VERSION ""

NS_ :

BS_:

BU_: MCTM_LS TIM_LS EOCM2cp_K2_LS EOCM2cp_K1_LS ADIMa_LS BCM_LS SAM_SR_LS SAM_SL_LS SAM_PR_LS SAM_PL_LS CGM3a_LS Dummy_LS VICM_LS ECC_LS PEPS_LS AOS_LS SDM_PR_LS AOS2_LS DLM_LS SCCM_2_LS SCCM_1_LS UPA_LS ADIMb_LS
VAL_TABLE_ vt_BooleanValues 1 "true" 0 "false" ;
VAL_TABLE_ PwrDrClsReq 1 "No Action" 0 "Power Door Close Active" ;
VAL_TABLE_ PwrDrClsEn 1 "Enable Power Door Close" 0 "No Action" ;
VAL_TABLE_ ADAllWndwMotReq 2 "Down" 1 "Up" 0 "No Action" ;
VAL_TABLE_ VehHlthMngrSt 6 "Normal Operation" 5 "Degraded Mode 5" 4 "Degraded Mode 4" 3 "Degraded Mode 3" 2 "Degraded Mode 2" 1 "Degraded Mode 1" 0 "Initialization" ;
VAL_TABLE_ AutoVehMd 5 "Failed" 4 "Autonomous Unsupervised" 3 "Supervisor Override" 2 "Autonomous Supervised" 1 "Manual" 0 "Unknown" ;
VAL_TABLE_ AutoDrvHrnReq 3 "Continuous On" 2 "Multiple" 1 "Single" 0 "Off" 4 "Vehicle Locator" ;
VAL_TABLE_ HtdStWhlCmd 3 "High" 2 "Medium" 1 "Low" 0 "Off" ;
VAL_TABLE_ HtdStWhlCtrlSrc 1 "Remote Switch Control" 0 "Local Switch Control" ;
VAL_TABLE_ HtdStWhlInd 3 "High" 2 "Medium" 1 "Low" 0 "Off" ;
VAL_TABLE_ LnMrkngIndRgt 3 "Unused and Reserved 1" 2 "Green Indicator" 1 "White Indicator" 0 "Indicator Off" ;
VAL_TABLE_ LnMrkngIndLft 3 "Unused and Reserved 1" 2 "Green Indicator" 1 "White Indicator" 0 "Indicator Off" ;
VAL_TABLE_ LnKepAsstStIndRgt 7 "Unused and Reserved 2" 6 "Unused and Reserved 1" 5 "Yellow Indicator" 4 "Red Indicator" 3 "Blue Indicator" 2 "Green Indicator" 1 "White Indicator" 0 "Indicator Off" ;
VAL_TABLE_ LnKepAsstStIndLft 7 "Unused and Reserved 2" 6 "Unused and Reserved 1" 5 "Yellow Indicator" 4 "Red Indicator" 3 "Blue Indicator" 2 "Green Indicator" 1 "White Indicator" 0 "Indicator Off" ;
VAL_TABLE_ LnKpngAstRecfblIndRq 7 "Unused and Reserved 2" 6 "Unused and Reserved 1" 5 "Yellow Solid Indicator" 4 "Yellow Flashing Indicator" 3 "Blue Solid Indicator" 2 "Green Solid Indicator" 1 "White Solid Indicator" 0 "Indicator Off" ;
VAL_TABLE_ SmrtHgBmAstCstSetReq 7 "Unused and Reserved 5" 6 "Unused and Reserved 4" 5 "Unused and Reserved 3" 4 "Unused and Reserved 2" 3 "Unused and Reserved 1" 2 "Adaptive High Beam" 1 "Auto High Beam" 0 "No Action" ;
VAL_TABLE_ SmrtHgBmAstCstCurrSetVal 7 "Unused and Reserved 5" 6 "Unused and Reserved 4" 5 "Unused and Reserved 3" 4 "Unused and Reserved 2" 3 "Unused and Reserved 1" 2 "Adaptive High Beam" 1 "Auto High Beam" 0 "No Action" ;
VAL_TABLE_ ADLR_LkUlk 2 "Unlock" 1 "Lock" 0 "No Action" ;
VAL_TABLE_ CSRCR1_Cmnd 1 "Revoke Certificate" 0 "No Action" 7 "Unused and Resrved 5" 6 "Unused and Resrved 4" 5 "Unused and Resrved 3" 4 "Unused and Resrved 2" 3 "Unused and Resrved 1" 2 "Revoke All Certificate" ;
VAL_TABLE_ CrShrngRvkCertfctRsp 4 "No CertIDs Stored" 3 "CertID Not Matched" 2 "Revoke Certificate Successful" 1 "Write Failure" 0 "No Action" ;
VAL_TABLE_ CrShrngConnStat 3 "Terminate Connection" 2 "Ignore Connection" 1 "Valid Connection" 0 "No Action" ;
VAL_TABLE_ CSZS_FrntCmptZnMbDevStat 1 "One Or More Mobile Devices Prsnt" 0 "No Mobile Device Present" ;
VAL_TABLE_ CSZS_RrCmptZnMbDevStat 1 "One Or More Mobile Devices Prsnt" 0 "No Mobile Device Present" ;
VAL_TABLE_ CSZS_FrntExtrZnMbDevStat 1 "One Or More Mobile Devices Prsnt" 0 "No Mobile Device Present" ;
VAL_TABLE_ CSZS_RrExtrZnMbDevStat 1 "One Or More Mobile Devices Prsnt" 0 "No Mobile Device Present" ;
VAL_TABLE_ CSZS_WlcmZnMbDevStat 1 "One Or More Mobile Devices Prsnt" 0 "No Mobile Device Present" ;
VAL_TABLE_ CSZS_IntrZnMbDevStat 3 "Three Mobile Devices Present" 2 "Two Mobile Devices Present" 1 "One Mobile Device Present" 0 "No Mobile Device Present" ;
VAL_TABLE_ CSZS_PassEntyZnMbDevStat 1 "One Or More Mobile Devices Prsnt" 0 "No Mobile Device Present" ;
VAL_TABLE_ CSZS_DrEntyZnMbDevStat 1 "One Or More Mobile Devices Prsnt" 0 "No Mobile Device Present" ;
VAL_TABLE_ RrStRmndrCstSetReq 2 "On" 1 "Off" 0 "No Action" ;
VAL_TABLE_ RrStRmndrCstCurrSetVal 2 "On" 1 "Off" 0 "No Action" ;
VAL_TABLE_ SmPhRmFunCstStReq 7 "Unused and Reserved 5" 6 "Unused and Reserved 4" 5 "Unused and Reserved 3" 4 "Unused and Reserved 2" 3 "Unused and Reserved 1" 2 "On" 1 "Off" 0 "No Action" ;
VAL_TABLE_ SmPhRmFunCstCurStVal 7 "Unused and Reserved 5" 6 "Unused and Reserved 4" 5 "Unused and Reserved 3" 4 "Unused and Reserved 2" 3 "Unused and Reserved 1" 2 "On" 1 "Off" 0 "No Action" ;
VAL_TABLE_ PrtyChrgRqRmt1 2 "Active" 1 "Inactive" 0 "No Action" ;
VAL_TABLE_ HVChgSyChgLvPfStRmt1 4 "Reduced Current Level 3" 3 "Reduced Current Level 2" 2 "Reduced Current Level 1" 1 "No Reduction" 0 "No Action" ;
VAL_TABLE_ HVBTBDCSRR1_DChSnSRq 3 "Yearly" 2 "Winter" 1 "Summer" 0 "No Action" ;
VAL_TABLE_ HVBTBDCSRR1_DChSlSRq 8 "Unused and Reserved 4" 7 "Departure Time 2 Invalid" 6 "Unused and Reserved 3" 5 "Departure Time 2" 4 "Unused and Reserved 2" 3 "Departure Time 1 Invalid" 2 "Unused and Reserved 1" 1 "Departure Time 1" 0 "No Action" ;
VAL_TABLE_ HVBTBDCSRR1_DChDStRq 6 "Friday" 5 "Thursday" 4 "Wednsday" 3 "Tuesday" 2 "Monday" 1 "Sunday" 0 "No Action" 10 "Sat and Sun Same" 9 "Mon To Fri Same" 8 "All Days Same" 7 "Saturday" ;
VAL_TABLE_ HVBatTmBsChgMdRqRmt1 3 "Rate Based Charge" 2 "Delayed Charge" 1 "Charge Now" 0 "No Action" ;
VAL_TABLE_ LnCntrSpchPrmtReq 3 "Unused and Reserved" 2 "Take Vehicle Control" 1 "Take Steering" 0 "No Prompt" ;
VAL_TABLE_ LnCntrEsclnStat 3 "System Faulted" 2 "Limit Condition" 1 "Driver Not Looking to Roadway" 0 "None" ;
VAL_TABLE_ HLOCCstSetReq 3 "On Open Only" 2 "On" 1 "Off" 0 "No Action" ;
VAL_TABLE_ HTRCsStReq 4 "On Away" 3 "On Home" 2 "On" 1 "Off" 0 "No Action" ;
VAL_TABLE_ HTRCsCrStVal 4 "On Away" 3 "On Home" 2 "On" 1 "Off" 0 "No Action" ;
VAL_TABLE_ EngyUsgScrnMeasUtStat 15 "Unused and Reserved 9" 14 "Unused and Reserved 8" 13 "Unused and Reserved 7" 12 "Unused and Reserved 6" 11 "Unused and Reserved 5" 10 "Unused and Reserved 4" 9 "Unused and Reserved 3" 8 "Unused and Reserved 2" 7 "Unused and Reserved 1" 6 "km/L e Combined" 5 "km/L" 4 "L/100km e Combined" 3 "L/100km" 2 "MPGe Combined" 1 "MPG" 0 "No Action" ;
VAL_TABLE_ OBHVBCCompTmDispFrmt 2 "Display Remaining Minutes To Complete" 1 "Display Completion Time" 0 "No Action" ;
VAL_TABLE_ PTExPartFltManRegStat 7 "Reserved 3" 6 "Reserved 2" 5 "Reserved 1" 4 "Complete" 3 "In Progress" 2 "Not Allowed" 1 "Allowed" 0 "Cleaning Not Required" ;
VAL_TABLE_ InfotnmntSysSt 31 " Unused and Reserved 15" 30 " Unused and Reserved 14" 29 " Unused and Reserved 13" 28 " Unused and Reserved 12" 27 " Unused and Reserved 11" 26 " Unused and Reserved 10" 25 " Unused and Reserved 9" 24 " Unused and Reserved 8" 23 " Unused and Reserved 7" 22 " Unused and Reserved 6" 21 " Unused and Reserved 5" 20 " Unused and Reserved 4" 19 " Unused and Reserved 3" 18 " Unused and Reserved 2" 17 " Unused and Reserved 1" 16 " Remote Reflash Programming" 15 " No VIN" 14 " No Calibration" 13 " Theftlocked" 12 " Valet Mode" 11 " Local Eject" 10 " Local Valet" 9 " Local Phone" 8 " Local Infotainment" 7 " Accessory" 6 " Propulsion" 5 " Run" 4 " Start" 3 " HMI Inactive" 2 " HMI Init" 1 " Animation Init" 0 " Sleep" ;
VAL_TABLE_ LnchCtrlWhlSlpReq 31 "Unused and Reserved 10" 30 "Unused and Reserved 9" 29 "Unused and Reserved 8" 28 "Unused and Reserved 7" 27 "Unused and Reserved 6" 26 "Unused and Reserved 5" 25 "Unused and Reserved 4" 24 "Unused and Reserved 3" 23 "Unused and Reserved 2" 22 "Unused and Reserved 1" 21 "Fifteen Percent" 20 "Fourteen And A Half Percent" 19 "Fourteen Percent" 18 "Thirteen And A Half Percent" 17 "Thirteen Percent" 16 "Twelve And A Half Percent" 15 "Twelve Percent" 14 "Eleven And a Half Percent" 13 "Eleven Percent" 12 "Ten And A Half Percent" 11 "Ten Percent" 10 "Nine And A Half Percent" 9 "Nine Percent" 8 "Eight And A Half Percent" 7 "Eight Percent" 6 "Seven And A Half Percent" 5 "Seven Percent" 4 "Six And A Half Percent" 3 "Six Percent" 2 "Five And A Half Percent" 1 "Five Percent" 0 "No Action" ;
VAL_TABLE_ LnchCtrlMdReq 3 "Burn Out" 2 "Custom" 1 "Automatic" 0 "No Action" ;
VAL_TABLE_ LnchCtrlEngRPMReq 24 "3100" 23 "3000" 22 "2900" 21 "2800" 20 "2700" 19 "2600" 18 "2500" 17 "2400" 16 "2300" 15 "2200" 14 "2100" 13 "2000" 12 "1900" 11 "1800" 10 "1700" 9 "1600" 8 "1500" 7 "1400" 6 "1300" 5 "1200" 4 "1100" 3 "1000" 2 "900" 1 "800" 0 "No Action" 63 "Unused and Reserved 30" 62 "Unused and Reserved 29" 61 "Unused and Reserved 28" 60 "Unused and Reserved 27" 59 "Unused and Reserved 26" 58 "Unused and Reserved 25" 57 "Unused and Reserved 24" 56 "Unused and Reserved 23" 55 "Unused and Reserved 22" 54 "Unused and Reserved 21" 53 "Unused and Reserved 20" 52 "Unused and Reserved 19" 51 "Unused and Reserved 18" 50 "Unused and Reserved 17" 49 "Unused and Reserved 16" 48 "Unused and Reserved 15" 47 "Unused and Reserved 14" 46 "Unused and Reserved 13" 45 "Unused and Reserved 12" 44 "Unused and Reserved 11" 43 "Unused and Reserved 10" 42 "Unused and Reserved 9" 41 "Unused and Reserved 8" 40 "Unused and Reserved 7" 39 "Unused and Reserved 6" 38 "Unused and Reserved 5" 37 "Unused and Reserved 4" 36 "Unused and Reserved 3" 35 "Unused and Reserved 2" 34 "Unused and Reserved 1" 33 "4000" 32 "3900" 31 "3800" 30 "3700" 29 "3600" 28 "3500" 27 "3400" 26 "3300" 25 "3200" ;
VAL_TABLE_ ECHGCD_XAxTkMrkInterv 7 "100" 6 "80" 5 "50" 4 "20" 3 "10" 2 "5" 1 "1" 0 "0.5" ;
VAL_TABLE_ ECHGCD_MeasUt 15 "Unused and Reserved 7" 14 "Unused and Reserved 6" 13 "Unused and Reserved 5" 12 "Unused and Reserved 4" 11 "Unused and Reserved 3" 10 "Unused and Reserved 2" 9 "Unused and  Reserved 1" 8 "km per L e Combined" 7 "L per 100km e Combined" 6 "MPGe Combined" 5 "L per 100km" 4 "mi per gal" 3 "km per L" 2 "kWh per 100km" 1 "mi per kWh" 0 "km per kWh" ;
VAL_TABLE_ TrfRdsdInfCsStReq 7 "Reserved5" 6 "Reserved4" 5 "Reserved3" 4 "Reserved2" 3 "Reserved1" 2 "On" 1 "Off" 0 "No Action" ;
VAL_TABLE_ CntdVehBrAltCsStReq 7 "Reserved5" 6 "Reserved4" 5 "Reserved3" 4 "Reserved2" 3 "Reserved1" 2 "On" 1 "Off" 0 "No Action" ;
VAL_TABLE_ IntrStopAlrtCsSetReq 7 "Reserved4" 6 "Reserved3" 5 "Reserved2" 4 "Reserved1" 3 "Alert and Brake" 2 "Alert " 1 "Off" 0 "No Action" ;
VAL_TABLE_ LCWrnIndReq 11 "Take Steering" 10 "Due to Weather" 9 "Can not See Eyes" 8 "Canceled Take Steering" 7 "Adaptive Cruise Disengaging" 6 "Vehicles Too Close" 5 "Excessive Speed" 4 "Construction" 3 "Freeway Ends" 2 "Tight Curve" 1 "Can not See Lanes" 0 "No Indication" 14 "Lane Following Locked Out" 13 "Service Driver Assist System" 12 "Take Vehicle Control" ;
VAL_TABLE_ LCConvMsgIndreq 31 "Reserved" 30 "Reserved" 29 "Reserved" 28 "Reserved" 27 "Reserved" 26 "Reserved" 25 "Reserved" 24 "Reserved" 23 "Reserved" 22 "Reserved" 21 "Reserved" 20 "Reserved" 19 "Show Fuel Range" 18 "Show Fuel Level" 17 "Take Time to Look at Road" 16 "Road Detour Detected" 15 "Lane Ending Ahead" 14 "Exit Only Lane Ahead" 13 "Road Exit Detected Ahead" 12 "Major Road Interchange Ahead" 11 "Slow Moving Traffic in Right Lane" 10 "Slow Moving Traffic Ahead" 9 "Slow Moving Traffic in Left Lane" 8 "Merging Vehicle" 7 "Heavy Traffic" 6 "Right Blind Spot Occupied" 5 "Left Blind Spot Occupied" 4 "Tailgater Detected" 3 "Being Passed on Right" 2 "Being Passed on Left" 1 "Behind Slow Vehicle" 0 "No Indication" ;
VAL_TABLE_ LCCIndReq 7 "Reserved" 6 "Reserved" 5 "Reserved" 4 "Red Indicator" 3 "Blue Indicator" 2 "Green Indicator" 1 "White Indicator" 0 "Indicator Off" ;
VAL_TABLE_ DgtlMapPsgRstrctn 7 "Unknown Condition" 6 "Conditional When Snow" 5 "Conditional When Wet" 4 "Condtnl Tractors Allowed  Overtake" 3 "Condtnl Passenger Car With Trailer" 2 "LED Signs" 1 "General No Overtake" 0 "No Passing Restrictions" ;
VAL_TABLE_ DgtlMapCndlSpdLmtTyp 5 "Condtnl Speed Limit Only By Rain" 4 "Condtnl Speed Limit By Time Of Day" 3 "Conditional Speed Limit Only By Day" 2 "Condtnl Speed Limit Only By Night" 1 "Conditional Speed Limit Only By Fog" 0 "Condtnl Speed Limit Lane Dependent" 7 "Unknown Conditional Speed Limit" 6 "Condtnl Speed Limit Only By Snow" ;
VAL_TABLE_ DgtlMapCndlSpdLmt 31 "Not Available" 30 "Unlimited" 29 "160 kmh_mph" 28 "150 kmh_mph" 27 "140 kmh_mph" 26 "130 kmh_mph" 25 "120 kmh_mph" 24 "115 kmh_mph" 23 "110 kmh_mph" 22 "105 kmh_mph" 21 "100 kmh_mph" 20 "95 kmh_mph" 19 "90 kmh_mph" 18 "85 kmh_mph" 17 "80 kmh_mph" 16 "75 kmh_mph" 15 "70 kmh_mph" 14 "65 kmh_mph" 13 "60 kmh_mph" 12 "55 kmh_mph" 11 "50 kmh_mph" 10 "45 kmh_mph" 9 "40 kmh_mph" 8 "35 kmh_mph" 7 "30 kmh_mph" 6 "25 kmh_mph" 5 "20 kmh_mph" 4 "15 kmh_mph" 3 "10 kmh_mph" 2 "7 kmh_mph" 1 "Less Than Or Equal To 5 km/h [mph]" 0 "Unknown" ;
VAL_TABLE_ HVChrgInhbRsn 3 "See Charging Station" 2 "Charge Cord Lock Not Engaged" 1 "Charge Cord Not Fully Inserted" 0 "No Action" ;
VAL_TABLE_ EASSI_StrtTyp 7 "Type G" 6 "Type F" 5 "Type E" 4 "Type D" 3 "Type C" 2 "Type B" 1 "Type A" 0 "No Start" ;
VAL_TABLE_ EASSI_StrtStpSt 3 "Engine Stopping" 2 "Engine Starting" 1 "Engine Running" 0 "Engine Off" ;
VAL_TABLE_ ICSTS_TchPrxmty 2 "Touch" 1 "Near" 0 "Far" ;
VAL_TABLE_ FrPedDetCsStReq 3 "Alert and Brake" 2 "Alert" 1 "Off" 0 "No Action" ;
VAL_TABLE_ FrPedDetCsCrStVal 3 "Alert and Brake" 2 "Alert" 1 "Off" 0 "No Action" ;
VAL_TABLE_ LBCVLS_VehGPSLct 4 "Vehicle Within Stored GPS Region 4" 3 "Vehicle Within Stored GPS Region 3" 2 "Vehicle Within Stored GPS Region 2" 1 "Vehicle Within Stored GPS Region 1" 0 "Vehicle Not Within Stored GPS Region" ;
VAL_TABLE_ LBCPosMdfcReq 4 "Store Position 4" 3 "Store Position 3" 2 "Store Position 2" 1 "Store Position 1" 0 "No Action" ;
VAL_TABLE_ LBCPSS_PosUpdtStat 2 "Position Modification Failed " 1 "Position  Updated  " 0 "No Action" ;
VAL_TABLE_ LBCPSS_PosUpdtLct 4 "Position 4" 3 "Position 3" 2 "Position 2" 1 "Position 1" 0 "No Action" ;
VAL_TABLE_ LBCCsStReq 2 "On" 1 "Off" 0 "No Action" ;
VAL_TABLE_ LBCCsCrStVal 2 "On" 1 "Off" 0 "No Action" ;
VAL_TABLE_ LBCCDRR_PosNumbr 4 "Position Number 4 " 3 "Position Number 3" 2 "Position Number 2" 1 "Position Number 1" 0 "No Action" ;
VAL_TABLE_ LBCCDRR_PosNum 4 "Position Number 4" 3 "Position Number 3" 2 "Position Number 2" 1 "Position Number 1" 0 "No Action" ;
VAL_TABLE_ LBCCDRR_ClrStrdPosResp 2 "Clear Position Performed" 1 "Clear Position Request Acknowledged" 0 "No Action" ;
VAL_TABLE_ LBCCDRR_ClrStrdPosReq 2 "Confirmation to Clear Position" 1 "Request to Clear Position" 0 "No Action" ;
VAL_TABLE_ ElecShfRngDisp 15 "Unused and Reserved 3" 14 "Unused and Reserved 2" 13 "Unused and Reserved 1" 12 "Park Requested And Denied" 11 "Drive Requested And In Progress" 10 "Neutral Requested And In Progress" 9 "Reverse Requested And In Progress" 8 "Park Requested And In Progress" 7 "Reserved" 6 "Manual Nominal" 5 "Low Nominal" 4 "Drive Nominal" 3 "Neutral Nominal" 2 "Reverse Nominal" 1 "Park Nominal" 0 "No Display " ;
VAL_TABLE_ RrPedDetCstStReq 7 "Reserved3" 6 "Reserved2" 5 "Reserved1" 4 "Alert and Brake" 3 "Alert" 2 "On" 1 "Off" 0 "No Action" ;
VAL_TABLE_ NVSysStat 7 "Needs Headlights" 6 "Temporarily Unavailable" 5 "Not Dark" 4 "Needs Service" 3 "Active" 2 "Inactive" 1 "Initializing" 0 "Unknown" ;
VAL_TABLE_ IntDimSeldClrTypStVal 31 "Color Type 30" 30 "Color Type 29" 29 "Color Type 28" 28 "Color Type 27" 27 "Color Type 26" 26 "Color Type 25" 25 "Color Type 24" 24 "Color Type 23" 23 "Color Type 22" 22 "Color Type 21" 21 "Color Type 20" 20 "Color Type 19" 19 "Color Type 18" 18 "Color Type 17" 17 "Color Type 16" 16 "Color Type 15" 15 "Color Type 14" 14 "Color Type 13" 13 "Color Type 12" 12 "Color Type 11" 11 "Color Type 10" 10 "Color Type 9" 9 "Color Type 8" 8 "Color Type 7" 7 "Color Type 6" 6 "Color Type 5" 5 "Color Type 4" 4 "Color Type 3" 3 "Color Type 2" 2 "Color Type 1" 1 "Off" 0 "No Action" ;
VAL_TABLE_ IntDimSeldClrTypStReq 19 "Color Type 18" 31 "Color Type 30" 30 "Color Type 29" 29 "Color Type 28" 28 "Color Type 27" 27 "Color Type 26" 26 "Color Type 25" 25 "Color Type 24" 24 "Color Type 23" 23 "Color Type 22" 22 "Color Type 21" 21 "Color Type 20" 20 "Color Type 19" 18 "Color Type 17" 17 "Color Type 16" 16 "Color Type 15" 15 "Color Type 14" 14 "Color Type 13" 13 "Color Type 12" 12 "Color Type 11" 11 "Color Type 10" 10 "Color Type 9" 9 "Color Type 8" 8 "Color Type 7" 7 "Color Type 6" 6 "Color Type 5" 5 "Color Type 4" 4 "Color Type 3" 3 "Color Type 2" 2 "Color Type 1" 1 "Off" 0 "No Action" ;
VAL_TABLE_ IntDimSeldAnmTypStVal 15 "Animation Type 14" 14 "Animation Type 13" 13 "Animation Type 12" 12 "Animation Type 11" 11 "Animation Type 10" 10 "Animation Type 9" 9 "Animation Type 8" 8 "Animation Type 7" 7 "Animation Type 6" 6 "Animation Type 5" 5 "Animation Type 4" 4 "Animation Type 3" 3 "Animation Type 2" 2 "Animation Type 1" 1 "Off" 0 "No Action" ;
VAL_TABLE_ IntDimSeldAnmTypStReq 15 "Animation Type 14" 14 "Animation Type 13" 13 "Animation Type 12" 12 "Animation Type 11" 11 "Animation Type 10" 10 "Animation Type 9" 9 "Animation Type 8" 8 "Animation Type 7" 7 "Animation Type 6" 6 "Animation Type 5" 5 "Animation Type 4" 4 "Animation Type 3" 3 "Animation Type 2" 2 "Animation Type 1" 1 "Off" 0 "No Action" ;
VAL_TABLE_ APAIconDispRq 7 "Unused & Reserved" 6 "Unused & Reserved" 5 "Unused & Reserved" 4 "Complete" 3 "Stop" 2 "Reverse" 1 "Forward" 0 "No Icon" ;
VAL_TABLE_ RtBsChrgCmplnTmPrfRsp 2 "Latest Possible" 1 "Earliest Possible" 0 "No Action" ;
VAL_TABLE_ RtBsChrgCmplnTmPrfReq 2 "Latest Possible" 1 "Earliest Possible" 0 "No Action" ;
VAL_TABLE_ ILSSCommErr 1 "Comm Error Detected" 0 "No Comm Error" ;
VAL_TABLE_ ExtHlStrAssCsStRq 2 "Standard Hold" 1 "Extended Hold" 0 "No Action" ;
VAL_TABLE_ RtLnDepWrnSt 3 "Service Alignment" 2 "Right Lane Alert" 1 "Right Lane Ready to Assist" 0 "Right Lane Not Ready to Assist" ;
VAL_TABLE_ LftLnDepWrnSt 3 "Service Alignment" 2 "Left Lane Alert" 1 "Left Lane Ready to Assist" 0 "Left Lane Not Ready to Assist" ;
VAL_TABLE_ PedWrnIndReq 3 "Reserved " 2 "Pedestrian alert" 1 "Pedestrian detected" 0 "None" ;
VAL_TABLE_ SpdLmtrSttngTypAct 3 "Reserved" 2 "Auto" 1 "Manual" 0 "Off" ;
VAL_TABLE_ SetSpdLmtRchd 3 "Reserved" 2 "Low limit reached" 1 "High limit reached" 0 "No limit reached" ;
VAL_TABLE_ ClmtCtrlHtrEngRunRq 1 "Engine Run Requested" 0 "No Action" ;
VAL_TABLE_ DrvSelMd8Stat 1 "Active" 0 "Inactive" ;
VAL_TABLE_ DrvSelMd7Stat 1 "Active" 0 "Inactive" ;
VAL_TABLE_ DrvSelMd6Stat 1 "Active" 0 "Inactive" ;
VAL_TABLE_ DrvSelMd5Stat 1 "Active" 0 "Inactive" ;
VAL_TABLE_ DrvSelMd4Stat 1 "Active" 0 "Inactive" ;
VAL_TABLE_ DrvSelMd3Stat 1 "Active" 0 "Inactive" ;
VAL_TABLE_ DrvSelMd2Stat 1 "Active" 0 "Inactive" ;
VAL_TABLE_ MntnceMdDsplyRq 15 "Unused and Reserved" 14 "Continue FM" 13 "Force FM" 12 "FM 1 Day Warning" 11 "FM 2 Day Warning" 10 "FM 3 Day Warning" 9 "FM 4 Day Warning" 8 "FM 5 Day Warning" 7 "Continue EM" 6 "Force EM" 5 "EM 1 Day Warning" 4 "EM 2 Day Warning" 3 "EM 3 Day Warning" 2 "EM 4 Day Warning" 1 "EM 5 Day Warning" 0 "No Request" ;
VAL_TABLE_ AuxClntHtrVlvStat 7 "Unused and Reserved 2" 6 "De-Aeration Routine Active" 5 "Diagnostic Override" 4 "Re-Calibration" 3 "Fault Active" 2 "Engine Link" 1 "Transition" 0 "Engine Bypass" ;
VAL_TABLE_ DrvSelMd1Stat 1 "Active" 0 "Inactive" ;
VAL_TABLE_ HybChrgMdStat 3 "Unused and reserved 2" 2 "Unused and reserved 1" 1 "Charge Sustaining" 0 "Charge Depleting" ;
VAL_TABLE_ HybMdDisp 15 "Engine Charging Battery While Idle" 14 "Engine Charging Battery Moving" 13 "Engine Power Load Sharing" 12 "Battery Power Load Sharing" 11 "Undetermined" 10 "Charging With Engine On" 9 "Charging With Engine Off" 8 "Hybrid Power 4WD" 7 "Hybrid Power 2WD" 6 "Engine Power 4WD" 5 "Engine Power 2WD" 4 "Battery Power 4WD" 3 "Battery Power 2WD" 2 "Auto Stop" 1 "Engine Idle" 0 "Default / Accessory" ;
VAL_TABLE_ PMVSS_Trans 7 "Visualization Type 7" 6 "Visualization Type 6" 5 "Visualization Type 5" 4 "Visualization Type 4" 3 "Visualization Type 3" 2 "Visualization Type 2" 1 "Visualization Type 1" 0 "No Action" ;
VAL_TABLE_ PMVSS_Susp 7 "Visualization Type 7" 6 "Visualization Type 6" 5 "Visualization Type 5" 4 "Visualization Type 4" 3 "Visualization Type 3" 2 "Visualization Type 2" 1 "Visualization Type 1" 0 "No Action" ;
VAL_TABLE_ PMVSS_Strng 7 "Visualization Type 7" 6 "Visualization Type 6" 5 "Visualization Type 5" 4 "Visualization Type 4" 3 "Visualization Type 3" 2 "Visualization Type 2" 1 "Visualization Type 1" 0 "No Action" ;
VAL_TABLE_ PMVSS_Snd 7 "Visualization Type 7" 6 "Visualization Type 6" 5 "Visualization Type 5" 4 "Visualization Type 4" 3 "Visualization Type 3" 2 "Visualization Type 2" 1 "Visualization Type 1" 0 "No Action" ;
VAL_TABLE_ PMVSS_PsngrSeat 7 "Visualization Type 7" 6 "Visualization Type 6" 5 "Visualization Type 5" 4 "Visualization Type 4" 3 "Visualization Type 3" 2 "Visualization Type 2" 1 "Visualization Type 1" 0 "No Action" ;
VAL_TABLE_ PMVSS_Exhst 7 "Visualization Type 7" 6 "Visualization Type 6" 5 "Visualization Type 5" 4 "Visualization Type 4" 3 "Visualization Type 3" 2 "Visualization Type 2" 1 "Visualization Type 1" 0 "No Action" ;
VAL_TABLE_ PMVSS_Eng 7 "Visualization Type 7" 6 "Visualization Type 6" 5 "Visualization Type 5" 4 "Visualization Type 4" 3 "Visualization Type 3" 2 "Visualization Type 2" 1 "Visualization Type 1" 0 "No Action" ;
VAL_TABLE_ PMVSS_DrvrSeat 7 "Visualization Type 7" 6 "Visualization Type 6" 5 "Visualization Type 5" 4 "Visualization Type 4" 3 "Visualization Type 3" 2 "Visualization Type 2" 1 "Visualization Type 1" 0 "No Action" ;
VAL_TABLE_ PMVSS_Drvln 7 "Visualization Type 7" 6 "Visualization Type 6" 5 "Visualization Type 5" 4 "Visualization Type 4" 3 "Visualization Type 3" 2 "Visualization Type 2" 1 "Visualization Type 1" 0 "No Action" ;
VAL_TABLE_ PMVSS_Disps 7 "Visualization Type 7" 6 "Visualization Type 6" 5 "Visualization Type 5" 4 "Visualization Type 4" 3 "Visualization Type 3" 2 "Visualization Type 2" 1 "Visualization Type 1" 0 "No Action" ;
VAL_TABLE_ PMVSS_AdptCrsCnt 7 "Visualization Type 7" 6 "Visualization Type 6" 5 "Visualization Type 5" 4 "Visualization Type 4" 3 "Visualization Type 3" 2 "Visualization Type 2" 1 "Visualization Type 1" 0 "No Action" ;
VAL_TABLE_ PsngStPerfMdCsStReq 7 "Auto" 6 "Performance Mode 6" 5 "Performance Mode 5" 4 "Performance Mode 4" 3 "Performance Mode 3" 2 "Performance Mode 2" 1 "Performance Mode 1" 0 "No Action" ;
VAL_TABLE_ DrvrStPerfMdCsStReq 7 "Auto" 6 "Performance Mode 6" 5 "Performance Mode 5" 4 "Performance Mode 4" 3 "Performance Mode 3" 2 "Performance Mode 2" 1 "Performance Mode 1" 0 "No Action" ;
VAL_TABLE_ DrvStyPerfMdCsStReq 7 "Performance Mode 7" 6 "Performance Mode 6" 5 "Performance Mode 5" 4 "Performance Mode 4" 3 "Performance Mode 3" 2 "Performance Mode 2" 1 "Performance Mode 1" 0 "No Action" ;
VAL_TABLE_ ACCPerfMdCsStReq 7 "Auto" 6 "Performance Mode 6" 5 "Performance Mode 5" 4 "Performance Mode 4" 3 "Performance Mode 3" 2 "Performance Mode 2" 1 "Performance Mode 1" 0 "No Action" ;
VAL_TABLE_ ACCGrnMdStat 0 "Not Active" 1 "Ready to Assist" 2 "(Curve / Urban / Slope) Active" 3 "Temporarily not Available" ;
VAL_TABLE_ TCTPIR_DrvNotfn 15 "Indication 15" 14 "Indication 14" 13 "Indication 13" 12 "Indication 12" 11 "Indication 11" 10 "Indication 10" 9 "Indication 9" 8 "Indication 8" 7 "Indication 7" 6 "Indication 6" 5 "Indication 5" 4 "Indication 4" 3 "Indication 3" 2 "Indication 2" 1 "Indication 1" 0 "No Indication" ;
VAL_TABLE_ CrsSpdLmtrSwStat 9 "Between Ranges" 8 "Short to Power" 7 "Open/Short to Ground" 6 "Cancel" 5 "Cruise On/Off" 4 "SL/SW On/Off/GAP" 3 "Set" 2 "Resume" 1 "No Activation" 0 "Indeterminate" ;
VAL_TABLE_ VehRefuelSt 7 "Unused and Reserved 4" 6 "Unused and Reserved 3" 5 "Unused and Reserved 2" 4 "Unused and Reserved 1" 3 "Close Fuel Door" 2 "Ready To Refuel" 1 "Wait To Refuel" 0 "Inactive" ;
VAL_TABLE_ SpdLmtUnits 1 "km/h" 0 "mph" ;
VAL_TABLE_ CurvAdvInd 3 "Winding Road" 2 "Right Turn" 1 "Left Turn" 0 "No Advisory" ;
VAL_TABLE_ ACCmEngRunReq 1 "Engine Run Requested" 0 "No Action" ;
VAL_TABLE_ PsvEntCmftWndRq 3 "Reserved" 2 "Comfort Open" 1 "Comfort Close" 0 "No Action" ;
VAL_TABLE_ RRWndPosSt 6 "Fully Opened" 5 "Open More Than C" 4 "Position C" 3 "Posistion B" 2 "Posistion A" 1 "Open Less Than A" 0 "Fully Closed" ;
VAL_TABLE_ PsWndPosSt 6 "Fully Opened" 5 "Open More Than C" 4 "Position C" 3 "Posistion B" 2 "Posistion A" 1 "Open Less Than A" 0 "Fully Closed" ;
VAL_TABLE_ LRWndPosSt 6 "Fully Opened" 5 "Open More Than C" 4 "Position C" 3 "Posistion B" 2 "Posistion A" 1 "Open Less Than A" 0 "Fully Closed" ;
VAL_TABLE_ DrvWndPosSt 6 "Fully Opened" 5 "Open More Than C" 4 "Position C" 3 "Posistion B" 2 "Posistion A" 1 "Open Less Than A" 0 "Fully Closed" ;
VAL_TABLE_ ASS2AudSrcType 28 "Phone" 24 "Sat. Digital Audio Receiver System" 20 "Digital Audio Broadcast" 16 "Remote CD Changer" 12 "Remote Digital Video Disk" 8 "Auxiliary Device" 1 "Television Tuner" ;
VAL_TABLE_ FrntPassClass 7 "Large Adult" 6 "Small Adult" 5 "Large Child" 4 "Small Child" 3 "Child Seat Unknown" 2 "Child Seat Forward" 1 "Child Seat Rearward" 0 "Classification Not Applicable" ;
VAL_TABLE_ EPBSysWrnIndReq 3 "Flash Rate #2 Indication" 2 "Flash Rate #1 Indication" 1 "Continuous Indication" 0 "No Indication" ;
VAL_TABLE_ KSARUID7 0 "Not Present" 1 "Present" ;
VAL_TABLE_ KSARUID5 1 "Present" 0 "Not Present" ;
VAL_TABLE_ KSARUID6 1 "Present" 0 "Not Present" ;
VAL_TABLE_ KSARUID8 1 "Present" 0 "Not Present" ;
VAL_TABLE_ KSARUID3 1 "Present" 0 "Not Present" ;
VAL_TABLE_ KSARUID4 1 "Present" 0 "Not Present" ;
VAL_TABLE_ KSARUID2 1 "Present" 0 "Not Present" ;
VAL_TABLE_ KSARUID1 1 "Present" 0 "Not Present" ;
VAL_TABLE_ ClmnLckTT 2 "Flashing Indication" 1 "Continuous Indication" 0 "No Indication" ;
VAL_TABLE_ SecAxlOpeMod 3 "Active All Wheel Drive (High)" 2 "4 Wheel Drive Low Locked" 1 "4 Wheel Drive High Locked" 0 "2 Wheel Drive High" 15 "Neutral" 14 "Unknown" 7 "2 Wheel Drive Low" 6 "Active All Wheel Drive (Low)" 5 "4 Wheel Drive Low Open" 4 "4 Wheel Drive High Open" ;
VAL_TABLE_ EPBSta 2 "Fault" 1 "Applied" 0 "Released" ;
VAL_TABLE_ TransTUDMdStat 2 "Electronic Range Select Active" 1 "Driver Shift Control Active" 0 "No Activation" ;
VAL_TABLE_ TrnShftPtrnActStat 6 "PT Protection Pattern Active" 5 "PT Non-Protection Pattern Active" 4 "Shift Pattern 4 Active" 3 "Shift Pattern 3 Active" 2 "Shift Pattern 2 Active" 1 "Shift Pattern 1 Active" 0 "Default Shift Pattern Active" ;
VAL_TABLE_ EPBSysAudWarnReq 2 "Warning #2" 1 "Warning #1" 0 "Off" ;
VAL_TABLE_ NotSecRowRtSeaOccStat 2 "Occupied" 1 "Empty" 0 "Unknown" ;
VAL_TABLE_ NotSecRowLeSeaOccStat 2 "Occupied" 1 "Empty" 0 "Unknown" ;
VAL_TABLE_ NotSecRowCtSeaOccStat 2 "Occupied" 1 "Empty" 0 "Unknown" ;
VAL_TABLE_ NotiFrntPasSeatOccSta 5 "OccupiedLarge" 4 "OccupiedSmall" 3 "OccupiedChildseat" 2 "OccupiedUnknown" 1 "Empty" 0 "Unknown" ;
VAL_TABLE_ NotEventSta 2 "Pretensioner Deployment Event" 1 "Near Deployment Event" 0 "No Event" 3 "Airbag Deployment Event" ;
VAL_TABLE_ VehMovSta 4 "Invalid" 3 "Reverse" 2 "Forward" 1 "Neutral" 0 "Parked" ;
VAL_TABLE_ SeReOcSt 1 "Occupied" 0 "Empty" ;
VAL_TABLE_ SeReCoOcSt 2 "Occupied" 1 "Empty" 0 "Unknown" ;
VAL_TABLE_ DispMeasSysExt 2 "Imperial" 1 "US" 0 "Metric" ;
VAL_TABLE_ RRHCSMIndReq 3 "Flash Rate #2 Indication" 2 "Flash Rate #1 Indication" 1 "Continuous Indication" 0 "Off" ;
VAL_TABLE_ RRHCSLIndReq 3 "Flash Rate #2 Indication" 2 "Flash Rate #1 Indication" 1 "Continuous Indication" 0 "Off" ;
VAL_TABLE_ RLHCSMIndReq 3 "Flash Rate #2 Indication" 2 "Flash Rate #1 Indication" 1 "Continuous Indication" 0 "Off" ;
VAL_TABLE_ RLHCSLIndReq 3 "Flash Rate #2 Indication" 2 "Flash Rate #1 Indication" 1 "Continuous Indication" 0 "Off" ;
VAL_TABLE_ PrkAstRrSysStat 3 "Failed" 2 "Inhibited" 1 "Enabled" 0 "Disabled" ;
VAL_TABLE_ PrkAstFrSysStat 3 "Failed" 2 "Inhibited" 1 "Enabled" 0 "Disabled" ;
VAL_TABLE_ PARgnObjStat 15 "Zone 15" 14 "Zone 14" 13 "Zone 13" 12 "Zone 12" 11 "Zone 11" 10 "Zone 10" 9 "Zone 9" 8 "Zone 8" 7 "Zone 7" 6 "Zone 6" 5 "Zone 5" 4 "Zone 4" 3 "Zone 3" 2 "Zone 2" 1 "Zone 1" 0 "No Object" ;
VAL_TABLE_ LDWIC_LnDepWAWLn 2 "Right Front Speaker" 1 "Left Front Speaker" 0 "Off" ;
VAL_TABLE_ LDWIC_IndReq 2 "Flash Rate #1 Indication" 1 "Continuous Indication" 0 "Off" ;
VAL_TABLE_ PassHCSMIndReq 3 "Flash Rate #2 Indication" 2 "Flash Rate #1 Indication" 1 "Continuous Indication" 0 "Off" ;
VAL_TABLE_ PassHCSLIndReq 3 "Flash Rate #2 Indication" 2 "Flash Rate #1 Indication" 1 "Continuous Indication" 0 "Off" ;
VAL_TABLE_ DrvHCSMIndReq 3 "Flash Rate #2 Indication" 2 "Flash Rate #1 Indication" 1 "Continuous Indication" 0 "Off" ;
VAL_TABLE_ DrvHCSLIndReq 3 "Flash Rate #2 Indication" 2 "Flash Rate #1 Indication" 1 "Continuous Indication" 0 "Off" ;
VAL_TABLE_ MmryRclImpctDisRq 0 "Enable Recall" 1 "Disable Recall" ;
VAL_TABLE_ HdSt 2 "Open" 1 "Ajar" 0 "Closed" ;
VAL_TABLE_ CmpsOctHdingDataSrc 1 "Calculated Value" 0 "Stored Value" ;
VAL_TABLE_ CmpsOctHding 7 "NW (North West)" 6 "W (West)" 5 "SW (South West)" 4 "S (South)" 3 "SE (South East)" 2 "E (East)" 1 "NE (North East)" 0 "N (North)" ;
VAL_TABLE_ CmpsDecZone 15 "Zone 15" 14 "Zone 14" 13 "Zone 13" 12 "Zone 12" 11 "Zone 11" 10 "Zone 10" 9 "Zone 9" 8 "Zone 8" 7 "Zone 7" 6 "Zone 6" 5 "Zone 5" 4 "Zone 4" 3 "Zone 3" 2 "Zone 2" 1 "Zone 1" 0 "Unknown" ;
VAL_TABLE_ EnvIdRspSt1 3 "Environment_id_request" 2 "Incorrect_immo_id" 1 "Info_valid" 0 "No_info" ;
VAL_TABLE_ FrPsSeatOccFltSt 2 "Fault Present - Vehicle Mismatch" 1 "Fault Present" 0 "No Faults Present" ;
VAL_TABLE_ FrPsSeatOccSnsOpMd 3 "SystemInitMod" 2 "BarrierMod" 1 "ZeroSetCheckMod" 0 "FieldMod" ;
VAL_TABLE_ PhnSpRcgnApSt 3 "Unused" 2 "Audio Prompt Active" 1 "Speech Rec Active" 0 "Inactive" ;
VAL_TABLE_ CmpsModSlfTstReq 1 "Initiate Self Test" 0 "No Action" ;
VAL_TABLE_ CmpsModManCalReq 1 "Calibrate Sensor" 0 "No Action" ;
VAL_TABLE_ CmpsDecZonSetReq 1 "Set New Zone" 0 "No Request" ;
VAL_TABLE_ CmpsDecZonCmndVal 15 "Zone 15" 14 "Zone 14" 13 "Zone 13" 12 "Zone 12" 11 "Zone 11" 10 "Zone 10" 9 "Zone 9" 8 "Zone 8" 7 "Zone 7" 6 "Zone 6" 5 "Zone 5" 4 "Zone 4" 3 "Zone 3" 2 "Zone 2" 1 "Zone 1" 0 "Unknown" ;
VAL_TABLE_ AuxHtrRq 1 "On" 0 "Off" ;
VAL_TABLE_ TrnsEngdState 3 "Operating State Not Reached" 2 "Transmission Engaged in Reverse" 1 "Transmission Engaged in Forward" 0 "Transmission Not Engaged" ;
VAL_TABLE_ EnhSrvVisAlRq 3 "Repeated Flash" 2 "Single Flash" 1 "Off" 0 "No Action" ;
VAL_TABLE_ EnhSrvRmStrtRq 2 "Engine Requested On" 1 "Engine Requested Off" 0 "No Activation" ;
VAL_TABLE_ EnhSrvRClsRlsRq 1 "Release" 0 "No Action" ;
VAL_TABLE_ EnhSrvLckRq 5 "Undeadbolt All" 4 "Deadbolt All" 3 "Unlock All" 2 "Unlock Driver Door" 1 "Lock All" 0 "No Action" ;
VAL_TABLE_ EnhSrvAudAlRq 3 "Alarm" 2 "Chirp" 1 "Off" 0 "No Action" ;
VAL_TABLE_ EPBSysDspMsgReq 7 "Message #7" 6 "Message #6" 5 "Message #5" 4 "Message #4" 3 "Message #3" 2 "Message #2" 1 "Message #1" 0 "Off" ;
VAL_TABLE_ VhSecNImmoIndRq 2 "Flashing Indication" 1 "Continuous Indication" 0 "No Indication" ;
VAL_TABLE_ FPSIC_IndPer 15 "8.0 s" 14 "7.0 s" 13 "6.0 s" 12 "5.0 s" 11 "4.0 s" 10 "3.5 s" 9 "3.0 s" 8 "2.5 s" 7 "2.0 s" 6 "1.75 s" 5 "1.50 s" 4 "1.25 s" 3 "1.0 s" 2 "0.75 s" 1 "0.5 s" 0 "0.25 s" ;
VAL_TABLE_ FDSIC_IndPer 15 "8.0 s" 14 "7.0 s" 13 "6.0 s" 12 "5.0 s" 11 "4.0 s" 10 "3.5 s" 9 "3.0 s" 8 "2.5 s" 7 "2.0 s" 6 "1.75 s" 5 "1.50 s" 4 "1.25 s" 3 "1.0 s" 2 "0.75 s" 1 "0.5 s" 0 "0.25 s" ;
VAL_TABLE_ FsnPsStbAuxIR 4 "Child Warning Level 2" 3 "Child Warning Level 1" 2 "Adult Warning Level 2" 1 "Adult Warning Level 1" 0 "No Indication" ;
VAL_TABLE_ FstnSndRwRtPsStbtInR 3 "Unbuckled information indication" 2 "Buckled Indication" 1 "Unbuckled Indication" 0 "No Indication" ;
VAL_TABLE_ FstnSndRwLtPsStbtInR 3 "Unbuckled information indication" 2 "Buckled Indication" 1 "Unbuckled Indication" 0 "No Indication" ;
VAL_TABLE_ FstnSndRwCtPsStbtInR 3 "Unbuckled information indication" 2 "Buckled Indication" 1 "Unbuckled Indication" 0 "No Indication" ;
VAL_TABLE_ FsnDrStbAuxIR 2 "Warning Level 2" 1 "Warning Level 1" 0 "No Indication" ;
VAL_TABLE_ BackgroundFlag 1 "Background response" 0 "Immediate response required" ;
VAL_TABLE_ TrRrAxlPresStat 2 "Tire Pressure Imbalance Warning" 1 "Tire Pressure Balanced" 0 "Unknown" ;
VAL_TABLE_ TrFrntAxlPresStat 2 "Tire Pressure Imbalance Warning" 1 "Tire Pressure Balanced" 0 "Unknown" ;
VAL_TABLE_ DisplayMaskId 128 "Reserved" 64 "Reserved" 32 "OTIM" 16 "RearDisplayTwo" 8 "RearDisplayOne" 4 "AuxIP" 2 "CenterStack" 1 "IPC" ;
VAL_TABLE_ ODIReqType 0 "Subscribe: FU sends DynData back and then on change) " 1 "Unsubscribe: cancel previous Subscribe" ;
VAL_TABLE_ OtsdAmbtLtLvlStat 2 "Day" 1 "Night" 0 "Unknown" ;
VAL_TABLE_ ASS2AudSrcStatCode 5 "Producing Audio" 4 "Producing Silence" 3 "Reserved" 2 "Audio Not Available" 1 "Audio Available" 0 "Device Present" ;
VAL_TABLE_ ASS2AudSrcChType 4 "Mono Emergency" 3 "Mixed" 2 "Stereo" 1 "Mono" 0 "No Action" ;
VAL_TABLE_ RdSpdCatType 3 "all speed categories 0 - 50 km/h" 2 "all speed categories 51-80 km/h" 1 "all speed categories 81-130 km/h" 0 "all speed categories > 130 km/h" ;
VAL_TABLE_ LnCat 3 "Four Or More Lanes" 2 "Two Or Three Lanes" 1 "One lane" 0 "no info available" ;
VAL_TABLE_ FncRdClass 7 "COLLECTOR" 6 "ALLEY" 5 "ARTERIAL" 4 "HIGHWAY" 3 "PED-MALL" 2 "FREEWAY" 1 "SFREEWAY" 0 "LOCAL (Residential Road)" ;
VAL_TABLE_ CustomizationSettingRequest 4 "Performance Mode 4" 3 "Performance Mode 3" 2 "Performance Mode 2" 1 "Performance Mode 1" 0 "No Action" 7 "Auto" 6 "Performance Mode 6" 5 "Performance Mode 5" ;
VAL_TABLE_ RstrCustFctrDef 1 "Restore Defaults" 0 "No Action" ;
VAL_TABLE_ PsvStrtStrngClmnLckTT 2 "Flashing Indication" 1 "Continous Indication" 0 "No indication" ;
VAL_TABLE_ ODIDataType 21 "Bitmap" 20 "DecimalShort" 19 "HoursOfDay" 18 "Character" 17 "Fuel Consumption Inverted" 16 "Fuel Consumption" 15 "Pressure" 14 "Temperature" 13 "Volume" 12 "DistanceShort" 11 "DistanceLong" 10 "BitmapId" 9 "TextId" 8 "Pictogram" 7 "List " 6 "Date" 5 "Time " 4 "Decimal" 3 "EnumerationValue" 2 "Integer" 1 "String" 0 "Speed" ;
VAL_TABLE_ TimeDispFormat 1 "24 hour mode" 0 "12 hour mode" ;
VAL_TABLE_ EPBSysStatIndReq 3 "Flash Rate 2 Indication" 2 "Flash Rate 1 Indication" 1 "Continuous Indication" 0 "No Indication" ;
VAL_TABLE_ ClntCircPmpRq 1 "On" 0 "Off" ;
VAL_TABLE_ ImoIdSt 1 "Info valid" 0 "No info" ;
VAL_TABLE_ A2ERRAlrmReq 2 "Cancel Alarm" 1 "Set Alarm" 0 "No Action" ;
VAL_TABLE_ LrnEnvIdSt 1 "Info_valid" 0 "No_info" ;
VAL_TABLE_ EnvIdRspSt3 3 "Environment_id_request" 2 "Incorrect_immo_id" 1 "Info_valid" 0 "No_info" ;
VAL_TABLE_ EnvIdRspSt2 3 "Environment_id_request" 2 "Incorrect_immo_id" 1 "Info_valid" 0 "No_info" ;
VAL_TABLE_ VDAvailability 1 "VirtualDeviceAvailable" 0 "VirtualDeviceUnavailable" ;
VAL_TABLE_ MaskStates 1 "Use Data" 0 "Don't Use Data" ;
VAL_TABLE_ RemStrtSt 1 "Active" 0 "Inactive" ;
VAL_TABLE_ EhnSrvEngImmStat 1 "Immobilized" 0 "Not Immobilized" ;
VAL_TABLE_ AlrmStat 4 "Arming Delay" 3 "Alarm Active" 2 "Disarmed" 1 "Armed" 0 "Off" ;
VAL_TABLE_ DrIdDevLrnd 1 "Learned" 0 "Not Learned" ;
VAL_TABLE_ StrgWhlUnit1SwStat 15 "Function #F" 14 "Function #E" 13 "Function #D" 12 "Function #C" 11 "Function #B" 10 "Function #A" 9 "Function #9" 8 "Function #8" 7 "Function #7" 6 "Function #6" 5 "Function #5" 4 "Function #4" 3 "Function #3" 2 "Function #2" 1 "Function #1" 0 "No Activation" ;
VAL_TABLE_ AirbgICIndPer 15 "8.0 s" 14 "7.0 s" 13 "6.0 s" 12 "5.0 s" 11 "4.0 s" 10 "3.5 s" 9 "3.0 s" 8 "2.5 s" 7 "2.0 s" 6 "1.75" 5 "1.5 s" 4 "1.25 s" 3 "1.0 s" 2 ".75 s" 1 ".5 s" 0 "0.25 s" ;
VAL_TABLE_ StrgWhlUnit2SwStat 15 "Function #F" 14 "Function #E" 13 "Function #D" 12 "Function #C" 11 "Function #B" 10 "Function #A" 9 "Function #9" 8 "Function #8" 7 "Function #7" 6 "Function #6" 5 "Function #5" 4 "Function #4" 3 "Function #3" 2 "Function #2" 1 "Function #1" 0 "No Activation" ;
VAL_TABLE_ RstVTDTmprDtctd 1 "Reset" 0 "No Action" ;
VAL_TABLE_ RstIllDrIdDevDtctd 1 "Reset" 0 "No Action" ;
VAL_TABLE_ RstDrIdDevLrnd 1 "Reset" 0 "No Action" ;
VAL_TABLE_ ESEIC_EngImmbRq 1 "Immobilize" 0 "Do Not Immobilize" ;
VAL_TABLE_ CldrMth 12 "December" 11 "November" 10 "October" 9 "September" 8 "August" 7 "July" 6 "June" 5 "May" 4 "April" 3 "March" 2 "February" 1 "January" 0 "Unknown" ;
VAL_TABLE_ FobProgMdStat 2 "Complete" 1 "Active" 0 "Inactive" ;
VAL_TABLE_ RmtCntFobNm 5 "Remote Control Fob #5" 4 "Remote Control Fob #4" 3 "Remote Control Fob #3" 2 "Remote Control Fob #2" 1 "Remote Control Fob #1" 0 "No Fob" ;
VAL_TABLE_ ACHtIdleBstLevReq 3 "Boost Level 3" 2 "Boost Level 2" 1 "Boost Level 1" 0 "No Boost Requested" ;
VAL_TABLE_ BattVltIRq 3 "Battery Voltage Very Low" 2 "Battery Voltage High" 1 "Battery Voltage Low" 0 "Battery Voltage OK" ;
VAL_TABLE_ TrnSwAct 2 "Right" 1 "Left" 0 "No Activation" ;
VAL_TABLE_ RtTrnLmpAtv 2 "On with telltale" 1 "On without telltale" 0 "Off" ;
VAL_TABLE_ LftTrnLmpAtv 2 "On with telltale" 1 "On without telltale" 0 "Off" ;
VAL_TABLE_ RmtCntrlFobFnc 31 "Charge Termination" 30 "Pwr Top Control Start Motion Contrl" 29 "Pwr Top Control Stop Motion Control" 28 "Comfort Close 2" 27 "Comfort Open 2" 26 "Connectivity Request" 25 "Comfort Close" 24 "Comfort Open" 23 "Right Sliding Dr Stop Motion Contrl" 22 "Left Sliding Dr Stop Motion Control" 21 "Pwr Rr Closure Start Motion Control" 20 "Pwr Rr Closure Stop Motion Control" 19 "All Door Double Lock" 18 "Pwr Rr Closure Stop While Opening" 17 "Pwr Rr Closure Stop While Closing" 16 "Power Rear Closure Open Control" 15 "Power Rear Closure Close Control" 14 "Locator Alarm Control" 13 "Fob Programmed" 12 "Engine Stop" 11 "Engine Run" 10 "Power Top Control" 9 "Power Window Control" 8 "Fuel Door Control" 7 "Panic Alarm Control" 6 "Right Sliding Door Control" 5 "Left Sliding Door Control" 4 "Rear Closure Control" 3 "All Door Unlock" 2 "Driver Door Unlock" 1 "Lock" 0 "No Activation" ;
VAL_TABLE_ AutoBmSlctStat 1 "Low  Beam" 0 "Disabled" 2 "High Beam" ;
VAL_TABLE_ StrgColLckCmd 3 "Failure Code Retrieval Required" 2 "Lock" 1 "Unlock" 0 "No Command" ;
VAL_TABLE_ HdlmpBmSelectStat 2 "High Beams" 1 "Low Beams" 0 "Unknown" ;
VAL_TABLE_ ACSAlarm9 2 "Expired" 1 "Active" 0 "Inactive" ;
VAL_TABLE_ ACSAlarm8 2 "Expired" 1 "Active" 0 "Inactive" ;
VAL_TABLE_ ACSAlarm7 2 "Expired" 1 "Active" 0 "Inactive" ;
VAL_TABLE_ ACSAlarm6 2 "Expired" 1 "Active" 0 "Inactive" ;
VAL_TABLE_ ACSAlarm5 2 "Expired" 1 "Active" 0 "Inactive" ;
VAL_TABLE_ ACSAlarm4 2 "Expired" 1 "Active" 0 "Inactive" ;
VAL_TABLE_ ACSAlarm3 2 "Expired" 1 "Active" 0 "Inactive" ;
VAL_TABLE_ ACSAlarm2 2 "Expired" 1 "Active" 0 "Inactive" ;
VAL_TABLE_ ACSAlarm15 2 "Expired" 1 "Active" 0 "Inactive" ;
VAL_TABLE_ ACSAlarm14 2 "Expired" 1 "Active" 0 "Inactive" ;
VAL_TABLE_ ACSAlarm13 2 "Expired" 1 "Active" 0 "Inactive" ;
VAL_TABLE_ ACSAlarm12 2 "Expired" 1 "Active" 0 "Inactive" ;
VAL_TABLE_ ACSAlarm11 2 "Expired" 1 "Active" 0 "Inactive" ;
VAL_TABLE_ ACSAlarm10 2 "Expired" 1 "Active" 0 "Inactive" ;
VAL_TABLE_ ACSAlarm1 2 "Expired" 1 "Active" 0 "Inactive" ;
VAL_TABLE_ ACSAlarm0 2 "Expired" 1 "Active" 0 "Inactive" ;
VAL_TABLE_ VehStabEnhmntMd 2 "Competitive" 1 "Normal" 0 "Off" ;
VAL_TABLE_ VehStabEnhmntStat 4 "Not Ready" 3 "Warming Up" 2 "Fault" 1 "Active" 0 "Inactive" ;
VAL_TABLE_ TCSysOpMd 2 "Off Road" 1 "Normal" 0 "Off" ;
VAL_TABLE_ TCSysOpStat 2 "Fault" 1 "Active" 0 "Inactive" ;
VAL_TABLE_ CrShrngFbsEnblReq 7 "Unused and Resrved 5" 6 "Unused and Resrved 4" 5 "Unused and Resrved 3" 4 "Unused and Resrved 2" 3 "Return State" 2 "Unused and Resrved 1" 1 "Disable Fobs" 0 "No Action" ;
VAL_TABLE_ EnrgMgtLdShdRq 4 "Load Shed Level 4" 3 "Load Shed Level 3" 2 "Load Shed Level 2" 1 "Load Shed Level 1" 0 "No Load Shedding" ;
VAL_TABLE_ DrId 7 "Unknown" 6 "Driver #7" 5 "Driver #6" 4 "Driver #5" 3 "Driver #4" 2 "Driver #3" 1 "Driver #2" 0 "Driver #1" ;
VAL_TABLE_ TireRRPrsStat 5 "High" 4 "Low - Extended Mobility" 3 "Low" 2 "Low - Service Now" 1 "Nominal" 0 "Unknown" ;
VAL_TABLE_ TireRFPrsStat 5 "High" 4 "Low - Extended Mobility" 3 "Low" 2 "Low - Service Now" 1 "Nominal" 0 "Unknown" ;
VAL_TABLE_ TireLRPrsStat 5 "High" 4 "Low - Extended Mobility" 3 "Low" 2 "Low - Service Now" 1 "Nominal" 0 "Unknown" ;
VAL_TABLE_ TireLFPrsStat 5 "High" 4 "Low - Extended Mobility" 3 "Low" 2 "Low - Service Now" 1 "Nominal" 0 "Unknown" ;
VAL_TABLE_ SC_SndTne 10 "Beep (750 Hz) Radio Source Muted" 9 "High Frequency Broadband" 8 "Harp" 7 "Gong (2000 Hz)" 6 "Gong (750 Hz)" 5 "Beep (2000 Hz)" 4 "Beep (750 Hz)" 3 "Click-Clack" 2 "Click" 1 "Clack" 0 "Clock" 14 "No Chime with Radio Source Muted" 13 "Gong (2000 Hz) Radio Source Muted" 12 "Gong (750 Hz) Radio Source Muted" 11 "Beep (2000 Hz) Radio Source Muted" ;
VAL_TABLE_ DTCI_DTCFaultType 3 "Type C" 2 "Type B" 1 "Type A" 0 "Not Supported" ;
VAL_TABLE_ DistRollCntAvgDrvnSrc 1 "Wheel Speed" 0 "Transmission Output Speed" ;
VAL_TABLE_ VehSpdAvgDrvnSrc 1 "Wheel Speed" 0 "Transmission Output Speed" ;
VAL_TABLE_ TrnsThrmlMngmntStat 2 "Driver Intervention Requested" 1 "Countermeasures Active" 0 "Normal" ;
VAL_TABLE_ TrnsSftMdStat 3 "Automatic Grade Braking Mode" 2 "Lift-Foot Cornering Mode" 1 "Performance Mode" 0 "No Override Mode" ;
VAL_TABLE_ TrnsRngInhbtStat 4 "Diagnostic Inhibit Active" 3 "Driveline Not Engaged" 2 "Transmission Range Re-Selection Req" 1 "Transmission Inhibit Active" 0 "No Range Inhibit Active" ;
VAL_TABLE_ DrvtShftCntrlTrgtGear 10 "Tenth Gear" 9 "Ninth Gear" 8 "Eighth Gear" 7 "Seventh Gear" 6 "Sixth Gear" 5 "Fifth Gear" 4 "Fourth Gear" 3 "Third Gear" 2 "Second Gear" 1 "First Gear" 0 "Not Supported" ;
VAL_TABLE_ StrWhlAngSenCalStat 2 "Calibrated" 1 "Estimated" 0 "Unknown" ;
VAL_TABLE_ ACCompCmnd 1 "On" 0 "Off" ;
VAL_TABLE_ EngEmsRelMalfIndReq 4 "Flashing 0.5 Hertz Indication" 3 "Flashing 2 Hertz Indication" 2 "Flashing 1 Hertz Indication" 1 "No Indication" 0 "Continuous Indication" ;
VAL_TABLE_ EngCylDeactMd 3 "Reactivation In Progress" 2 "Half of Total Cylinders Active" 1 "Deactivation In Progress" 0 "All Cylinders Active" ;
VAL_TABLE_ EngSpdStat 3 "Invalid" 1 "Degraded Operation" 0 "Normal Operation" ;
VAL_TABLE_ DispMeasSys 1 "English" 0 "Metric" ;
VAL_TABLE_ ACCompModReq 3 "No Action" 2 "Engage" 1 "Disengage" 0 "Disengage Immediately" ;
VAL_TABLE_ TrnsShftLvrPos 13 "Forward Range J" 12 "Froward Range I" 15 "Lever Position Unknown" 11 "Forward Range H" 10 "Forward Range G" 9 "Forward Range F" 8 "Forward Range E" 7 "Forward Range D" 6 "Forward Range C" 5 "Forward Range B" 4 "Forward Range A" 3 "Neutral Range" 2 "Reverse Range" 1 "Park Range" 0 "Between Ranges" ;
VAL_TABLE_ CrShrngVehChlngReq 1 "Request New Challenge" 0 "No Action" ;
VAL_TABLE_ HLOCCstCurrSetVal 3 "On Open Only" 2 "On" 1 "Off" 0 "No Action" ;
VAL_TABLE_ CSPS_RspVerf 4 "Command Response Verification Not Successful" 3 "Command Response Verification Successful" 2 "Zone Response Verification Not Successful" 1 "Zone Response Verification Successful" 0 "No Action" ;
VAL_TABLE_ CSPS_ConnStat 15 "Reject All Certificates" 14 "Incorrect Fleet ID" 13 "Send Intermediate Certificate" 12 "Send User Certificate" 11 "Send all Authentication Data" 10 "Invalid VIN" 9 "Intermediate Certificate Expired" 8 "Invalid Intermediate Certificate" 7 "Resrvation End Time Exceeded " 6 "Resrvtion Start Tim Not Achieved" 5 "Cert Revoked Via Mobile Device" 4 "Cert Revoked Via Telematics" 3 "Certificate Expired" 2 "Invalid Certificate" 1 "Valid Certificate" 0 "No Action" ;
VAL_TABLE_ CrShrngFbsEnblStat 3 "Fail" 2 "Enabled" 1 "Disabled" 0 "No Action" ;
VAL_TABLE_ StTODChrgTmpOvrdRmt1 0 "No Action" 1 "Inactive" 2 "Active" ;
VAL_TABLE_ AutoTransComndGear 9 "Ninth Gear" 15 "Park Gear" 14 "Reverse Gear" 13 "Neutral Gear" 12 "CVT Forward Gear" 11 "Unused and Reserved" 10 "Tenth Gear" 8 "Eighth Gear" 7 "Seventh Gear" 6 "Sixth Gear" 5 "Fifth Gear" 4 "Fourth Gear" 3 "Third Gear" 2 "Second Gear" 1 "First Gear" 0 "Not Supported" ;
VAL_TABLE_ TransEstGear 9 "Ninth Gear" 15 "Park Gear" 14 "Reverse Gear" 13 "Neutral Gear" 12 "CVT Forward Gear" 11 "Unused and Reserved" 10 "Tenth Gear" 8 "Eighth Gear" 7 "Seventh Gear" 6 "Sixth Gear" 5 "Fifth Gear" 4 "Fourth Gear" 3 "Third Gear" 2 "Second Gear" 1 "First Gear" 0 "Not Supported" ;
VAL_TABLE_ RmVehStrRq 1 "Remote Start Requested" 0 "Remote Start Not Requested" ;
VAL_TABLE_ VehSpdCntlSystmType 2 "Adaptive Cruise Control" 1 "Conventional Cruise Control" 0 "No Vehicle Speed Control" ;
VAL_TABLE_ SysBkUpPwrMd 3 "Crank Request" 2 "Run" 1 "Accessory" 0 "Off" ;
VAL_TABLE_ SysPwrMd 3 "Crank Request" 2 "Run" 1 "Accessory" 0 "Off" ;
VAL_TABLE_ CrsCntrlSwStSwDataIntgty 3 "Illegal Range" 2 "Failure Detected" 1 "Data Invalid" 0 "Data Valid" ;
VAL_TABLE_ SprTireSt 2 "Spare Detected" 1 "No Spare Detected" 0 "Undetermined" ;
VAL_TABLE_ ValidityStates 1 "Invalid" 0 "Valid" ;
VAL_TABLE_ MainLghtSw 3 "HEADLAMP" 2 "PARKLAMP" 1 "OFF" 0 "AUTO" ;
VAL_TABLE_ AudMstrSrcTyp 28 "Phone" 24 "Sat. Digital Audio Receiver System" 20 "Digital Audio Broadcast" 16 "Remote CD Changer" 12 "Remote Digital Video Disk" 8 "Auxiliary Device" 1 "Television Tuner" 0 "Audio Supervisor" ;
VAL_TABLE_ AudMstrChnnlTyp 3 "Mixed" 2 "Stereo" 1 "Mono" 0 "No Channel" ;
VAL_TABLE_ AudMstrArbCom 4 "Connection Complete" 3 "Disconnect" 2 "Connect" 1 "Do Not Connect" 0 "No Action" ;
VAL_TABLE_ RrWndDfgInhRq 1 "Inhibit rear window defog" 0 "Allow rear window defog" ;

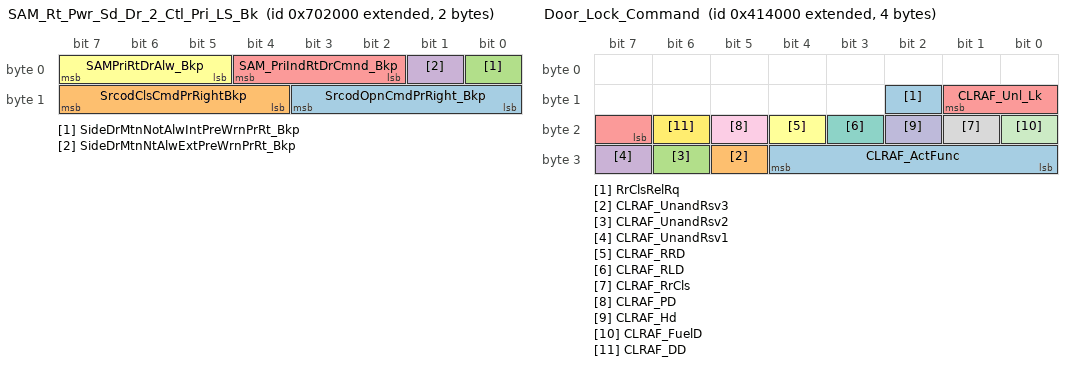
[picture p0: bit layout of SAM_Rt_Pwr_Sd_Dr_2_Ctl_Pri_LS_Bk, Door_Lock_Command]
BO_ 2154831872 SAM_Rt_Pwr_Sd_Dr_2_Ctl_Pri_LS_Bk: 2 ADIMb_LS
 SG_ SrcodOpnCmdPrRight_Bkp : 11|4@0+ (1,0) [0|15] ""  SAM_PR_LS,CGM3a_LS,BCM_LS
 SG_ SrcodClsCmdPrRightBkp : 15|4@0+ (1,0) [0|15] ""  SAM_PR_LS,CGM3a_LS,BCM_LS
 SG_ SideDrMtnNotAlwIntPreWrnPrRt_Bkp : 0|1@0+ (1,0) [0|1] ""  SAM_PR_LS,CGM3a_LS,BCM_LS
 SG_ SideDrMtnNtAlwExtPreWrnPrRt_Bkp : 1|1@0+ (1,0) [0|1] ""  SAM_PR_LS,CGM3a_LS,BCM_LS
 SG_ SAM_PriIndRtDrCmnd_Bkp : 4|3@0+ (1,0) [0|0] ""  SAM_PR_LS,CGM3a_LS,BCM_LS
 SG_ SAMPriRtDrAlw_Bkp : 7|3@0+ (1,0) [0|7] ""  SAM_PR_LS,CGM3a_LS,BCM_LS

BO_ 2151759872 Door_Lock_Command: 4 BCM_LS
 SG_ RrClsRelRq : 10|1@0+ (1,0) [0|1] ""  SAM_SR_LS,SAM_SL_LS,SAM_PR_LS,SAM_PL_LS
 SG_ CLRAF_UnandRsv3 : 29|1@0+ (1,0) [0|1] ""  SAM_SR_LS,SAM_SL_LS,SAM_PR_LS,SAM_PL_LS
 SG_ CLRAF_UnandRsv2 : 30|1@0+ (1,0) [0|1] ""  SAM_SR_LS,SAM_SL_LS,SAM_PR_LS,SAM_PL_LS
 SG_ CLRAF_UnandRsv1 : 31|1@0+ (1,0) [0|1] ""  SAM_SR_LS,SAM_SL_LS,SAM_PR_LS,SAM_PL_LS
 SG_ CLRAF_Unl_Lk : 9|3@0+ (1,0) [0|7] ""  SAM_SR_LS,SAM_SL_LS,SAM_PR_LS,SAM_PL_LS
 SG_ CLRAF_RRD : 20|1@0+ (1,0) [0|1] ""  SAM_SR_LS,SAM_SL_LS,SAM_PR_LS,SAM_PL_LS
 SG_ CLRAF_RLD : 19|1@0+ (1,0) [0|1] ""  SAM_SR_LS,SAM_SL_LS,SAM_PR_LS,SAM_PL_LS
 SG_ CLRAF_RrCls : 17|1@0+ (1,0) [0|1] ""  SAM_SR_LS,SAM_SL_LS,SAM_PR_LS,SAM_PL_LS
 SG_ CLRAF_PD : 21|1@0+ (1,0) [0|1] ""  SAM_SR_LS,SAM_SL_LS,SAM_PR_LS,SAM_PL_LS
 SG_ CLRAF_Hd : 18|1@0+ (1,0) [0|1] ""  SAM_SR_LS,SAM_SL_LS,SAM_PR_LS,SAM_PL_LS
 SG_ CLRAF_FuelD : 16|1@0+ (1,0) [0|1] ""  SAM_SR_LS,SAM_SL_LS,SAM_PR_LS,SAM_PL_LS
 SG_ CLRAF_DD : 22|1@0+ (1,0) [0|1] ""  SAM_SR_LS,SAM_SL_LS,SAM_PR_LS,SAM_PL_LS
 SG_ CLRAF_ActFunc : 28|5@0+ (1,0) [0|31] ""  SAM_SR_LS,SAM_SL_LS,SAM_PR_LS,SAM_PL_LS

BO_ 1373 UUDT_Resp_From_SAM_PR_LS: 8 SAM_PR_LS
 SG_ DgnInf_LS55D : 7|64@0+ (1,0) [0|1.84467440737096E+019] ""  CGM3a_LS

BO_ 1365 UUDT_Resp_From_SAM_PL_LS: 8 SAM_PL_LS
 SG_ DgnInf_LS555 : 7|64@0+ (1,0) [0|1.84467440737096E+019] ""  CGM3a_LS

BO_ 1364 UUDT_Resp_From_SAM_SR_LS: 8 SAM_SR_LS
 SG_ DgnInf_LS554 : 7|64@0+ (1,0) [0|1.84467440737096E+019] ""  CGM3a_LS

BO_ 1360 UUDT_Resp_From_SAM_SL_LS: 8 SAM_SL_LS
 SG_ DgnInf_LS550 : 7|64@0+ (1,0) [0|1.84467440737096E+019] ""  CGM3a_LS

BO_ 1616 USDT_Resp_From_SAM_SL_LS: 8 SAM_SL_LS
 SG_ DgnInf : 7|64@0+ (1,0) [0|1.84467440737096E+019] ""  CGM3a_LS

BO_ 1620 USDT_Resp_From_SAM_SR_LS: 8 SAM_SR_LS
 SG_ DgnInf : 7|64@0+ (1,0) [0|1.84467440737096E+019] ""  CGM3a_LS

BO_ 1629 USDT_Resp_From_SAM_PR_LS: 8 SAM_PR_LS
 SG_ DgnInf : 7|64@0+ (1,0) [0|1.84467440737096E+019] ""  CGM3a_LS

BO_ 1621 USDT_Resp_From_SAM_PL_LS: 8 SAM_PL_LS
 SG_ DgnInf : 7|64@0+ (1,0) [0|1.84467440737096E+019] ""  CGM3a_LS

BO_ 596 USDT_Req_to_SAM_SR_LS: 8 CGM3a_LS
 SG_ DgnInf : 7|64@0+ (1,0) [0|1.84467440737096E+019] ""  CGM3a_LS,SAM_SR_LS

BO_ 592 USDT_Req_to_SAM_SL_LS: 8 CGM3a_LS
 SG_ DgnInf : 7|64@0+ (1,0) [0|1.84467440737096E+019] ""  CGM3a_LS,SAM_SL_LS

BO_ 605 USDT_Req_to_SAM_PR_LS: 8 CGM3a_LS
 SG_ DgnInf : 7|64@0+ (1,0) [0|1.84467440737096E+019] ""  CGM3a_LS,SAM_PR_LS

BO_ 597 USDT_Req_to_SAM_PL_LS: 8 CGM3a_LS
 SG_ DgnInf : 7|64@0+ (1,0) [0|1.84467440737096E+019] ""  CGM3a_LS,SAM_PL_LS

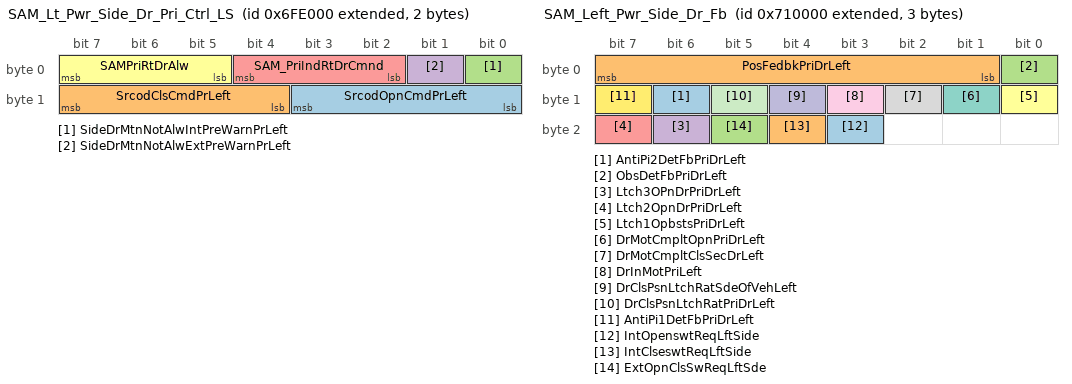
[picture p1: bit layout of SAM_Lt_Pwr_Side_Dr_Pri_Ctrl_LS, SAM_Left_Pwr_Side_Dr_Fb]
BO_ 2154815488 SAM_Lt_Pwr_Side_Dr_Pri_Ctrl_LS: 2 ADIMa_LS
 SG_ SrcodOpnCmdPrLeft : 11|4@0+ (1,0) [0|15] ""  BCM_LS,SAM_PL_LS,CGM3a_LS
 SG_ SrcodClsCmdPrLeft : 15|4@0+ (1,0) [0|15] ""  BCM_LS,SAM_PL_LS,CGM3a_LS
 SG_ SideDrMtnNotAlwIntPreWarnPrLeft : 0|1@0+ (1,0) [0|1] ""  BCM_LS,SAM_PL_LS,CGM3a_LS
 SG_ SideDrMtnNotAlwExtPreWarnPrLeft : 1|1@0+ (1,0) [0|1] ""  BCM_LS,SAM_PL_LS,CGM3a_LS
 SG_ SAM_PriIndRtDrCmnd : 4|3@0+ (1,0) [0|0] ""  BCM_LS,SAM_PL_LS,CGM3a_LS
 SG_ SAMPriRtDrAlw : 7|3@0+ (1,0) [0|7] ""  BCM_LS,CGM3a_LS,SAM_PL_LS

BO_ 2154889216 SAM_Left_Pwr_Side_Dr_Fb: 3 SAM_PL_LS
 SG_ AntiPi2DetFbPriDrLeft : 14|1@0+ (1,0) [0|1] ""  CGM3a_LS,ADIMa_LS,ADIMb_LS,BCM_LS
 SG_ PosFedbkPriDrLeft : 7|7@0+ (0.78741,0) [0|100.00107] ""  CGM3a_LS,ADIMa_LS,ADIMb_LS,BCM_LS
 SG_ ObsDetFbPriDrLeft : 0|1@0+ (1,0) [0|1] ""  CGM3a_LS,ADIMa_LS,ADIMb_LS,BCM_LS
 SG_ Ltch3OPnDrPriDrLeft : 22|1@0+ (1,0) [0|1] ""  CGM3a_LS,ADIMa_LS,ADIMb_LS,BCM_LS
 SG_ Ltch2OpnDrPriDrLeft : 23|1@0+ (1,0) [0|1] ""  CGM3a_LS,ADIMa_LS,ADIMb_LS,BCM_LS
 SG_ Ltch1OpbstsPriDrLeft : 8|1@0+ (1,0) [0|1] ""  CGM3a_LS,ADIMa_LS,ADIMb_LS,BCM_LS
 SG_ DrMotCmpltOpnPriDrLeft : 9|1@0+ (1,0) [0|1] ""  CGM3a_LS,ADIMa_LS,ADIMb_LS,BCM_LS
 SG_ DrMotCmpltClsSecDrLeft : 10|1@0+ (1,0) [0|1] ""  CGM3a_LS,ADIMa_LS,ADIMb_LS,BCM_LS
 SG_ DrInMotPriLeft : 11|1@0+ (1,0) [0|1] ""  CGM3a_LS,ADIMa_LS,ADIMb_LS,BCM_LS
 SG_ DrClsPsnLtchRatSdeOfVehLeft : 12|1@0+ (1,0) [0|1] ""  CGM3a_LS,ADIMa_LS,ADIMb_LS,BCM_LS
 SG_ DrClsPsnLtchRatPriDrLeft : 13|1@0+ (1,0) [0|1] ""  CGM3a_LS,ADIMa_LS,ADIMb_LS,BCM_LS
 SG_ AntiPi1DetFbPriDrLeft : 15|1@0+ (1,0) [0|1] ""  CGM3a_LS,ADIMa_LS,ADIMb_LS,BCM_LS
 SG_ IntOpenswtReqLftSide : 19|1@0+ (1,0) [0|1] ""  ADIMa_LS,ADIMb_LS,CGM3a_LS,BCM_LS
 SG_ IntClseswtReqLftSide : 20|1@0+ (1,0) [0|1] ""  ADIMa_LS,ADIMb_LS,CGM3a_LS,BCM_LS
 SG_ ExtOpnClsSwReqLftSde : 21|1@0+ (1,0) [0|1] ""  ADIMa_LS,ADIMb_LS,CGM3a_LS,BCM_LS

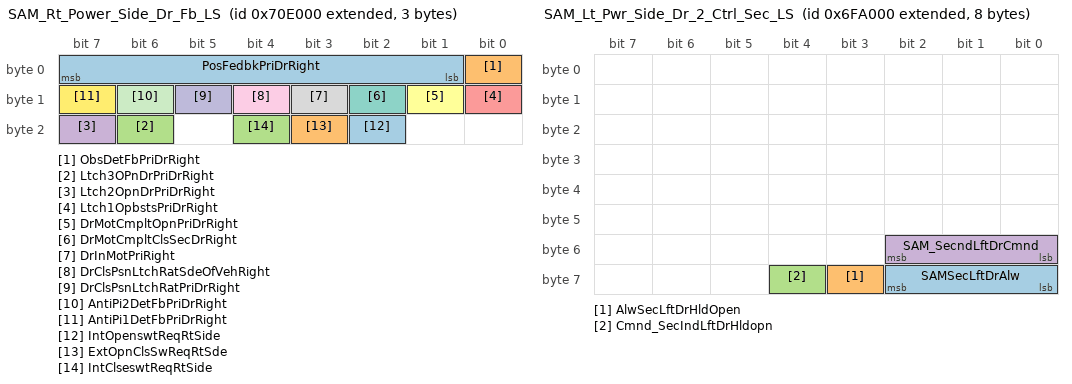
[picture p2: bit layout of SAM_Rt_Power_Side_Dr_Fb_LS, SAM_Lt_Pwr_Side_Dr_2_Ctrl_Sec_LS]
BO_ 2154881024 SAM_Rt_Power_Side_Dr_Fb_LS: 3 SAM_PR_LS
 SG_ PosFedbkPriDrRight : 7|7@0+ (0.78741,0) [0|100.00107] ""  CGM3a_LS,ADIMa_LS,ADIMb_LS,BCM_LS
 SG_ ObsDetFbPriDrRight : 0|1@0+ (1,0) [0|1] ""  CGM3a_LS,ADIMa_LS,ADIMb_LS,BCM_LS
 SG_ Ltch3OPnDrPriDrRight : 22|1@0+ (1,0) [0|1] ""  CGM3a_LS,ADIMa_LS,ADIMb_LS,BCM_LS
 SG_ Ltch2OpnDrPriDrRight : 23|1@0+ (1,0) [0|1] ""  CGM3a_LS,ADIMa_LS,ADIMb_LS,BCM_LS
 SG_ Ltch1OpbstsPriDrRight : 8|1@0+ (1,0) [0|1] ""  CGM3a_LS,ADIMa_LS,ADIMb_LS,BCM_LS
 SG_ DrMotCmpltOpnPriDrRight : 9|1@0+ (1,0) [0|1] ""  CGM3a_LS,ADIMa_LS,ADIMb_LS,BCM_LS
 SG_ DrMotCmpltClsSecDrRight : 10|1@0+ (1,0) [0|1] ""  CGM3a_LS,ADIMa_LS,ADIMb_LS,BCM_LS
 SG_ DrInMotPriRight : 11|1@0+ (1,0) [0|1] ""  CGM3a_LS,ADIMa_LS,ADIMb_LS,BCM_LS
 SG_ DrClsPsnLtchRatSdeOfVehRight : 12|1@0+ (1,0) [0|1] ""  CGM3a_LS,ADIMa_LS,ADIMb_LS,BCM_LS
 SG_ DrClsPsnLtchRatPriDrRight : 13|1@0+ (1,0) [0|1] ""  CGM3a_LS,ADIMa_LS,ADIMb_LS,BCM_LS
 SG_ AntiPi2DetFbPriDrRight : 14|1@0+ (1,0) [0|1] ""  CGM3a_LS,ADIMa_LS,ADIMb_LS,BCM_LS
 SG_ AntiPi1DetFbPriDrRight : 15|1@0+ (1,0) [0|1] ""  CGM3a_LS,ADIMa_LS,ADIMb_LS,BCM_LS
 SG_ IntOpenswtReqRtSide : 18|1@0+ (1,0) [0|1] ""  ADIMa_LS,ADIMb_LS,CGM3a_LS,BCM_LS
 SG_ ExtOpnClsSwReqRtSde : 19|1@0+ (1,0) [0|1] ""  ADIMa_LS,ADIMb_LS,CGM3a_LS,BCM_LS
 SG_ IntClseswtReqRtSide : 20|1@0+ (1,0) [0|1] ""  ADIMa_LS,ADIMb_LS,CGM3a_LS,BCM_LS

BO_ 2154799104 SAM_Lt_Pwr_Side_Dr_2_Ctrl_Sec_LS: 8 SAM_PL_LS
 SG_ SAMSecLftDrAlw : 58|3@0+ (1,0) [0|7] ""  SAM_SL_LS,CGM3a_LS
 SG_ AlwSecLftDrHldOpen : 59|1@0+ (1,0) [0|1] ""  CGM3a_LS,SAM_SL_LS
 SG_ Cmnd_SecIndLftDrHldopn : 60|1@0+ (1,0) [0|1] ""  SAM_SL_LS,CGM3a_LS
 SG_ SAM_SecndLftDrCmnd : 50|3@0+ (1,0) [0|0] ""  SAM_SL_LS,CGM3a_LS

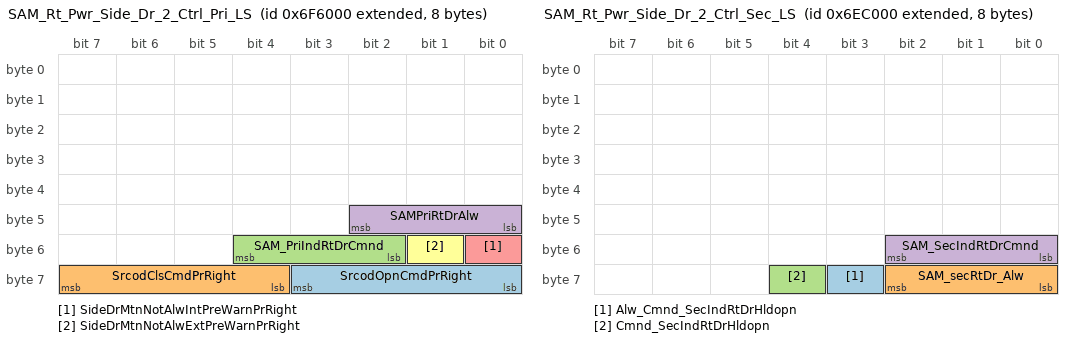
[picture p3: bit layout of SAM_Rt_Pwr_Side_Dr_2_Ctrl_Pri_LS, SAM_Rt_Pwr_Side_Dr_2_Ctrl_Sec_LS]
BO_ 2154782720 SAM_Rt_Pwr_Side_Dr_2_Ctrl_Pri_LS: 8 ADIMa_LS
 SG_ SrcodOpnCmdPrRight : 59|4@0+ (1,0) [0|15] ""  BCM_LS,CGM3a_LS,SAM_PR_LS
 SG_ SrcodClsCmdPrRight : 63|4@0+ (1,0) [0|15] ""  BCM_LS,CGM3a_LS,SAM_PR_LS
 SG_ SAM_PriIndRtDrCmnd : 52|3@0+ (1,0) [0|0] ""  BCM_LS,CGM3a_LS,SAM_PR_LS
 SG_ SAMPriRtDrAlw : 42|3@0+ (1,0) [0|7] ""  BCM_LS,CGM3a_LS,SAM_PR_LS
 SG_ SideDrMtnNotAlwIntPreWarnPrRight : 48|1@0+ (1,0) [0|1] ""  BCM_LS,CGM3a_LS,SAM_PR_LS
 SG_ SideDrMtnNotAlwExtPreWarnPrRight : 49|1@0+ (1,0) [0|1] ""  BCM_LS,CGM3a_LS,SAM_PR_LS

BO_ 2154774528 SAM_Left_Power_Side_Dr_2_Fb_LS: 4 SAM_SL_LS
 SG_ AntiPn2FltdetLft : 19|1@0+ (1,0) [0|1] ""  CGM3a_LS,BCM_LS,ADIMa_LS,ADIMb_LS
 SG_ PosSenFltLft : 27|1@0+ (1,0) [0|1] ""  CGM3a_LS,BCM_LS,ADIMa_LS,ADIMb_LS,SAM_PL_LS
 SG_ ActMtrFltDetLft : 28|1@0+ (1,0) [0|1] ""  CGM3a_LS,BCM_LS,ADIMa_LS,ADIMb_LS,SAM_PL_LS
 SG_ LtchMtr3FltdetLft : 29|1@0+ (1,0) [0|1] ""  CGM3a_LS,BCM_LS,ADIMa_LS,ADIMb_LS,SAM_PL_LS
 SG_ LtchMtr2FltdetLft : 30|1@0+ (1,0) [0|1] ""  CGM3a_LS,BCM_LS,ADIMa_LS,ADIMb_LS,SAM_PL_LS
 SG_ LtchMtr1FltdetLft : 31|1@0+ (1,0) [0|1] ""  BCM_LS,CGM3a_LS,SAM_PL_LS
 SG_ AntiPn1FltDetLft : 20|1@0+ (1,0) [0|1] ""  CGM3a_LS,BCM_LS,ADIMa_LS,ADIMb_LS,SAM_PL_LS
 SG_ ContrlUnavbLft : 26|1@0+ (1,0) [0|1] ""  CGM3a_LS,BCM_LS,ADIMa_LS,ADIMb_LS,SAM_PL_LS
 SG_ IntclseswtchactLft : 18|1@0+ (1,0) [0|1] ""  CGM3a_LS,BCM_LS,ADIMa_LS,ADIMb_LS,SAM_PL_LS
 SG_ IntopenswtchactLft : 17|1@0+ (1,0) [0|1] ""  ADIMa_LS,ADIMb_LS,BCM_LS,CGM3a_LS,SAM_PL_LS
 SG_ ExtswtchactLft : 16|1@0+ (1,0) [0|1] ""  CGM3a_LS,BCM_LS,ADIMa_LS,ADIMb_LS,SAM_PL_LS
 SG_ DrMotCmpltOpnSecDrLft : 12|1@0+ (1,0) [0|1] ""  CGM3a_LS,BCM_LS,ADIMa_LS,ADIMb_LS,SAM_PL_LS
 SG_ DrMotCmpltClsSecDrLft : 11|1@0+ (1,0) [0|1] ""  CGM3a_LS,BCM_LS,ADIMa_LS,ADIMb_LS,SAM_PL_LS
 SG_ DrInMotSecLft : 8|1@0+ (1,0) [0|1] ""  CGM3a_LS,BCM_LS,ADIMa_LS,ADIMb_LS,SAM_PL_LS
 SG_ Ltch2OpnDrSecDrLft : 22|1@0+ (1,0) [0|1] ""  CGM3a_LS,BCM_LS,ADIMa_LS,ADIMb_LS,SAM_PL_LS
 SG_ PosFedbkSecDrLft : 7|7@0+ (0.78741,0) [0|100.00107] ""  CGM3a_LS,BCM_LS,ADIMa_LS,ADIMb_LS,SAM_PL_LS
 SG_ AntiPi2DetFbSecDrLft : 14|1@0+ (1,0) [0|1] ""  CGM3a_LS,BCM_LS,ADIMa_LS,ADIMb_LS,SAM_PL_LS
 SG_ ObsDetFbSecDrLft : 0|1@0+ (1,0) [0|1] ""  CGM3a_LS,BCM_LS,ADIMa_LS,ADIMb_LS,SAM_PL_LS
 SG_ Ltch3OpnDrSecDrLft : 21|1@0+ (1,0) [0|1] ""  CGM3a_LS,BCM_LS,ADIMa_LS,ADIMb_LS,SAM_PL_LS
 SG_ Ltch1OpbstsSecDrLft : 23|1@0+ (1,0) [0|1] ""  CGM3a_LS,BCM_LS,ADIMa_LS,ADIMb_LS,SAM_PL_LS
 SG_ HldOpnRlsActFbSecDrLft : 9|1@0+ (1,0) [0|1] ""  CGM3a_LS,BCM_LS,ADIMa_LS,ADIMb_LS,SAM_PL_LS
 SG_ DrClsPsnLtchRatSecDrLft : 13|1@0+ (1,0) [0|1] ""  CGM3a_LS,BCM_LS,ADIMa_LS,ADIMb_LS,SAM_PL_LS
 SG_ CinActFbSecDrLft : 10|1@0+ (1,0) [0|1] ""  CGM3a_LS,BCM_LS,ADIMa_LS,ADIMb_LS,SAM_PL_LS
 SG_ AntiPi1DetFbSecDrLft : 15|1@0+ (1,0) [0|1] ""  CGM3a_LS,BCM_LS,ADIMa_LS,ADIMb_LS,SAM_PL_LS

BO_ 2154749952 SAM_Rt_Power_Side_Dr_2_Fb_LS: 4 SAM_SR_LS
 SG_ PosSenFltRt : 27|1@0+ (1,0) [0|1] ""  CGM3a_LS,SAM_PR_LS,BCM_LS,ADIMa_LS,ADIMb_LS
 SG_ LtchMtr3FltdetRt : 29|1@0+ (1,0) [0|1] ""  CGM3a_LS,SAM_PR_LS,BCM_LS,ADIMa_LS,ADIMb_LS
 SG_ LtchMtr2FltdetRt : 30|1@0+ (1,0) [0|1] ""  CGM3a_LS,SAM_PR_LS,BCM_LS,ADIMa_LS,ADIMb_LS
 SG_ LtchMtr1FltdetRt : 31|1@0+ (1,0) [0|1] ""  CGM3a_LS,SAM_PR_LS,BCM_LS,ADIMa_LS,ADIMb_LS
 SG_ IntopenswtchactRt : 17|1@0+ (1,0) [0|1] ""  CGM3a_LS,SAM_PR_LS,BCM_LS,ADIMa_LS,ADIMb_LS
 SG_ ExtswtchactRt : 16|1@0+ (1,0) [0|1] ""  CGM3a_LS,SAM_PR_LS,BCM_LS,ADIMa_LS,ADIMb_LS
 SG_ ContrlUnavbLft_Rt : 26|1@0+ (1,0) [0|1] ""  CGM3a_LS,SAM_PR_LS,BCM_LS,ADIMa_LS,ADIMb_LS
 SG_ AntiPn1FltDetRt : 20|1@0+ (1,0) [0|1] ""  CGM3a_LS,SAM_PR_LS,BCM_LS,ADIMa_LS,ADIMb_LS
 SG_ ActMtrFltDetRt : 28|1@0+ (1,0) [0|1] ""  CGM3a_LS,SAM_PR_LS,BCM_LS,ADIMa_LS,ADIMb_LS
 SG_ PosFedbkSecDrRT : 7|7@0+ (0.78741,0) [0|100.00107] ""  CGM3a_LS,SAM_PR_LS,BCM_LS,ADIMa_LS,ADIMb_LS
 SG_ ObsDetFbSecDrRt : 0|1@0+ (1,0) [0|1] ""  CGM3a_LS,SAM_PR_LS,BCM_LS,ADIMa_LS,ADIMb_LS
 SG_ Ltch3OpnDrSecDrRt : 21|1@0+ (1,0) [0|1] ""  CGM3a_LS,SAM_PR_LS,BCM_LS,ADIMa_LS,ADIMb_LS
 SG_ Ltch2OpnDrSecDrRt : 22|1@0+ (1,0) [0|1] ""  CGM3a_LS,SAM_PR_LS,BCM_LS,ADIMa_LS,ADIMb_LS
 SG_ Ltch1OpbstsSecDrRt : 23|1@0+ (1,0) [0|1] ""  CGM3a_LS,SAM_PR_LS,BCM_LS,ADIMa_LS,ADIMb_LS
 SG_ HldOpnRlsActFbSecDrRt : 8|1@0+ (1,0) [0|1] ""  CGM3a_LS,SAM_PR_LS,BCM_LS,ADIMa_LS,ADIMb_LS
 SG_ DrMotCmpltOpnSecDrRt : 11|1@0+ (1,0) [0|1] ""  CGM3a_LS,SAM_PR_LS,BCM_LS,ADIMa_LS,ADIMb_LS
 SG_ DrMotCmpltClsSecDrRt : 13|1@0+ (1,0) [0|1] ""  CGM3a_LS,SAM_PR_LS,BCM_LS,ADIMa_LS,ADIMb_LS
 SG_ DrInMotSecRt : 10|1@0+ (1,0) [0|1] ""  CGM3a_LS,SAM_PR_LS,BCM_LS,ADIMa_LS,ADIMb_LS
 SG_ DrClsPsnLtchRatSecDrRt : 12|1@0+ (1,0) [0|1] ""  CGM3a_LS,SAM_PR_LS,BCM_LS,ADIMa_LS,ADIMb_LS
 SG_ CinActFbSecDrRt : 9|1@0+ (1,0) [0|1] ""  CGM3a_LS,SAM_PR_LS,BCM_LS,ADIMa_LS,ADIMb_LS
 SG_ AntiPi2DetFbSecDrRt : 14|1@0+ (1,0) [0|1] ""  CGM3a_LS,SAM_PR_LS,BCM_LS,ADIMa_LS,ADIMb_LS
 SG_ AntiPi1DetFbSecDrRt : 15|1@0+ (1,0) [0|1] ""  CGM3a_LS,SAM_PR_LS,BCM_LS,ADIMa_LS,ADIMb_LS
 SG_ IntclseswtchactRt : 18|1@0+ (1,0) [0|1] ""  ADIMa_LS,ADIMb_LS,BCM_LS,CGM3a_LS,SAM_PR_LS
 SG_ AntiPn2FltdetRt : 19|1@0+ (1,0) [0|1] ""  CGM3a_LS,BCM_LS,ADIMa_LS,ADIMb_LS,SAM_PR_LS

BO_ 2153996288 Vehicle_Stability_SAM_LS: 8 BCM_LS
 SG_ VehIncPitch : 53|6@0- (1,0) [-32|31] "Deg"  CGM3a_LS,SAM_SR_LS,SAM_SL_LS,SAM_PR_LS,SAM_PL_LS
 SG_ VehRoll : 61|6@0- (1,0) [-32|31] "Deg"  CGM3a_LS,SAM_SR_LS,SAM_SL_LS,SAM_PR_LS,SAM_PL_LS

BO_ 2154741760 SAM_Rt_Pwr_Side_Dr_2_Ctrl_Sec_LS: 8 SAM_PR_LS
 SG_ Alw_Cmnd_SecIndRtDrHldopn : 59|1@0+ (1,0) [0|1] ""  CGM3a_LS,SAM_SR_LS
 SG_ SAM_secRtDr_Alw : 58|3@0+ (1,0) [0|7] ""  CGM3a_LS,SAM_SR_LS
 SG_ Cmnd_SecIndRtDrHldopn : 60|1@0+ (1,0) [0|1] ""  CGM3a_LS,SAM_SR_LS
 SG_ SAM_SecIndRtDrCmnd : 50|3@0+ (1,0) [0|0] ""  CGM3a_LS,SAM_SR_LS

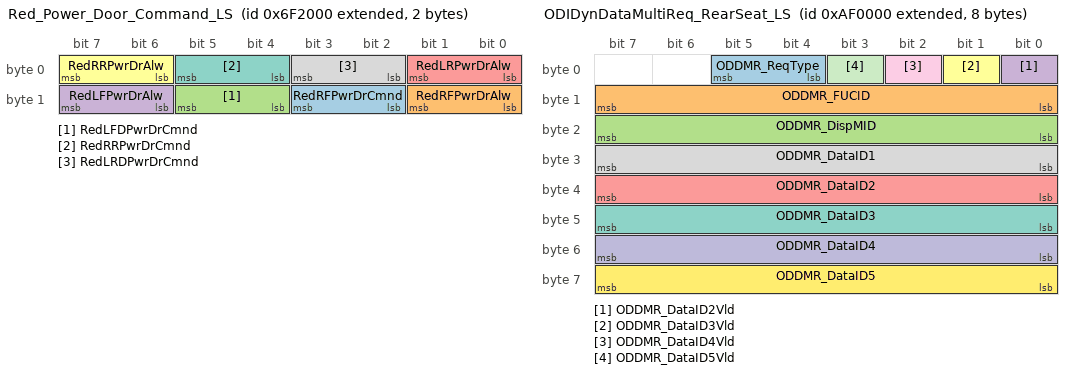
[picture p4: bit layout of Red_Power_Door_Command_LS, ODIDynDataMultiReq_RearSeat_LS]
BO_ 2154766336 Red_Power_Door_Command_LS: 2 ADIMb_LS
 SG_ RedRFPwrDrCmnd : 11|2@0+ (1,0) [0|0] ""  CGM3a_LS,BCM_LS
 SG_ RedRFPwrDrAlw : 9|2@0+ (1,0) [0|3] ""  CGM3a_LS,BCM_LS
 SG_ RedLFDPwrDrCmnd : 13|2@0+ (1,0) [0|0] ""  CGM3a_LS,BCM_LS
 SG_ RedLFPwrDrAlw : 15|2@0+ (1,0) [0|3] ""  CGM3a_LS,BCM_LS
 SG_ RedLRPwrDrAlw : 1|2@0+ (1,0) [0|3] ""  CGM3a_LS,BCM_LS
 SG_ RedRRPwrDrAlw : 7|2@0+ (1,0) [0|3] ""  CGM3a_LS,BCM_LS
 SG_ RedRRPwrDrCmnd : 5|2@0+ (1,0) [0|0] ""  CGM3a_LS,BCM_LS
 SG_ RedLRDPwrDrCmnd : 3|2@0+ (1,0) [0|0] ""  CGM3a_LS,BCM_LS

BO_ 584 USDT_Req_to_AOS2_LS: 8 CGM3a_LS
 SG_ DgnInf : 7|64@0+ (1,0) [0|1.84467440737096E+019] ""  CGM3a_LS,AOS2_LS

BO_ 1608 USDT_Resp_From_AOS2_LS: 8 AOS2_LS
 SG_ DgnInf : 7|64@0+ (1,0) [0|1.84467440737096E+019] ""  CGM3a_LS

BO_ 1576 VNMF_LS_628_AOS2: 8 AOS2_LS
 SG_ VectraSpcNWMgtD : 7|64@0+ (1,0) [0|1.84467440737096E+019] ""  SAM_PL_LS,SAM_SL_LS,SAM_SR_LS,SAM_PR_LS,VICM_LS,UPA_LS,TIM_LS,SDM_PR_LS,SCCM_2_LS,SCCM_1_LS,PEPS_LS,MCTM_LS,EOCM2cp_K2_LS,ECC_LS,DLM_LS,BCM_LS,ADIMa_LS,ADIMb_LS,CGM3a_LS,AOS_LS

BO_ 1352 UUDT_Resp_From_AOS2_LS: 8 AOS2_LS
 SG_ DgnInf_LS548 : 7|64@0+ (1,0) [0|1.84467440737096E+019] ""  CGM3a_LS

BO_ 2163015680 Traceability_Message_2: 8 ADIMa_LS
 SG_ TrcNumByt9_16 : 7|64@0+ (1,0) [0|1] ""  MCTM_LS

BO_ 2154872832 MCTMStateofHealth_LS: 8 MCTM_LS
 SG_ MCTWiFiSt : 11|2@0+ (1,0) [0|3] ""  CGM3a_LS,ADIMb_LS
 SG_ MCTStofHlthChcksm : 50|11@0+ (1,0) [0|2047] ""  CGM3a_LS,ADIMb_LS
 SG_ MCTStofHlthARC : 52|2@0+ (1,0) [0|3] ""  CGM3a_LS,ADIMb_LS
 SG_ MCTPrEthSt : 13|2@0+ (1,0) [0|3] ""  CGM3a_LS,ADIMb_LS
 SG_ MCTOfbSvcSt : 55|3@0+ (1,0) [0|7] ""  CGM3a_LS,ADIMb_LS
 SG_ MCTNmbrTbltsComm : 39|3@0+ (1,0) [0|7] ""  CGM3a_LS,ADIMb_LS
 SG_ MCTNmbrPwrSplsOprtg : 20|2@0+ (1,0) [0|3] ""  ADIMb_LS,CGM3a_LS
 SG_ MCTNmbrOnsBtnSetsOprtg : 31|2@0+ (1,0) [0|3] ""  ADIMb_LS,CGM3a_LS
 SG_ MCTNmbrNADsOprtg : 5|2@0+ (1,0) [0|3] ""  ADIMb_LS,CGM3a_LS
 SG_ MCTNmbrMicsOprtg : 23|3@0+ (1,0) [0|7] ""  ADIMb_LS,CGM3a_LS
 SG_ MCTNmbrEthPrtsOprtg : 15|2@0+ (1,0) [0|3] ""  ADIMb_LS,CGM3a_LS
 SG_ MCTNmbrCamsOprtg : 44|3@0+ (1,0) [0|7] ""  ADIMb_LS,CGM3a_LS
 SG_ MCTNmbrAntOprtg : 17|2@0+ (1,0) [0|3] ""  ADIMb_LS,CGM3a_LS
 SG_ MCTNmbrVPNsOprtg : 3|2@0+ (1,0) [0|3] ""  CGM3a_LS,ADIMb_LS
 SG_ MCTLSLANSt : 27|2@0+ (1,0) [0|3] ""  ADIMb_LS,CGM3a_LS
 SG_ MCTIPCSt : 33|2@0+ (1,0) [0|3] ""  ADIMb_LS,CGM3a_LS
 SG_ MCTHSLANSt : 29|2@0+ (1,0) [0|3] ""  ADIMb_LS,CGM3a_LS
 SG_ MCTHwSt : 7|2@0+ (1,0) [0|3] ""  ADIMb_LS,CGM3a_LS
 SG_ MCTGPSSt : 1|2@0+ (1,0) [0|3] ""  ADIMb_LS,CGM3a_LS
 SG_ MCTCGMSt : 41|2@0+ (1,0) [0|3] ""  ADIMb_LS,CGM3a_LS
 SG_ MCTBCMSt : 25|2@0+ (1,0) [0|3] ""  ADIMb_LS,CGM3a_LS
 SG_ MCTAudSt : 9|2@0+ (1,0) [0|3] ""  ADIMb_LS,CGM3a_LS
 SG_ MCTADSCCommSt : 36|3@0+ (1,0) [0|7] ""  ADIMb_LS,CGM3a_LS
 SG_ MCTADIMCommSt : 47|3@0+ (1,0) [0|7] ""  ADIMb_LS,CGM3a_LS

BO_ 1630 USDT_Resp_From_SCCM2_LS: 8 SCCM_2_LS
 SG_ DgnInf : 7|64@0+ (1,0) [0|1.84467440737096E+019] ""  CGM3a_LS

BO_ 1374 UUDT_Resp_From_SCCM2_LS: 8 SCCM_2_LS
 SG_ DgnInf_LS55E : 7|64@0+ (1,0) [0|1.84467440737096E+019] ""  CGM3a_LS

BO_ 606 USDT_Req_to_SCCM2_LS: 8 CGM3a_LS
 SG_ DgnInf : 7|64@0+ (1,0) [0|1.84467440737096E+019] ""  CGM3a_LS,SCCM_2_LS

BO_ 1603 USDT_Resp_From_SCCM1_LS: 8 SCCM_1_LS
 SG_ DgnInf : 7|64@0+ (1,0) [0|1.84467440737096E+019] ""  CGM3a_LS

BO_ 2158952448 ODIDynDataMultiReq_RearSeat_LS: 8 MCTM_LS
 SG_ ODDMR_ReqType : 5|2@0+ (1,0) [0|3] ""  ECC_LS,CGM3a_LS
 SG_ ODDMR_FUCID : 15|8@0+ (1,0) [0|255] ""  ECC_LS,CGM3a_LS
 SG_ ODDMR_DispMID : 23|8@0+ (1,0) [0|255] ""  ECC_LS,CGM3a_LS
 SG_ ODDMR_DataID2Vld : 0|1@0+ (1,0) [0|1] ""  ECC_LS,CGM3a_LS
 SG_ ODDMR_DataID2 : 39|8@0+ (1,0) [0|255] ""  ECC_LS,CGM3a_LS
 SG_ ODDMR_DataID3Vld : 1|1@0+ (1,0) [0|1] ""  ECC_LS,CGM3a_LS
 SG_ ODDMR_DataID3 : 47|8@0+ (1,0) [0|255] ""  ECC_LS,CGM3a_LS
 SG_ ODDMR_DataID1 : 31|8@0+ (1,0) [0|255] ""  ECC_LS,CGM3a_LS
 SG_ ODDMR_DataID4Vld : 2|1@0+ (1,0) [0|1] ""  ECC_LS,CGM3a_LS
 SG_ ODDMR_DataID4 : 55|8@0+ (1,0) [0|255] ""  ECC_LS,CGM3a_LS
 SG_ ODDMR_DataID5Vld : 3|1@0+ (1,0) [0|1] ""  ECC_LS,CGM3a_LS
 SG_ ODDMR_DataID5 : 63|8@0+ (1,0) [0|255] ""  ECC_LS,CGM3a_LS

CM_ "Primary Low Speed GMLAN
LS  bus is affected in Version 17.17.125_160407 [Nethra Kalmutt, 7 Apr 2016].";
CM_ BU_ MCTM_LS "Multiple Carrier Telematics Module";
CM_ BU_ TIM_LS "Trailer Interface Module";
CM_ BU_ EOCM2cp_K2_LS "External Object Control Module Safety co-pilot - K2 micro";
CM_ BU_ EOCM2cp_K1_LS "External Object Control Module Safety co-pilot - K1 micro";
CM_ BU_ ADIMa_LS "Autonomous Drive Interface Module";
CM_ BU_ BCM_LS "Body Control Module and LS Side Global Architecture Gateway";
CM_ BU_ SAM_SR_LS "Side Access Module - Secondary  Right";
CM_ BU_ SAM_SL_LS "Side Access Module -  Secondary Left";
CM_ BU_ SAM_PR_LS "Side Access Module - Primary Right";
CM_ BU_ SAM_PL_LS "Side Access Module -  Primary Left";
CM_ BU_ CGM3a_LS "Communication Gateway - Primary";
CM_ BU_ Dummy_LS "This is to avoid single ended signalling";
CM_ BU_ VICM_LS "Vehicle Integration Control Module 4Mode";
CM_ BU_ ECC_LS "Electronic Climate Control";
CM_ BU_ PEPS_LS "Passive Entry Passive Start";
CM_ BU_ AOS_LS "Automatic Occupant Sensing";
CM_ BU_ SDM_PR_LS "Sensing Diagnostic Module";
CM_ BU_ AOS2_LS "Automatic Occupant Sensing";
CM_ BU_ DLM_LS "Data Logger Module";
CM_ BU_ SCCM_2_LS "Sensor Cleaning Control Module #2";
CM_ BU_ SCCM_1_LS "Sensor Cleaning Control Module #1";
CM_ BU_ UPA_LS "Universal Parking Assist";
CM_ BU_ ADIMb_LS "Autonomous Drive Interface Module";
CM_ SG_ 2163015680 TrcNumByt9_16 "Traceability DID $B4, Bytes 9-16 - sent on VN initialization.  No event trigger will be defined.  Message is only send at initialization";
CM_ SG_ 2158952448 ODDMR_ReqType "ODI - Type of Request";
CM_ SG_ 2158952448 ODDMR_FUCID "ODI - Primary ID of Functional Unit in FU Database";
CM_ SG_ 2158952448 ODDMR_DispMID "ODI - ID that identifies the display requesting the data.  See detailed requirements in ODI GMLAN Protocol.";
CM_ SG_ 2158952448 ODDMR_DataID2Vld "ODI -DataIDTwo is being requested as a valid ID.";
CM_ SG_ 2158952448 ODDMR_DataID2 "ODI - ID for the second requested data parameter as defined in the FUDatabase";
CM_ SG_ 2158952448 ODDMR_DataID3Vld "ODI -DataIDThree is being requested as a valid ID.";
CM_ SG_ 2158952448 ODDMR_DataID3 "ODI - ID for the third requested data parameter as defined in the FUDatabase";
CM_ SG_ 2158952448 ODDMR_DataID1 "ODI - ID for the first requested data parameter as defined in the FUDatabase";
CM_ SG_ 2158952448 ODDMR_DataID4Vld "ODI -DataIDFour is being requested as a valid ID.";
CM_ SG_ 2158952448 ODDMR_DataID4 "ODI - ID for the fourth requested data parameter as defined in the FUDatabase";
CM_ SG_ 2158952448 ODDMR_DataID5Vld "ODI -DataIDFive is being requested as a valid ID.";
CM_ SG_ 2158952448 ODDMR_DataID5 "ODI - ID for the fifth requested data parameter as defined in the FUDatabase";
BA_DEF_  "BusType" STRING ;
BA_DEF_ SG_  "VNSigPrimaryTriggering" ENUM  "No","Yes";
BA_DEF_ SG_  "VNSigRemoteDiagnostics" ENUM  "No","Yes";
BA_DEF_ SG_  "VNSigInfotainment" ENUM  "No","Yes";
BA_DEF_ SG_  "VNSigParkedVehicle" ENUM  "No","Yes";
BA_DEF_ SG_  "VNSigIntermediate" ENUM  "No","Yes";
BA_DEF_ SG_  "VNSigUnused_4" ENUM  "No","Yes";
BA_DEF_ SG_  "SignalType" STRING ;
BA_DEF_ SG_  "PacketOrder" INT 0 65535;
BA_DEF_ SG_  "SignalLongName" STRING ;
BA_DEF_ SG_  "GenSigStartValue" INT 0 65535;
BA_DEF_ SG_  "VNSigDiagnostic" ENUM  "No","Yes";
BA_DEF_ SG_  "VNSigAllNodes" ENUM  "No","Yes";
BA_DEF_ SG_  "GenSigDeltaValue" INT 0 0;
BA_DEF_ SG_  "GenSigSendType" ENUM  "not used","not used","not used","not used","not used","not used","not used","NoSigSendType","not used","not used","OnAnyChange","OnChangeIfActive","OnDelta";
BA_DEF_ SG_  "GenSigSendOnInit" ENUM  "Not Initialized","Application","Handler";
BA_DEF_ BO_  "AppGenMsgCycleTime" INT 0 0;
BA_DEF_ BO_  "TpTxIndex" INT 0 99;
BA_DEF_ BO_  "GenMsgILSupport" ENUM  "No","Yes";
BA_DEF_ BO_  "TpApplType" STRING ;
BA_DEF_ BO_  "Prio" INT 0 7;
BA_DEF_ BO_  "MessageSubnet" ENUM  "LS","HS","CE","PE","HV","FO","LE","HE2","PHS","PCE","DLCLS","DLCHS","DLCCE","DLCFO";
BA_DEF_ BO_  "GenMsgMandatoryToSupervision" ENUM  "No","Yes";
BA_DEF_ BO_  "DiagState" ENUM  "No","Yes";
BA_DEF_ BO_  "GenMsgStartDelayTime" INT 0 100000;
BA_DEF_ BO_  "GenMsgDelayTime" INT 0 100000;
BA_DEF_ BO_  "GenMsgCycleTime" INT 0 100000;
BA_DEF_ BO_  "GenMsgCycleTimeFast" INT 0 100000;
BA_DEF_ BO_  "GenMsgSendType" ENUM  "cyclicX","spontanX","cyclicIfActiveX","spontanWithDelay","cyclicAndSpontanX","cyclicAndSpontanWithDelay","spontanWithRepitition","cyclicIfActiveAndSpontanWD";
BA_DEF_ BO_  "DiagResponse" ENUM  "No","Yes";
BA_DEF_ BO_  "DiagRequest" ENUM  "No","Yes";
BA_DEF_ BO_  "NmMessage" ENUM  "No","Yes";
BA_DEF_ BU_  "MessageManagerUsed" ENUM  "No","Yes";
BA_DEF_ BU_  "NmNode" ENUM  "No","Yes";
BA_DEF_ BU_  "ILUsed" ENUM  "No","Yes";
BA_DEF_ BU_  "NodeLayerModules" STRING ;
BA_DEF_ BU_  "VNECUPrimaryTriggering" ENUM  "None","Activator","Remoted","Activator and Remoted","Shared Local";
BA_DEF_ BU_  "VNECUParkedVehicle" ENUM  "None","Activator","Remoted","Activator and Remoted","Shared Local";
BA_DEF_ BU_  "VNECURemoteDiagnostics" ENUM  "None","Activator","Remoted","Activator and Remoted","Shared Local";
BA_DEF_ BU_  "VNECUIntermediate" ENUM  "None","Activator","Remoted","Activator and Remoted","Shared Local";
BA_DEF_ BU_  "VNECUInfotainment" ENUM  "None","Activator","Remoted","Activator and Remoted","Shared Local";
BA_DEF_ BU_  "VNECUAllNodes" ENUM  "None","Activator","Remoted","Activator and Remoted","Shared Local";
BA_DEF_ BU_  "VNECUDiagnostic" ENUM  "None","Activator","Remoted","Activator and Remoted","Shared Local";
BA_DEF_ BU_  "ECU_Id" HEX 0 255;
BA_DEF_ BU_  "SourceId" HEX 0 253;
BA_DEF_  "VersionMonth" INT 0 255;
BA_DEF_  "SyncJumpWidthMax" INT 0 255;
BA_DEF_  "SyncJumpWidthMin" INT 0 255;
BA_DEF_  "SamplePointMax" FLOAT 0 100;
BA_DEF_  "SamplePointMin" FLOAT 0 100;
BA_DEF_  "Baudrate" INT 0 1000000;
BA_DEF_  "VehicleArchitecture" STRING ;
BA_DEF_  "VNInitActPrimaryTriggering" ENUM  "No","Yes";
BA_DEF_  "VN_PrimaryTriggering" INT 0 255;
BA_DEF_  "VN_RemoteDiagnostics" INT 0 255;
BA_DEF_  "VN_Infotainment" INT 0 255;
BA_DEF_  "VN_ParkedVehicle" INT 0 255;
BA_DEF_  "VN_Intermediate" INT 0 255;
BA_DEF_  "VN_Unused_4" INT 0 255;
BA_DEF_  "VNInitActDiagnostic" ENUM  "No","Yes";
BA_DEF_  "VersionNumber" INT 0 65535;
BA_DEF_  "NmMessageCount" INT 0 32;
BA_DEF_  "NmBaseAddress" HEX 0 2032;
BA_DEF_  "NetworkType" STRING ;
BA_DEF_  "VNMFPeriodicInterval" INT 0 65535;
BA_DEF_  "BusWakeUpDelay" INT 0 65535;
BA_DEF_  "BusOffRecoveryTime" INT 0 65535;
BA_DEF_  "NodeStatusMsgID" HEX 0 536870911;
BA_DEF_  "NodeStatusMsgCycleTime" INT 0 65535;
BA_DEF_  "NodeStatusMsgTimeoutTime" INT 0 65535;
BA_DEF_  "UseGMParameterIDs" INT 0 1;
BA_DEF_  "VersionWeek" INT 0 255;
BA_DEF_  "VersionYear" INT 0 255;
BA_DEF_  "VN_AllNodes" INT 0 255;
BA_DEF_  "VN_Diagnostic" INT 0 255;
BA_DEF_  "Manufacturer" ENUM  "DBAG","VAG","BMW","PAG","GM";
BA_DEF_  "NmType" STRING ;
BA_DEF_REL_ BU_SG_REL_  "GenSigSuprvRespComment" STRING ;
BA_DEF_REL_ BU_SG_REL_  "GenSigVBitResp" ENUM  "No","Yes";
BA_DEF_REL_ BU_SG_REL_  "GenSigVBitRespComment" STRING ;
BA_DEF_REL_ BU_SG_REL_  "GenSigVDAFailComment" STRING ;
BA_DEF_REL_ BU_SG_REL_  "GenSigVDAFailResp" ENUM  "No","Yes";
BA_DEF_REL_ BU_SG_REL_  "GenSigRxStartValue" STRING ;
BA_DEF_REL_ BU_SG_REL_  "GenSigSuprvRespSubValue" INT 0 65535;
BA_DEF_REL_ BU_SG_REL_  "GenSigSuprvResp" ENUM  "None","Notify App","Substitute Default";
BA_DEF_REL_ BU_SG_REL_  "GenSigTimeoutMsg" HEX 0 268435455;
BA_DEF_REL_ BU_SG_REL_  "GenSigTimeoutTime" INT 0 15000;
BA_DEF_DEF_  "BusType" "";
BA_DEF_DEF_  "VNSigPrimaryTriggering" "No";
BA_DEF_DEF_  "VNSigRemoteDiagnostics" "No";
BA_DEF_DEF_  "VNSigInfotainment" "No";
BA_DEF_DEF_  "VNSigParkedVehicle" "No";
BA_DEF_DEF_  "VNSigIntermediate" "No";
BA_DEF_DEF_  "VNSigUnused_4" "No";
BA_DEF_DEF_  "SignalType" "";
BA_DEF_DEF_  "PacketOrder" 0;
BA_DEF_DEF_  "SignalLongName" "";
BA_DEF_DEF_  "GenSigStartValue" 0;
BA_DEF_DEF_  "VNSigDiagnostic" "No";
BA_DEF_DEF_  "VNSigAllNodes" "No";
BA_DEF_DEF_  "GenSigDeltaValue" 0;
BA_DEF_DEF_  "GenSigSendType" "NoSigSendType";
BA_DEF_DEF_  "GenSigSendOnInit" "Not Initialized";
BA_DEF_DEF_  "AppGenMsgCycleTime" 0;
BA_DEF_DEF_  "TpTxIndex" 0;
BA_DEF_DEF_  "GenMsgILSupport" "Yes";
BA_DEF_DEF_  "TpApplType" "";
BA_DEF_DEF_  "Prio" 4;
BA_DEF_DEF_  "MessageSubnet" "LS";
BA_DEF_DEF_  "GenMsgMandatoryToSupervision" "No";
BA_DEF_DEF_  "DiagState" "No";
BA_DEF_DEF_  "GenMsgStartDelayTime" 0;
BA_DEF_DEF_  "GenMsgDelayTime" 0;
BA_DEF_DEF_  "GenMsgCycleTime" 0;
BA_DEF_DEF_  "GenMsgCycleTimeFast" 0;
BA_DEF_DEF_  "GenMsgSendType" "spontanX";
BA_DEF_DEF_  "DiagResponse" "No";
BA_DEF_DEF_  "DiagRequest" "No";
BA_DEF_DEF_  "NmMessage" "No";
BA_DEF_DEF_REL_ "GenSigSuprvRespComment" "";
BA_DEF_DEF_REL_ "GenSigVBitResp" "No";
BA_DEF_DEF_REL_ "GenSigVBitRespComment" "";
BA_DEF_DEF_REL_ "GenSigVDAFailComment" "";
BA_DEF_DEF_REL_ "GenSigVDAFailResp" "No";
BA_DEF_DEF_REL_ "GenSigRxStartValue" "";
BA_DEF_DEF_REL_ "GenSigSuprvRespSubValue" 0;
BA_DEF_DEF_REL_ "GenSigSuprvResp" "None";
BA_DEF_DEF_REL_ "GenSigTimeoutMsg" 0;
BA_DEF_DEF_REL_ "GenSigTimeoutTime" 0;
BA_DEF_DEF_  "MessageManagerUsed" "Yes";
BA_DEF_DEF_  "NmNode" "Yes";
BA_DEF_DEF_  "ILUsed" "Yes";
BA_DEF_DEF_  "NodeLayerModules" "gmlan02.dll";
BA_DEF_DEF_  "VNECUPrimaryTriggering" "None";
BA_DEF_DEF_  "VNECUParkedVehicle" "None";
BA_DEF_DEF_  "VNECURemoteDiagnostics" "None";
BA_DEF_DEF_  "VNECUIntermediate" "None";
BA_DEF_DEF_  "VNECUInfotainment" "None";
BA_DEF_DEF_  "VNECUAllNodes" "None";
BA_DEF_DEF_  "VNECUDiagnostic" "None";
BA_DEF_DEF_  "ECU_Id" 0;
BA_DEF_DEF_  "SourceId" 0;
BA_DEF_DEF_  "VersionMonth" 0;
BA_DEF_DEF_  "SyncJumpWidthMax" 0;
BA_DEF_DEF_  "SyncJumpWidthMin" 0;
BA_DEF_DEF_  "SamplePointMax" 0;
BA_DEF_DEF_  "SamplePointMin" 0;
BA_DEF_DEF_  "Baudrate" 0;
BA_DEF_DEF_  "VehicleArchitecture" "";
BA_DEF_DEF_  "VNInitActPrimaryTriggering" "No";
BA_DEF_DEF_  "VN_PrimaryTriggering" 7;
BA_DEF_DEF_  "VN_RemoteDiagnostics" 5;
BA_DEF_DEF_  "VN_Infotainment" 2;
BA_DEF_DEF_  "VN_ParkedVehicle" 6;
BA_DEF_DEF_  "VN_Intermediate" 3;
BA_DEF_DEF_  "VN_Unused_4" 4;
BA_DEF_DEF_  "VNInitActDiagnostic" "No";
BA_DEF_DEF_  "VersionNumber" 0;
BA_DEF_DEF_  "NmMessageCount" 32;
BA_DEF_DEF_  "NmBaseAddress" 1568;
BA_DEF_DEF_  "NetworkType" "";
BA_DEF_DEF_  "VNMFPeriodicInterval" 3000;
BA_DEF_DEF_  "BusWakeUpDelay" 100;
BA_DEF_DEF_  "BusOffRecoveryTime" 0;
BA_DEF_DEF_  "NodeStatusMsgID" 268427264;
BA_DEF_DEF_  "NodeStatusMsgCycleTime" 1200;
BA_DEF_DEF_  "NodeStatusMsgTimeoutTime" 0;
BA_DEF_DEF_  "UseGMParameterIDs" 1;
BA_DEF_DEF_  "VersionWeek" 0;
BA_DEF_DEF_  "VersionYear" 0;
BA_DEF_DEF_  "VN_AllNodes" 1;
BA_DEF_DEF_  "VN_Diagnostic" 0;
BA_DEF_DEF_  "Manufacturer" "GM";
BA_DEF_DEF_  "NmType" "GMLAN";
BA_ "VersionMonth" 19;
BA_ "SyncJumpWidthMax" 3;
BA_ "SyncJumpWidthMin" 2;
BA_ "SamplePointMax" 89.48;
BA_ "SamplePointMin" 85;
BA_ "Baudrate" 33333;
BA_ "VehicleArchitecture" "G2KCA";
BA_ "VNInitActPrimaryTriggering" 1;
BA_ "VNInitActDiagnostic" 1;
BA_ "NetworkType" "Bodybus";
BA_ "BusWakeUpDelay" 70;
BA_ "BusOffRecoveryTime" 3700;
BA_ "NodeStatusMsgID" 335536128;
BA_ "NodeStatusMsgTimeoutTime" 3000;
BA_ "VersionWeek" 38;
BA_ "VersionYear" 19;
BA_ "BusType" "CAN";
BA_ "VNECUInfotainment" BU_ MCTM_LS 2;
BA_ "VNECUAllNodes" BU_ MCTM_LS 2;
BA_ "ECU_Id" BU_ MCTM_LS 58;
BA_ "SourceId" BU_ MCTM_LS 149;
BA_ "VNECUPrimaryTriggering" BU_ TIM_LS 2;
BA_ "VNECUParkedVehicle" BU_ TIM_LS 2;
BA_ "VNECUAllNodes" BU_ TIM_LS 2;
BA_ "VNECUDiagnostic" BU_ TIM_LS 4;
BA_ "ECU_Id" BU_ TIM_LS 54;
BA_ "SourceId" BU_ TIM_LS 117;
BA_ "VNECUPrimaryTriggering" BU_ EOCM2cp_K2_LS 2;
BA_ "VNECUAllNodes" BU_ EOCM2cp_K2_LS 3;
BA_ "VNECUDiagnostic" BU_ EOCM2cp_K2_LS 4;
BA_ "ECU_Id" BU_ EOCM2cp_K2_LS 43;
BA_ "SourceId" BU_ EOCM2cp_K2_LS 219;
BA_ "VNECUPrimaryTriggering" BU_ EOCM2cp_K1_LS 2;
BA_ "VNECUAllNodes" BU_ EOCM2cp_K1_LS 3;
BA_ "VNECUDiagnostic" BU_ EOCM2cp_K1_LS 4;
BA_ "SourceId" BU_ EOCM2cp_K1_LS 108;
BA_ "VNECUPrimaryTriggering" BU_ ADIMa_LS 2;
BA_ "VNECUIntermediate" BU_ ADIMa_LS 3;
BA_ "VNECUAllNodes" BU_ ADIMa_LS 3;
BA_ "VNECUDiagnostic" BU_ ADIMa_LS 4;
BA_ "ECU_Id" BU_ ADIMa_LS 55;
BA_ "SourceId" BU_ ADIMa_LS 9;
BA_ "VNECUPrimaryTriggering" BU_ BCM_LS 2;
BA_ "VNECUParkedVehicle" BU_ BCM_LS 3;
BA_ "VNECURemoteDiagnostics" BU_ BCM_LS 2;
BA_ "VNECUIntermediate" BU_ BCM_LS 3;
BA_ "VNECUInfotainment" BU_ BCM_LS 2;
BA_ "VNECUAllNodes" BU_ BCM_LS 3;
BA_ "VNECUDiagnostic" BU_ BCM_LS 4;
BA_ "ECU_Id" BU_ BCM_LS 33;
BA_ "SourceId" BU_ BCM_LS 64;
BA_ "VNECUPrimaryTriggering" BU_ SAM_SR_LS 2;
BA_ "VNECUAllNodes" BU_ SAM_SR_LS 2;
BA_ "VNECUDiagnostic" BU_ SAM_SR_LS 4;
BA_ "ECU_Id" BU_ SAM_SR_LS 52;
BA_ "SourceId" BU_ SAM_SR_LS 161;
BA_ "VNECUPrimaryTriggering" BU_ SAM_SL_LS 2;
BA_ "VNECUAllNodes" BU_ SAM_SL_LS 2;
BA_ "VNECUDiagnostic" BU_ SAM_SL_LS 4;
BA_ "ECU_Id" BU_ SAM_SL_LS 32;
BA_ "SourceId" BU_ SAM_SL_LS 160;
BA_ "VNECUPrimaryTriggering" BU_ SAM_PR_LS 2;
BA_ "VNECUAllNodes" BU_ SAM_PR_LS 2;
BA_ "VNECUDiagnostic" BU_ SAM_PR_LS 4;
BA_ "ECU_Id" BU_ SAM_PR_LS 61;
BA_ "SourceId" BU_ SAM_PR_LS 163;
BA_ "VNECUPrimaryTriggering" BU_ SAM_PL_LS 2;
BA_ "VNECUAllNodes" BU_ SAM_PL_LS 2;
BA_ "VNECUDiagnostic" BU_ SAM_PL_LS 4;
BA_ "ECU_Id" BU_ SAM_PL_LS 53;
BA_ "SourceId" BU_ SAM_PL_LS 162;
BA_ "VNECUPrimaryTriggering" BU_ CGM3a_LS 2;
BA_ "VNECUParkedVehicle" BU_ CGM3a_LS 2;
BA_ "VNECURemoteDiagnostics" BU_ CGM3a_LS 2;
BA_ "VNECUIntermediate" BU_ CGM3a_LS 2;
BA_ "VNECUInfotainment" BU_ CGM3a_LS 2;
BA_ "VNECUAllNodes" BU_ CGM3a_LS 2;
BA_ "VNECUDiagnostic" BU_ CGM3a_LS 4;
BA_ "ECU_Id" BU_ CGM3a_LS 51;
BA_ "SourceId" BU_ CGM3a_LS 71;
BA_ "VNECUPrimaryTriggering" BU_ VICM_LS 2;
BA_ "VNECUInfotainment" BU_ VICM_LS 2;
BA_ "VNECUAllNodes" BU_ VICM_LS 3;
BA_ "VNECUDiagnostic" BU_ VICM_LS 4;
BA_ "ECU_Id" BU_ VICM_LS 228;
BA_ "SourceId" BU_ VICM_LS 203;
BA_ "VNECUPrimaryTriggering" BU_ ECC_LS 2;
BA_ "VNECUIntermediate" BU_ ECC_LS 2;
BA_ "VNECUAllNodes" BU_ ECC_LS 3;
BA_ "VNECUDiagnostic" BU_ ECC_LS 4;
BA_ "ECU_Id" BU_ ECC_LS 49;
BA_ "SourceId" BU_ ECC_LS 153;
BA_ "VNECUPrimaryTriggering" BU_ PEPS_LS 2;
BA_ "VNECUIntermediate" BU_ PEPS_LS 2;
BA_ "VNECUAllNodes" BU_ PEPS_LS 3;
BA_ "VNECUDiagnostic" BU_ PEPS_LS 4;
BA_ "ECU_Id" BU_ PEPS_LS 34;
BA_ "SourceId" BU_ PEPS_LS 175;
BA_ "VNECUPrimaryTriggering" BU_ AOS_LS 2;
BA_ "VNECUAllNodes" BU_ AOS_LS 2;
BA_ "VNECUDiagnostic" BU_ AOS_LS 4;
BA_ "ECU_Id" BU_ AOS_LS 37;
BA_ "SourceId" BU_ AOS_LS 89;
BA_ "VNECUPrimaryTriggering" BU_ SDM_PR_LS 2;
BA_ "VNECUAllNodes" BU_ SDM_PR_LS 2;
BA_ "VNECUDiagnostic" BU_ SDM_PR_LS 4;
BA_ "ECU_Id" BU_ SDM_PR_LS 39;
BA_ "SourceId" BU_ SDM_PR_LS 88;
BA_ "VNECUPrimaryTriggering" BU_ AOS2_LS 2;
BA_ "VNECUAllNodes" BU_ AOS2_LS 2;
BA_ "VNECUDiagnostic" BU_ AOS2_LS 4;
BA_ "ECU_Id" BU_ AOS2_LS 95;
BA_ "SourceId" BU_ AOS2_LS 95;
BA_ "VNECUPrimaryTriggering" BU_ DLM_LS 2;
BA_ "VNECUAllNodes" BU_ DLM_LS 2;
BA_ "VNECUDiagnostic" BU_ DLM_LS 4;
BA_ "VNECURemoteDiagnostics" BU_ SCCM_2_LS 2;
BA_ "VNECUAllNodes" BU_ SCCM_2_LS 2;
BA_ "VNECUDiagnostic" BU_ SCCM_2_LS 4;
BA_ "ECU_Id" BU_ SCCM_2_LS 62;
BA_ "SourceId" BU_ SCCM_2_LS 233;
BA_ "VNECURemoteDiagnostics" BU_ SCCM_1_LS 2;
BA_ "VNECUAllNodes" BU_ SCCM_1_LS 2;
BA_ "VNECUDiagnostic" BU_ SCCM_1_LS 4;
BA_ "ECU_Id" BU_ SCCM_1_LS 35;
BA_ "SourceId" BU_ SCCM_1_LS 232;
BA_ "ECU_Id" BU_ UPA_LS 57;
BA_ "SourceId" BU_ UPA_LS 187;
BA_ "VNECUPrimaryTriggering" BU_ ADIMb_LS 2;
BA_ "VNECUIntermediate" BU_ ADIMb_LS 3;
BA_ "VNECUAllNodes" BU_ ADIMb_LS 3;
BA_ "VNECUDiagnostic" BU_ ADIMb_LS 4;
BA_ "ECU_Id" BU_ ADIMb_LS 47;
BA_ "SourceId" BU_ ADIMb_LS 8;
BA_ "GenMsgDelayTime" BO_ 2154831872 100;
BA_ "Prio" BO_ 2151759872 3;
BA_ "GenMsgDelayTime" BO_ 2151759872 100;
BA_ "GenMsgILSupport" BO_ 1373 0;
BA_ "TpApplType" BO_ 1373 "DiagUUDTResponse";
BA_ "Prio" BO_ 1373 0;
BA_ "GenMsgILSupport" BO_ 1365 0;
BA_ "TpApplType" BO_ 1365 "DiagUUDTResponse";
BA_ "Prio" BO_ 1365 0;
BA_ "GenMsgILSupport" BO_ 1364 0;
BA_ "TpApplType" BO_ 1364 "DiagUUDTResponse";
BA_ "Prio" BO_ 1364 0;
BA_ "TpApplType" BO_ 1360 "DiagUUDTResponse";
BA_ "Prio" BO_ 1360 0;
BA_ "Prio" BO_ 1616 0;
BA_ "DiagResponse" BO_ 1616 1;
BA_ "Prio" BO_ 1620 0;
BA_ "DiagResponse" BO_ 1620 1;
BA_ "Prio" BO_ 1629 0;
BA_ "DiagResponse" BO_ 1629 1;
BA_ "Prio" BO_ 1621 0;
BA_ "DiagResponse" BO_ 1621 1;
BA_ "Prio" BO_ 596 0;
BA_ "DiagRequest" BO_ 596 1;
BA_ "Prio" BO_ 592 0;
BA_ "DiagRequest" BO_ 592 1;
BA_ "Prio" BO_ 605 0;
BA_ "DiagRequest" BO_ 605 1;
BA_ "Prio" BO_ 597 0;
BA_ "DiagRequest" BO_ 597 1;
BA_ "GenMsgDelayTime" BO_ 2154815488 100;
BA_ "GenMsgDelayTime" BO_ 2154889216 100;
BA_ "GenMsgDelayTime" BO_ 2154881024 100;
BA_ "GenMsgDelayTime" BO_ 2154799104 100;
BA_ "GenMsgDelayTime" BO_ 2154782720 100;
BA_ "GenMsgDelayTime" BO_ 2154774528 100;
BA_ "GenMsgDelayTime" BO_ 2154749952 100;
BA_ "GenMsgCycleTime" BO_ 2153996288 100;
BA_ "GenMsgSendType" BO_ 2153996288 0;
BA_ "GenMsgDelayTime" BO_ 2154741760 100;
BA_ "GenMsgCycleTime" BO_ 2154766336 250;
BA_ "GenMsgSendType" BO_ 2154766336 0;
BA_ "Prio" BO_ 584 0;
BA_ "DiagRequest" BO_ 584 1;
BA_ "Prio" BO_ 1608 0;
BA_ "DiagResponse" BO_ 1608 1;
BA_ "Prio" BO_ 1576 0;
BA_ "GenMsgCycleTime" BO_ 1576 3000;
BA_ "GenMsgSendType" BO_ 1576 0;
BA_ "NmMessage" BO_ 1576 1;
BA_ "GenMsgILSupport" BO_ 1352 0;
BA_ "TpApplType" BO_ 1352 "DiagUUDTResponse";
BA_ "Prio" BO_ 1352 0;
BA_ "GenMsgDelayTime" BO_ 2163015680 100;
BA_ "Prio" BO_ 2154872832 0;
BA_ "GenMsgCycleTime" BO_ 2154872832 500;
BA_ "GenMsgSendType" BO_ 2154872832 0;
BA_ "Prio" BO_ 1630 0;
BA_ "DiagResponse" BO_ 1630 1;
BA_ "GenMsgILSupport" BO_ 1374 0;
BA_ "TpApplType" BO_ 1374 "DiagUUDTResponse";
BA_ "Prio" BO_ 1374 0;
BA_ "Prio" BO_ 606 0;
BA_ "DiagRequest" BO_ 606 1;
BA_ "Prio" BO_ 1603 0;
BA_ "DiagResponse" BO_ 1603 1;
BA_ "GenMsgDelayTime" BO_ 2158952448 20;
BA_ "GenSigSendType" SG_ 2154831872 SrcodOpnCmdPrRight_Bkp 10;
BA_ "GenSigSendOnInit" SG_ 2154831872 SrcodOpnCmdPrRight_Bkp 1;
BA_ "SignalType" SG_ 2154831872 SrcodOpnCmdPrRight_Bkp "ENM";
BA_ "SignalLongName" SG_ 2154831872 SrcodOpnCmdPrRight_Bkp "Source of Opening Command Primary Right Back Up";
BA_ "VNSigAllNodes" SG_ 2154831872 SrcodOpnCmdPrRight_Bkp 1;
BA_ "GenSigSendType" SG_ 2154831872 SrcodClsCmdPrRightBkp 10;
BA_ "GenSigSendOnInit" SG_ 2154831872 SrcodClsCmdPrRightBkp 1;
BA_ "SignalType" SG_ 2154831872 SrcodClsCmdPrRightBkp "ENM";
BA_ "SignalLongName" SG_ 2154831872 SrcodClsCmdPrRightBkp "Source of Closing Command Primary Right Back Up";
BA_ "VNSigAllNodes" SG_ 2154831872 SrcodClsCmdPrRightBkp 1;
BA_ "GenSigSendType" SG_ 2154831872 SideDrMtnNotAlwIntPreWrnPrRt_Bkp 10;
BA_ "GenSigSendOnInit" SG_ 2154831872 SideDrMtnNotAlwIntPreWrnPrRt_Bkp 1;
BA_ "SignalType" SG_ 2154831872 SideDrMtnNotAlwIntPreWrnPrRt_Bkp "BLN";
BA_ "SignalLongName" SG_ 2154831872 SideDrMtnNotAlwIntPreWrnPrRt_Bkp "Side Door Motion Not Allowed Interior Preception Warning Primary Right Back Up";
BA_ "VNSigAllNodes" SG_ 2154831872 SideDrMtnNotAlwIntPreWrnPrRt_Bkp 1;
BA_ "GenSigSendType" SG_ 2154831872 SideDrMtnNtAlwExtPreWrnPrRt_Bkp 10;
BA_ "GenSigSendOnInit" SG_ 2154831872 SideDrMtnNtAlwExtPreWrnPrRt_Bkp 1;
BA_ "SignalType" SG_ 2154831872 SideDrMtnNtAlwExtPreWrnPrRt_Bkp "BLN";
BA_ "SignalLongName" SG_ 2154831872 SideDrMtnNtAlwExtPreWrnPrRt_Bkp "Side Door Motion Not Allowed Exterior Preception Warning Primary Right Back Up";
BA_ "VNSigAllNodes" SG_ 2154831872 SideDrMtnNtAlwExtPreWrnPrRt_Bkp 1;
BA_ "GenSigSendType" SG_ 2154831872 SAM_PriIndRtDrCmnd_Bkp 10;
BA_ "GenSigSendOnInit" SG_ 2154831872 SAM_PriIndRtDrCmnd_Bkp 1;
BA_ "SignalType" SG_ 2154831872 SAM_PriIndRtDrCmnd_Bkp "ENM";
BA_ "SignalLongName" SG_ 2154831872 SAM_PriIndRtDrCmnd_Bkp "SAM Primary Right Door Command Back Up";
BA_ "VNSigAllNodes" SG_ 2154831872 SAM_PriIndRtDrCmnd_Bkp 1;
BA_ "GenSigSendType" SG_ 2154831872 SAMPriRtDrAlw_Bkp 10;
BA_ "GenSigSendOnInit" SG_ 2154831872 SAMPriRtDrAlw_Bkp 1;
BA_ "SignalType" SG_ 2154831872 SAMPriRtDrAlw_Bkp "ENM";
BA_ "SignalLongName" SG_ 2154831872 SAMPriRtDrAlw_Bkp "SAM Primary Right Door Allow Back Up";
BA_ "GenSigStartValue" SG_ 2154831872 SAMPriRtDrAlw_Bkp 7;
BA_ "VNSigAllNodes" SG_ 2154831872 SAMPriRtDrAlw_Bkp 1;
BA_ "SignalType" SG_ 2151759872 RrClsRelRq "ENM";
BA_ "SignalLongName" SG_ 2151759872 RrClsRelRq "Rear Closure Release Request";
BA_ "SignalType" SG_ 2151759872 CLRAF_UnandRsv3 "BLN";
BA_ "PacketOrder" SG_ 2151759872 CLRAF_UnandRsv3 11;
BA_ "SignalLongName" SG_ 2151759872 CLRAF_UnandRsv3 "Central Locking Request with Extended Activating Functions : Unused and Reserved 3";
BA_ "SignalType" SG_ 2151759872 CLRAF_UnandRsv2 "BLN";
BA_ "PacketOrder" SG_ 2151759872 CLRAF_UnandRsv2 10;
BA_ "SignalLongName" SG_ 2151759872 CLRAF_UnandRsv2 "Central Locking Request with Extended Activating Functions : Unused and Reserved 2";
BA_ "SignalType" SG_ 2151759872 CLRAF_UnandRsv1 "BLN";
BA_ "PacketOrder" SG_ 2151759872 CLRAF_UnandRsv1 9;
BA_ "SignalLongName" SG_ 2151759872 CLRAF_UnandRsv1 "Central Locking Request with Extended Activating Functions : Unused and Reserved 1";
BA_ "SignalType" SG_ 2151759872 CLRAF_Unl_Lk "ENM";
BA_ "PacketOrder" SG_ 2151759872 CLRAF_Unl_Lk 1;
BA_ "SignalLongName" SG_ 2151759872 CLRAF_Unl_Lk "Central Locking Request with Extended Activating Functions : Unlock/Lock";
BA_ "SignalType" SG_ 2151759872 CLRAF_RRD "BLN";
BA_ "PacketOrder" SG_ 2151759872 CLRAF_RRD 4;
BA_ "SignalLongName" SG_ 2151759872 CLRAF_RRD "Central Locking Request with Extended Activating Functions : Rear Right Door";
BA_ "SignalType" SG_ 2151759872 CLRAF_RLD "BLN";
BA_ "PacketOrder" SG_ 2151759872 CLRAF_RLD 5;
BA_ "SignalLongName" SG_ 2151759872 CLRAF_RLD "Central Locking Request with Extended Activating Functions : Rear Left Door";
BA_ "SignalType" SG_ 2151759872 CLRAF_RrCls "BLN";
BA_ "PacketOrder" SG_ 2151759872 CLRAF_RrCls 7;
BA_ "SignalLongName" SG_ 2151759872 CLRAF_RrCls "Central Locking Request with Extended Activating Functions : Rear Closure";
BA_ "SignalType" SG_ 2151759872 CLRAF_PD "BLN";
BA_ "PacketOrder" SG_ 2151759872 CLRAF_PD 3;
BA_ "SignalLongName" SG_ 2151759872 CLRAF_PD "Central Locking Request with Extended Activating Functions : Passenger Door";
BA_ "SignalType" SG_ 2151759872 CLRAF_Hd "BLN";
BA_ "PacketOrder" SG_ 2151759872 CLRAF_Hd 6;
BA_ "SignalLongName" SG_ 2151759872 CLRAF_Hd "Central Locking Request with Extended Activating Functions : Hood";
BA_ "SignalType" SG_ 2151759872 CLRAF_FuelD "BLN";
BA_ "PacketOrder" SG_ 2151759872 CLRAF_FuelD 8;
BA_ "SignalLongName" SG_ 2151759872 CLRAF_FuelD "Central Locking Request with Extended Activating Functions : Fuel Door";
BA_ "SignalType" SG_ 2151759872 CLRAF_DD "BLN";
BA_ "PacketOrder" SG_ 2151759872 CLRAF_DD 2;
BA_ "SignalLongName" SG_ 2151759872 CLRAF_DD "Central Locking Request with Extended Activating Functions : Driver Door";
BA_ "SignalType" SG_ 2151759872 CLRAF_ActFunc "ENM";
BA_ "PacketOrder" SG_ 2151759872 CLRAF_ActFunc 12;
BA_ "SignalLongName" SG_ 2151759872 CLRAF_ActFunc "Central Locking Request with Extended Activating Functions : Activating Function";
BA_ "SignalType" SG_ 1373 DgnInf_LS55D "UNM";
BA_ "SignalLongName" SG_ 1373 DgnInf_LS55D "Diagnostic Information LS55D";
BA_ "VNSigDiagnostic" SG_ 1373 DgnInf_LS55D 1;
BA_ "VNSigAllNodes" SG_ 1373 DgnInf_LS55D 1;
BA_ "SignalType" SG_ 1365 DgnInf_LS555 "UNM";
BA_ "SignalLongName" SG_ 1365 DgnInf_LS555 "Diagnostic Information LS555";
BA_ "VNSigDiagnostic" SG_ 1365 DgnInf_LS555 1;
BA_ "VNSigAllNodes" SG_ 1365 DgnInf_LS555 1;
BA_ "SignalType" SG_ 1364 DgnInf_LS554 "UNM";
BA_ "SignalLongName" SG_ 1364 DgnInf_LS554 "Diagnostic Information LS554";
BA_ "VNSigDiagnostic" SG_ 1364 DgnInf_LS554 1;
BA_ "VNSigAllNodes" SG_ 1364 DgnInf_LS554 1;
BA_ "SignalType" SG_ 1360 DgnInf_LS550 "UNM";
BA_ "SignalLongName" SG_ 1360 DgnInf_LS550 "Diagnostic Information LS550";
BA_ "VNSigDiagnostic" SG_ 1360 DgnInf_LS550 1;
BA_ "VNSigAllNodes" SG_ 1360 DgnInf_LS550 1;
BA_ "SignalType" SG_ 1616 DgnInf "UNM";
BA_ "SignalLongName" SG_ 1616 DgnInf "Diagnostic Information";
BA_ "VNSigDiagnostic" SG_ 1616 DgnInf 1;
BA_ "VNSigAllNodes" SG_ 1616 DgnInf 1;
BA_ "SignalType" SG_ 1620 DgnInf "UNM";
BA_ "SignalLongName" SG_ 1620 DgnInf "Diagnostic Information";
BA_ "VNSigDiagnostic" SG_ 1620 DgnInf 1;
BA_ "VNSigAllNodes" SG_ 1620 DgnInf 1;
BA_ "SignalType" SG_ 1629 DgnInf "UNM";
BA_ "SignalLongName" SG_ 1629 DgnInf "Diagnostic Information";
BA_ "VNSigDiagnostic" SG_ 1629 DgnInf 1;
BA_ "VNSigAllNodes" SG_ 1629 DgnInf 1;
BA_ "SignalType" SG_ 1621 DgnInf "UNM";
BA_ "SignalLongName" SG_ 1621 DgnInf "Diagnostic Information";
BA_ "VNSigDiagnostic" SG_ 1621 DgnInf 1;
BA_ "VNSigAllNodes" SG_ 1621 DgnInf 1;
BA_ "SignalType" SG_ 596 DgnInf "UNM";
BA_ "SignalLongName" SG_ 596 DgnInf "Diagnostic Information";
BA_ "VNSigDiagnostic" SG_ 596 DgnInf 1;
BA_ "VNSigAllNodes" SG_ 596 DgnInf 1;
BA_ "SignalType" SG_ 592 DgnInf "UNM";
BA_ "SignalLongName" SG_ 592 DgnInf "Diagnostic Information";
BA_ "VNSigDiagnostic" SG_ 592 DgnInf 1;
BA_ "VNSigAllNodes" SG_ 592 DgnInf 1;
BA_ "SignalType" SG_ 605 DgnInf "UNM";
BA_ "SignalLongName" SG_ 605 DgnInf "Diagnostic Information";
BA_ "VNSigDiagnostic" SG_ 605 DgnInf 1;
BA_ "VNSigAllNodes" SG_ 605 DgnInf 1;
BA_ "SignalType" SG_ 597 DgnInf "UNM";
BA_ "SignalLongName" SG_ 597 DgnInf "Diagnostic Information";
BA_ "VNSigDiagnostic" SG_ 597 DgnInf 1;
BA_ "VNSigAllNodes" SG_ 597 DgnInf 1;
BA_ "GenSigSendType" SG_ 2154815488 SrcodOpnCmdPrLeft 10;
BA_ "GenSigSendOnInit" SG_ 2154815488 SrcodOpnCmdPrLeft 1;
BA_ "SignalType" SG_ 2154815488 SrcodOpnCmdPrLeft "ENM";
BA_ "SignalLongName" SG_ 2154815488 SrcodOpnCmdPrLeft "Source of Opening Command Primary Left";
BA_ "VNSigAllNodes" SG_ 2154815488 SrcodOpnCmdPrLeft 1;
BA_ "GenSigSendType" SG_ 2154815488 SrcodClsCmdPrLeft 10;
BA_ "GenSigSendOnInit" SG_ 2154815488 SrcodClsCmdPrLeft 1;
BA_ "SignalType" SG_ 2154815488 SrcodClsCmdPrLeft "ENM";
BA_ "SignalLongName" SG_ 2154815488 SrcodClsCmdPrLeft "Source of Closing Command Primary Left";
BA_ "VNSigAllNodes" SG_ 2154815488 SrcodClsCmdPrLeft 1;
BA_ "GenSigSendType" SG_ 2154815488 SideDrMtnNotAlwIntPreWarnPrLeft 10;
BA_ "GenSigSendOnInit" SG_ 2154815488 SideDrMtnNotAlwIntPreWarnPrLeft 1;
BA_ "SignalType" SG_ 2154815488 SideDrMtnNotAlwIntPreWarnPrLeft "BLN";
BA_ "SignalLongName" SG_ 2154815488 SideDrMtnNotAlwIntPreWarnPrLeft "Side Door Motion Not Allowed Interior Preception Warning Primary Left";
BA_ "VNSigAllNodes" SG_ 2154815488 SideDrMtnNotAlwIntPreWarnPrLeft 1;
BA_ "GenSigSendType" SG_ 2154815488 SideDrMtnNotAlwExtPreWarnPrLeft 10;
BA_ "GenSigSendOnInit" SG_ 2154815488 SideDrMtnNotAlwExtPreWarnPrLeft 1;
BA_ "SignalType" SG_ 2154815488 SideDrMtnNotAlwExtPreWarnPrLeft "BLN";
BA_ "SignalLongName" SG_ 2154815488 SideDrMtnNotAlwExtPreWarnPrLeft "Side Door Motion Not Allowed Exterior Preception Warning Primary Left";
BA_ "VNSigAllNodes" SG_ 2154815488 SideDrMtnNotAlwExtPreWarnPrLeft 1;
BA_ "GenSigSendType" SG_ 2154815488 SAM_PriIndRtDrCmnd 10;
BA_ "GenSigSendOnInit" SG_ 2154815488 SAM_PriIndRtDrCmnd 1;
BA_ "SignalType" SG_ 2154815488 SAM_PriIndRtDrCmnd "ENM";
BA_ "SignalLongName" SG_ 2154815488 SAM_PriIndRtDrCmnd "SAM Primary Left Door Command";
BA_ "VNSigAllNodes" SG_ 2154815488 SAM_PriIndRtDrCmnd 1;
BA_ "GenSigSendType" SG_ 2154815488 SAMPriRtDrAlw 10;
BA_ "GenSigSendOnInit" SG_ 2154815488 SAMPriRtDrAlw 1;
BA_ "SignalType" SG_ 2154815488 SAMPriRtDrAlw "ENM";
BA_ "SignalLongName" SG_ 2154815488 SAMPriRtDrAlw "SAM Primary Left Door Allow";
BA_ "GenSigStartValue" SG_ 2154815488 SAMPriRtDrAlw 7;
BA_ "VNSigAllNodes" SG_ 2154815488 SAMPriRtDrAlw 1;
BA_ "GenSigSendType" SG_ 2154889216 AntiPi2DetFbPriDrLeft 10;
BA_ "GenSigSendOnInit" SG_ 2154889216 AntiPi2DetFbPriDrLeft 1;
BA_ "PacketOrder" SG_ 2154889216 AntiPi2DetFbPriDrLeft 8;
BA_ "SignalType" SG_ 2154889216 AntiPi2DetFbPriDrLeft "BLN";
BA_ "SignalLongName" SG_ 2154889216 AntiPi2DetFbPriDrLeft "Primary Door Left : Anti-Pinch 2 Detected Feedback";
BA_ "VNSigAllNodes" SG_ 2154889216 AntiPi2DetFbPriDrLeft 1;
BA_ "GenSigSendType" SG_ 2154889216 PosFedbkPriDrLeft 10;
BA_ "GenSigSendOnInit" SG_ 2154889216 PosFedbkPriDrLeft 1;
BA_ "SignalType" SG_ 2154889216 PosFedbkPriDrLeft "UNM";
BA_ "SignalLongName" SG_ 2154889216 PosFedbkPriDrLeft "Primary Door Left : Position Feedback";
BA_ "VNSigAllNodes" SG_ 2154889216 PosFedbkPriDrLeft 1;
BA_ "GenSigSendType" SG_ 2154889216 ObsDetFbPriDrLeft 10;
BA_ "GenSigSendOnInit" SG_ 2154889216 ObsDetFbPriDrLeft 1;
BA_ "PacketOrder" SG_ 2154889216 ObsDetFbPriDrLeft 6;
BA_ "SignalType" SG_ 2154889216 ObsDetFbPriDrLeft "BLN";
BA_ "SignalLongName" SG_ 2154889216 ObsDetFbPriDrLeft "Primary Door Left : Obstacle Detected _motor stall  Feedback";
BA_ "VNSigAllNodes" SG_ 2154889216 ObsDetFbPriDrLeft 1;
BA_ "GenSigSendType" SG_ 2154889216 Ltch3OPnDrPriDrLeft 10;
BA_ "GenSigSendOnInit" SG_ 2154889216 Ltch3OPnDrPriDrLeft 1;
BA_ "PacketOrder" SG_ 2154889216 Ltch3OPnDrPriDrLeft 2;
BA_ "SignalType" SG_ 2154889216 Ltch3OPnDrPriDrLeft "BLN";
BA_ "SignalLongName" SG_ 2154889216 Ltch3OPnDrPriDrLeft "Primary Door Left : Latch 3 OPEN Status";
BA_ "VNSigAllNodes" SG_ 2154889216 Ltch3OPnDrPriDrLeft 1;
BA_ "GenSigSendType" SG_ 2154889216 Ltch2OpnDrPriDrLeft 10;
BA_ "GenSigSendOnInit" SG_ 2154889216 Ltch2OpnDrPriDrLeft 1;
BA_ "PacketOrder" SG_ 2154889216 Ltch2OpnDrPriDrLeft 1;
BA_ "SignalType" SG_ 2154889216 Ltch2OpnDrPriDrLeft "BLN";
BA_ "SignalLongName" SG_ 2154889216 Ltch2OpnDrPriDrLeft "Primary Door Left : Latch 2 OPEN Status";
BA_ "VNSigAllNodes" SG_ 2154889216 Ltch2OpnDrPriDrLeft 1;
BA_ "GenSigSendType" SG_ 2154889216 Ltch1OpbstsPriDrLeft 10;
BA_ "GenSigSendOnInit" SG_ 2154889216 Ltch1OpbstsPriDrLeft 1;
BA_ "SignalType" SG_ 2154889216 Ltch1OpbstsPriDrLeft "BLN";
BA_ "SignalLongName" SG_ 2154889216 Ltch1OpbstsPriDrLeft "Primary Door Left : Latch 1 OPEN Status";
BA_ "VNSigAllNodes" SG_ 2154889216 Ltch1OpbstsPriDrLeft 1;
BA_ "GenSigSendType" SG_ 2154889216 DrMotCmpltOpnPriDrLeft 10;
BA_ "GenSigSendOnInit" SG_ 2154889216 DrMotCmpltOpnPriDrLeft 1;
BA_ "SignalType" SG_ 2154889216 DrMotCmpltOpnPriDrLeft "BLN";
BA_ "SignalLongName" SG_ 2154889216 DrMotCmpltOpnPriDrLeft "Primary Door Left : Door Motion Complete OPEN";
BA_ "VNSigAllNodes" SG_ 2154889216 DrMotCmpltOpnPriDrLeft 1;
BA_ "GenSigSendType" SG_ 2154889216 DrMotCmpltClsSecDrLeft 10;
BA_ "GenSigSendOnInit" SG_ 2154889216 DrMotCmpltClsSecDrLeft 1;
BA_ "SignalType" SG_ 2154889216 DrMotCmpltClsSecDrLeft "BLN";
BA_ "SignalLongName" SG_ 2154889216 DrMotCmpltClsSecDrLeft "Primary Door Left : Door Motion Complete CLOSE";
BA_ "VNSigAllNodes" SG_ 2154889216 DrMotCmpltClsSecDrLeft 1;
BA_ "GenSigSendType" SG_ 2154889216 DrInMotPriLeft 10;
BA_ "GenSigSendOnInit" SG_ 2154889216 DrInMotPriLeft 1;
BA_ "SignalType" SG_ 2154889216 DrInMotPriLeft "BLN";
BA_ "SignalLongName" SG_ 2154889216 DrInMotPriLeft "Primary Door Left : Door In Motion";
BA_ "VNSigAllNodes" SG_ 2154889216 DrInMotPriLeft 1;
BA_ "GenSigSendType" SG_ 2154889216 DrClsPsnLtchRatSdeOfVehLeft 10;
BA_ "GenSigSendOnInit" SG_ 2154889216 DrClsPsnLtchRatSdeOfVehLeft 1;
BA_ "PacketOrder" SG_ 2154889216 DrClsPsnLtchRatSdeOfVehLeft 3;
BA_ "SignalType" SG_ 2154889216 DrClsPsnLtchRatSdeOfVehLeft "BLN";
BA_ "SignalLongName" SG_ 2154889216 DrClsPsnLtchRatSdeOfVehLeft "Primary Door Left : Door Closed : Position & Latch Rationality  : Side of Vehicle";
BA_ "VNSigAllNodes" SG_ 2154889216 DrClsPsnLtchRatSdeOfVehLeft 1;
BA_ "GenSigSendType" SG_ 2154889216 DrClsPsnLtchRatPriDrLeft 10;
BA_ "GenSigSendOnInit" SG_ 2154889216 DrClsPsnLtchRatPriDrLeft 1;
BA_ "PacketOrder" SG_ 2154889216 DrClsPsnLtchRatPriDrLeft 3;
BA_ "SignalType" SG_ 2154889216 DrClsPsnLtchRatPriDrLeft "BLN";
BA_ "SignalLongName" SG_ 2154889216 DrClsPsnLtchRatPriDrLeft "Primary Door Left : Door Closed : Position & Latch Rationality ";
BA_ "VNSigAllNodes" SG_ 2154889216 DrClsPsnLtchRatPriDrLeft 1;
BA_ "GenSigSendType" SG_ 2154889216 AntiPi1DetFbPriDrLeft 10;
BA_ "GenSigSendOnInit" SG_ 2154889216 AntiPi1DetFbPriDrLeft 1;
BA_ "PacketOrder" SG_ 2154889216 AntiPi1DetFbPriDrLeft 7;
BA_ "SignalType" SG_ 2154889216 AntiPi1DetFbPriDrLeft "BLN";
BA_ "SignalLongName" SG_ 2154889216 AntiPi1DetFbPriDrLeft "Primary Door Left : Anti-Pinch 1 Detected Feedback";
BA_ "VNSigAllNodes" SG_ 2154889216 AntiPi1DetFbPriDrLeft 1;
BA_ "GenSigSendType" SG_ 2154889216 IntOpenswtReqLftSide 10;
BA_ "GenSigSendOnInit" SG_ 2154889216 IntOpenswtReqLftSide 1;
BA_ "SignalType" SG_ 2154889216 IntOpenswtReqLftSide "BLN";
BA_ "PacketOrder" SG_ 2154889216 IntOpenswtReqLftSide 1;
BA_ "SignalLongName" SG_ 2154889216 IntOpenswtReqLftSide "Request Left Side :Interior Open Swith";
BA_ "VNSigAllNodes" SG_ 2154889216 IntOpenswtReqLftSide 1;
BA_ "GenSigSendType" SG_ 2154889216 IntClseswtReqLftSide 10;
BA_ "GenSigSendOnInit" SG_ 2154889216 IntClseswtReqLftSide 1;
BA_ "SignalType" SG_ 2154889216 IntClseswtReqLftSide "BLN";
BA_ "PacketOrder" SG_ 2154889216 IntClseswtReqLftSide 1;
BA_ "SignalLongName" SG_ 2154889216 IntClseswtReqLftSide "Request Left Side :Interior Close Switch";
BA_ "VNSigAllNodes" SG_ 2154889216 IntClseswtReqLftSide 1;
BA_ "GenSigSendType" SG_ 2154889216 ExtOpnClsSwReqLftSde 10;
BA_ "GenSigSendOnInit" SG_ 2154889216 ExtOpnClsSwReqLftSde 1;
BA_ "SignalType" SG_ 2154889216 ExtOpnClsSwReqLftSde "BLN";
BA_ "PacketOrder" SG_ 2154889216 ExtOpnClsSwReqLftSde 1;
BA_ "SignalLongName" SG_ 2154889216 ExtOpnClsSwReqLftSde "Request Left Side : Exterior Open/Close Switch ";
BA_ "VNSigAllNodes" SG_ 2154889216 ExtOpnClsSwReqLftSde 1;
BA_ "GenSigSendType" SG_ 2154881024 PosFedbkPriDrRight 10;
BA_ "GenSigSendOnInit" SG_ 2154881024 PosFedbkPriDrRight 1;
BA_ "SignalType" SG_ 2154881024 PosFedbkPriDrRight "UNM";
BA_ "SignalLongName" SG_ 2154881024 PosFedbkPriDrRight "Primary Door Right : Position Feedback";
BA_ "VNSigAllNodes" SG_ 2154881024 PosFedbkPriDrRight 1;
BA_ "GenSigSendType" SG_ 2154881024 ObsDetFbPriDrRight 10;
BA_ "GenSigSendOnInit" SG_ 2154881024 ObsDetFbPriDrRight 1;
BA_ "PacketOrder" SG_ 2154881024 ObsDetFbPriDrRight 6;
BA_ "SignalType" SG_ 2154881024 ObsDetFbPriDrRight "BLN";
BA_ "SignalLongName" SG_ 2154881024 ObsDetFbPriDrRight "Primary Door Right : Obstacle Detected _motor stall  Feedback";
BA_ "VNSigAllNodes" SG_ 2154881024 ObsDetFbPriDrRight 1;
BA_ "GenSigSendType" SG_ 2154881024 Ltch3OPnDrPriDrRight 10;
BA_ "GenSigSendOnInit" SG_ 2154881024 Ltch3OPnDrPriDrRight 1;
BA_ "PacketOrder" SG_ 2154881024 Ltch3OPnDrPriDrRight 2;
BA_ "SignalType" SG_ 2154881024 Ltch3OPnDrPriDrRight "BLN";
BA_ "SignalLongName" SG_ 2154881024 Ltch3OPnDrPriDrRight "Primary Door Right : Latch 3 OPEN Status";
BA_ "VNSigAllNodes" SG_ 2154881024 Ltch3OPnDrPriDrRight 1;
BA_ "GenSigSendType" SG_ 2154881024 Ltch2OpnDrPriDrRight 10;
BA_ "GenSigSendOnInit" SG_ 2154881024 Ltch2OpnDrPriDrRight 1;
BA_ "PacketOrder" SG_ 2154881024 Ltch2OpnDrPriDrRight 1;
BA_ "SignalType" SG_ 2154881024 Ltch2OpnDrPriDrRight "BLN";
BA_ "SignalLongName" SG_ 2154881024 Ltch2OpnDrPriDrRight "Primary Door Right : Latch 2 OPEN Status";
BA_ "VNSigAllNodes" SG_ 2154881024 Ltch2OpnDrPriDrRight 1;
BA_ "GenSigSendType" SG_ 2154881024 Ltch1OpbstsPriDrRight 10;
BA_ "GenSigSendOnInit" SG_ 2154881024 Ltch1OpbstsPriDrRight 1;
BA_ "SignalType" SG_ 2154881024 Ltch1OpbstsPriDrRight "BLN";
BA_ "SignalLongName" SG_ 2154881024 Ltch1OpbstsPriDrRight "Primary Door Right : Latch 1 OPEN Status";
BA_ "VNSigAllNodes" SG_ 2154881024 Ltch1OpbstsPriDrRight 1;
BA_ "GenSigSendType" SG_ 2154881024 DrMotCmpltOpnPriDrRight 10;
BA_ "GenSigSendOnInit" SG_ 2154881024 DrMotCmpltOpnPriDrRight 1;
BA_ "SignalType" SG_ 2154881024 DrMotCmpltOpnPriDrRight "BLN";
BA_ "SignalLongName" SG_ 2154881024 DrMotCmpltOpnPriDrRight "Primary Door Right : Door Motion Complete OPEN";
BA_ "VNSigAllNodes" SG_ 2154881024 DrMotCmpltOpnPriDrRight 1;
BA_ "GenSigSendType" SG_ 2154881024 DrMotCmpltClsSecDrRight 10;
BA_ "GenSigSendOnInit" SG_ 2154881024 DrMotCmpltClsSecDrRight 1;
BA_ "SignalType" SG_ 2154881024 DrMotCmpltClsSecDrRight "BLN";
BA_ "SignalLongName" SG_ 2154881024 DrMotCmpltClsSecDrRight "Primary Door Right : Door Motion Complete CLOSE";
BA_ "VNSigAllNodes" SG_ 2154881024 DrMotCmpltClsSecDrRight 1;
BA_ "GenSigSendType" SG_ 2154881024 DrInMotPriRight 10;
BA_ "GenSigSendOnInit" SG_ 2154881024 DrInMotPriRight 1;
BA_ "SignalType" SG_ 2154881024 DrInMotPriRight "BLN";
BA_ "SignalLongName" SG_ 2154881024 DrInMotPriRight "Primary Door Right : Door In Motion";
BA_ "VNSigAllNodes" SG_ 2154881024 DrInMotPriRight 1;
BA_ "GenSigSendType" SG_ 2154881024 DrClsPsnLtchRatSdeOfVehRight 10;
BA_ "GenSigSendOnInit" SG_ 2154881024 DrClsPsnLtchRatSdeOfVehRight 1;
BA_ "PacketOrder" SG_ 2154881024 DrClsPsnLtchRatSdeOfVehRight 3;
BA_ "SignalType" SG_ 2154881024 DrClsPsnLtchRatSdeOfVehRight "BLN";
BA_ "SignalLongName" SG_ 2154881024 DrClsPsnLtchRatSdeOfVehRight "Primary Door Right : Door Closed : Position & Latch Rationality  : Side of Vehicle";
BA_ "VNSigAllNodes" SG_ 2154881024 DrClsPsnLtchRatSdeOfVehRight 1;
BA_ "GenSigSendType" SG_ 2154881024 DrClsPsnLtchRatPriDrRight 10;
BA_ "GenSigSendOnInit" SG_ 2154881024 DrClsPsnLtchRatPriDrRight 1;
BA_ "PacketOrder" SG_ 2154881024 DrClsPsnLtchRatPriDrRight 3;
BA_ "SignalType" SG_ 2154881024 DrClsPsnLtchRatPriDrRight "BLN";
BA_ "SignalLongName" SG_ 2154881024 DrClsPsnLtchRatPriDrRight "Primary Door Right : Door Closed : Position & Latch Rationality ";
BA_ "VNSigAllNodes" SG_ 2154881024 DrClsPsnLtchRatPriDrRight 1;
BA_ "GenSigSendType" SG_ 2154881024 AntiPi2DetFbPriDrRight 10;
BA_ "GenSigSendOnInit" SG_ 2154881024 AntiPi2DetFbPriDrRight 1;
BA_ "PacketOrder" SG_ 2154881024 AntiPi2DetFbPriDrRight 8;
BA_ "SignalType" SG_ 2154881024 AntiPi2DetFbPriDrRight "BLN";
BA_ "SignalLongName" SG_ 2154881024 AntiPi2DetFbPriDrRight "Primary Door Right : Anti-Pinch 2 Detected Feedback";
BA_ "VNSigAllNodes" SG_ 2154881024 AntiPi2DetFbPriDrRight 1;
BA_ "GenSigSendType" SG_ 2154881024 AntiPi1DetFbPriDrRight 10;
BA_ "GenSigSendOnInit" SG_ 2154881024 AntiPi1DetFbPriDrRight 1;
BA_ "PacketOrder" SG_ 2154881024 AntiPi1DetFbPriDrRight 7;
BA_ "SignalType" SG_ 2154881024 AntiPi1DetFbPriDrRight "BLN";
BA_ "SignalLongName" SG_ 2154881024 AntiPi1DetFbPriDrRight "Primary Door Right : Anti-Pinch 1 Detected Feedback";
BA_ "VNSigAllNodes" SG_ 2154881024 AntiPi1DetFbPriDrRight 1;
BA_ "GenSigSendType" SG_ 2154881024 IntOpenswtReqRtSide 10;
BA_ "GenSigSendOnInit" SG_ 2154881024 IntOpenswtReqRtSide 1;
BA_ "PacketOrder" SG_ 2154881024 IntOpenswtReqRtSide 1;
BA_ "SignalType" SG_ 2154881024 IntOpenswtReqRtSide "BLN";
BA_ "SignalLongName" SG_ 2154881024 IntOpenswtReqRtSide "Request Right Side :Interior Open Swith";
BA_ "VNSigAllNodes" SG_ 2154881024 IntOpenswtReqRtSide 1;
BA_ "GenSigSendType" SG_ 2154881024 ExtOpnClsSwReqRtSde 10;
BA_ "GenSigSendOnInit" SG_ 2154881024 ExtOpnClsSwReqRtSde 1;
BA_ "PacketOrder" SG_ 2154881024 ExtOpnClsSwReqRtSde 1;
BA_ "SignalType" SG_ 2154881024 ExtOpnClsSwReqRtSde "BLN";
BA_ "SignalLongName" SG_ 2154881024 ExtOpnClsSwReqRtSde "Request Right Side : Exterior Open/Close Switch ";
BA_ "VNSigAllNodes" SG_ 2154881024 ExtOpnClsSwReqRtSde 1;
BA_ "GenSigSendType" SG_ 2154881024 IntClseswtReqRtSide 10;
BA_ "GenSigSendOnInit" SG_ 2154881024 IntClseswtReqRtSide 1;
BA_ "PacketOrder" SG_ 2154881024 IntClseswtReqRtSide 1;
BA_ "SignalType" SG_ 2154881024 IntClseswtReqRtSide "BLN";
BA_ "SignalLongName" SG_ 2154881024 IntClseswtReqRtSide "Request Right Side :Interior Close Switch";
BA_ "VNSigAllNodes" SG_ 2154881024 IntClseswtReqRtSide 1;
BA_ "GenSigSendType" SG_ 2154799104 SAMSecLftDrAlw 10;
BA_ "GenSigSendOnInit" SG_ 2154799104 SAMSecLftDrAlw 1;
BA_ "SignalType" SG_ 2154799104 SAMSecLftDrAlw "ENM";
BA_ "SignalLongName" SG_ 2154799104 SAMSecLftDrAlw "SAM Secondary Left Door Allow";
BA_ "GenSigStartValue" SG_ 2154799104 SAMSecLftDrAlw 7;
BA_ "VNSigAllNodes" SG_ 2154799104 SAMSecLftDrAlw 1;
BA_ "GenSigSendType" SG_ 2154799104 AlwSecLftDrHldOpen 10;
BA_ "GenSigSendOnInit" SG_ 2154799104 AlwSecLftDrHldOpen 1;
BA_ "SignalType" SG_ 2154799104 AlwSecLftDrHldOpen "ENM";
BA_ "SignalLongName" SG_ 2154799104 AlwSecLftDrHldOpen "Allow Secondary Left Door Hold Open ";
BA_ "VNSigAllNodes" SG_ 2154799104 AlwSecLftDrHldOpen 1;
BA_ "GenSigSendType" SG_ 2154799104 Cmnd_SecIndLftDrHldopn 10;
BA_ "GenSigSendOnInit" SG_ 2154799104 Cmnd_SecIndLftDrHldopn 1;
BA_ "SignalType" SG_ 2154799104 Cmnd_SecIndLftDrHldopn "ENM";
BA_ "SignalLongName" SG_ 2154799104 Cmnd_SecIndLftDrHldopn "Command Secondary Left Door Hold Open";
BA_ "VNSigAllNodes" SG_ 2154799104 Cmnd_SecIndLftDrHldopn 1;
BA_ "GenSigSendType" SG_ 2154799104 SAM_SecndLftDrCmnd 10;
BA_ "GenSigSendOnInit" SG_ 2154799104 SAM_SecndLftDrCmnd 1;
BA_ "SignalType" SG_ 2154799104 SAM_SecndLftDrCmnd "ENM";
BA_ "SignalLongName" SG_ 2154799104 SAM_SecndLftDrCmnd "SAM Secondary Left Door Command";
BA_ "VNSigAllNodes" SG_ 2154799104 SAM_SecndLftDrCmnd 1;
BA_ "GenSigSendType" SG_ 2154782720 SrcodOpnCmdPrRight 10;
BA_ "GenSigSendOnInit" SG_ 2154782720 SrcodOpnCmdPrRight 1;
BA_ "SignalType" SG_ 2154782720 SrcodOpnCmdPrRight "ENM";
BA_ "SignalLongName" SG_ 2154782720 SrcodOpnCmdPrRight "Source of Opening Command Primary Right";
BA_ "VNSigAllNodes" SG_ 2154782720 SrcodOpnCmdPrRight 1;
BA_ "GenSigSendType" SG_ 2154782720 SrcodClsCmdPrRight 10;
BA_ "GenSigSendOnInit" SG_ 2154782720 SrcodClsCmdPrRight 1;
BA_ "SignalType" SG_ 2154782720 SrcodClsCmdPrRight "ENM";
BA_ "SignalLongName" SG_ 2154782720 SrcodClsCmdPrRight "Source of Closing Command Primary Right";
BA_ "VNSigAllNodes" SG_ 2154782720 SrcodClsCmdPrRight 1;
BA_ "GenSigSendType" SG_ 2154782720 SAM_PriIndRtDrCmnd 10;
BA_ "GenSigSendOnInit" SG_ 2154782720 SAM_PriIndRtDrCmnd 1;
BA_ "SignalType" SG_ 2154782720 SAM_PriIndRtDrCmnd "ENM";
BA_ "SignalLongName" SG_ 2154782720 SAM_PriIndRtDrCmnd "SAM Primary Right Door Command";
BA_ "VNSigAllNodes" SG_ 2154782720 SAM_PriIndRtDrCmnd 1;
BA_ "GenSigSendType" SG_ 2154782720 SAMPriRtDrAlw 10;
BA_ "GenSigSendOnInit" SG_ 2154782720 SAMPriRtDrAlw 1;
BA_ "SignalType" SG_ 2154782720 SAMPriRtDrAlw "ENM";
BA_ "SignalLongName" SG_ 2154782720 SAMPriRtDrAlw "SAM Primary Right Door Allow";
BA_ "GenSigStartValue" SG_ 2154782720 SAMPriRtDrAlw 7;
BA_ "VNSigAllNodes" SG_ 2154782720 SAMPriRtDrAlw 1;
BA_ "GenSigSendType" SG_ 2154782720 SideDrMtnNotAlwIntPreWarnPrRight 10;
BA_ "GenSigSendOnInit" SG_ 2154782720 SideDrMtnNotAlwIntPreWarnPrRight 1;
BA_ "SignalType" SG_ 2154782720 SideDrMtnNotAlwIntPreWarnPrRight "BLN";
BA_ "SignalLongName" SG_ 2154782720 SideDrMtnNotAlwIntPreWarnPrRight "Side Door Motion Not Allowed Interior Preception Warning Primary Right";
BA_ "VNSigAllNodes" SG_ 2154782720 SideDrMtnNotAlwIntPreWarnPrRight 1;
BA_ "GenSigSendType" SG_ 2154782720 SideDrMtnNotAlwExtPreWarnPrRight 10;
BA_ "GenSigSendOnInit" SG_ 2154782720 SideDrMtnNotAlwExtPreWarnPrRight 1;
BA_ "SignalType" SG_ 2154782720 SideDrMtnNotAlwExtPreWarnPrRight "BLN";
BA_ "SignalLongName" SG_ 2154782720 SideDrMtnNotAlwExtPreWarnPrRight "Side Door Motion Not Allowed Exterior Preception Warning Primary Right";
BA_ "VNSigAllNodes" SG_ 2154782720 SideDrMtnNotAlwExtPreWarnPrRight 1;
BA_ "GenSigSendType" SG_ 2154774528 AntiPn2FltdetLft 10;
BA_ "GenSigSendOnInit" SG_ 2154774528 AntiPn2FltdetLft 1;
BA_ "SignalType" SG_ 2154774528 AntiPn2FltdetLft "BLN";
BA_ "SignalLongName" SG_ 2154774528 AntiPn2FltdetLft "Anti Pinch 2 Fault Detected Left";
BA_ "VNSigAllNodes" SG_ 2154774528 AntiPn2FltdetLft 1;
BA_ "GenSigSendType" SG_ 2154774528 PosSenFltLft 10;
BA_ "GenSigSendOnInit" SG_ 2154774528 PosSenFltLft 1;
BA_ "SignalType" SG_ 2154774528 PosSenFltLft "BLN";
BA_ "SignalLongName" SG_ 2154774528 PosSenFltLft "Position Sensor Fault detected Left";
BA_ "VNSigAllNodes" SG_ 2154774528 PosSenFltLft 1;
BA_ "GenSigSendType" SG_ 2154774528 ActMtrFltDetLft 10;
BA_ "GenSigSendOnInit" SG_ 2154774528 ActMtrFltDetLft 1;
BA_ "SignalType" SG_ 2154774528 ActMtrFltDetLft "BLN";
BA_ "SignalLongName" SG_ 2154774528 ActMtrFltDetLft "Actuator Motor Fault Detected Left";
BA_ "VNSigAllNodes" SG_ 2154774528 ActMtrFltDetLft 1;
BA_ "GenSigSendType" SG_ 2154774528 LtchMtr3FltdetLft 10;
BA_ "GenSigSendOnInit" SG_ 2154774528 LtchMtr3FltdetLft 1;
BA_ "SignalType" SG_ 2154774528 LtchMtr3FltdetLft "BLN";
BA_ "SignalLongName" SG_ 2154774528 LtchMtr3FltdetLft "Latch Motor 3 Fault detected Left";
BA_ "VNSigAllNodes" SG_ 2154774528 LtchMtr3FltdetLft 1;
BA_ "GenSigSendType" SG_ 2154774528 LtchMtr2FltdetLft 10;
BA_ "GenSigSendOnInit" SG_ 2154774528 LtchMtr2FltdetLft 1;
BA_ "SignalType" SG_ 2154774528 LtchMtr2FltdetLft "BLN";
BA_ "SignalLongName" SG_ 2154774528 LtchMtr2FltdetLft "Latch Motor 2 Fault detected Left";
BA_ "VNSigAllNodes" SG_ 2154774528 LtchMtr2FltdetLft 1;
BA_ "GenSigSendType" SG_ 2154774528 LtchMtr1FltdetLft 10;
BA_ "GenSigSendOnInit" SG_ 2154774528 LtchMtr1FltdetLft 1;
BA_ "SignalType" SG_ 2154774528 LtchMtr1FltdetLft "BLN";
BA_ "SignalLongName" SG_ 2154774528 LtchMtr1FltdetLft "Latch Motor 1 Fault detected Left";
BA_ "VNSigAllNodes" SG_ 2154774528 LtchMtr1FltdetLft 1;
BA_ "GenSigSendType" SG_ 2154774528 AntiPn1FltDetLft 10;
BA_ "GenSigSendOnInit" SG_ 2154774528 AntiPn1FltDetLft 1;
BA_ "SignalType" SG_ 2154774528 AntiPn1FltDetLft "BLN";
BA_ "SignalLongName" SG_ 2154774528 AntiPn1FltDetLft "Anti Pinch 1 fault detected Left";
BA_ "VNSigAllNodes" SG_ 2154774528 AntiPn1FltDetLft 1;
BA_ "GenSigSendType" SG_ 2154774528 ContrlUnavbLft 10;
BA_ "GenSigSendOnInit" SG_ 2154774528 ContrlUnavbLft 1;
BA_ "SignalType" SG_ 2154774528 ContrlUnavbLft "BLN";
BA_ "SignalLongName" SG_ 2154774528 ContrlUnavbLft "Controller Unavailable Left (Broken) (Internal Fault)";
BA_ "VNSigAllNodes" SG_ 2154774528 ContrlUnavbLft 1;
BA_ "GenSigSendType" SG_ 2154774528 IntclseswtchactLft 10;
BA_ "GenSigSendOnInit" SG_ 2154774528 IntclseswtchactLft 1;
BA_ "SignalType" SG_ 2154774528 IntclseswtchactLft "BLN";
BA_ "SignalLongName" SG_ 2154774528 IntclseswtchactLft "Interior Close Switch Active Left";
BA_ "VNSigAllNodes" SG_ 2154774528 IntclseswtchactLft 1;
BA_ "GenSigSendType" SG_ 2154774528 IntopenswtchactLft 10;
BA_ "GenSigSendOnInit" SG_ 2154774528 IntopenswtchactLft 1;
BA_ "SignalType" SG_ 2154774528 IntopenswtchactLft "BLN";
BA_ "SignalLongName" SG_ 2154774528 IntopenswtchactLft "Interior Open Switch Active Left";
BA_ "VNSigAllNodes" SG_ 2154774528 IntopenswtchactLft 1;
BA_ "GenSigSendType" SG_ 2154774528 ExtswtchactLft 10;
BA_ "GenSigSendOnInit" SG_ 2154774528 ExtswtchactLft 1;
BA_ "SignalType" SG_ 2154774528 ExtswtchactLft "BLN";
BA_ "SignalLongName" SG_ 2154774528 ExtswtchactLft "Exterior Switch Active Left";
BA_ "VNSigAllNodes" SG_ 2154774528 ExtswtchactLft 1;
BA_ "GenSigSendType" SG_ 2154774528 DrMotCmpltOpnSecDrLft 10;
BA_ "GenSigSendOnInit" SG_ 2154774528 DrMotCmpltOpnSecDrLft 1;
BA_ "PacketOrder" SG_ 2154774528 DrMotCmpltOpnSecDrLft 1;
BA_ "SignalType" SG_ 2154774528 DrMotCmpltOpnSecDrLft "BLN";
BA_ "SignalLongName" SG_ 2154774528 DrMotCmpltOpnSecDrLft "Secondary Door Left : Door Motion Complete OPEN";
BA_ "VNSigAllNodes" SG_ 2154774528 DrMotCmpltOpnSecDrLft 1;
BA_ "GenSigSendType" SG_ 2154774528 DrMotCmpltClsSecDrLft 10;
BA_ "GenSigSendOnInit" SG_ 2154774528 DrMotCmpltClsSecDrLft 1;
BA_ "SignalType" SG_ 2154774528 DrMotCmpltClsSecDrLft "BLN";
BA_ "SignalLongName" SG_ 2154774528 DrMotCmpltClsSecDrLft "Secondary Door Left : Door Motion Complete CLOSE";
BA_ "VNSigAllNodes" SG_ 2154774528 DrMotCmpltClsSecDrLft 1;
BA_ "GenSigSendType" SG_ 2154774528 DrInMotSecLft 10;
BA_ "GenSigSendOnInit" SG_ 2154774528 DrInMotSecLft 1;
BA_ "SignalType" SG_ 2154774528 DrInMotSecLft "BLN";
BA_ "SignalLongName" SG_ 2154774528 DrInMotSecLft "Secondary Door Left : Door In Motion";
BA_ "VNSigAllNodes" SG_ 2154774528 DrInMotSecLft 1;
BA_ "GenSigSendType" SG_ 2154774528 Ltch2OpnDrSecDrLft 10;
BA_ "GenSigSendOnInit" SG_ 2154774528 Ltch2OpnDrSecDrLft 1;
BA_ "SignalType" SG_ 2154774528 Ltch2OpnDrSecDrLft "BLN";
BA_ "PacketOrder" SG_ 2154774528 Ltch2OpnDrSecDrLft 1;
BA_ "SignalLongName" SG_ 2154774528 Ltch2OpnDrSecDrLft "Secondary Door Left : Latch 2 OPEN Status";
BA_ "VNSigAllNodes" SG_ 2154774528 Ltch2OpnDrSecDrLft 1;
BA_ "GenSigSendType" SG_ 2154774528 PosFedbkSecDrLft 10;
BA_ "GenSigSendOnInit" SG_ 2154774528 PosFedbkSecDrLft 1;
BA_ "SignalType" SG_ 2154774528 PosFedbkSecDrLft "UNM";
BA_ "SignalLongName" SG_ 2154774528 PosFedbkSecDrLft "Secondary Door Left : Position Feedback ";
BA_ "VNSigAllNodes" SG_ 2154774528 PosFedbkSecDrLft 1;
BA_ "GenSigSendType" SG_ 2154774528 AntiPi2DetFbSecDrLft 10;
BA_ "GenSigSendOnInit" SG_ 2154774528 AntiPi2DetFbSecDrLft 1;
BA_ "SignalType" SG_ 2154774528 AntiPi2DetFbSecDrLft "BLN";
BA_ "PacketOrder" SG_ 2154774528 AntiPi2DetFbSecDrLft 8;
BA_ "SignalLongName" SG_ 2154774528 AntiPi2DetFbSecDrLft "Secondary Door Left : Anti-Pinch 2 Detected Feedback";
BA_ "VNSigAllNodes" SG_ 2154774528 AntiPi2DetFbSecDrLft 1;
BA_ "GenSigSendType" SG_ 2154774528 ObsDetFbSecDrLft 10;
BA_ "GenSigSendOnInit" SG_ 2154774528 ObsDetFbSecDrLft 1;
BA_ "SignalType" SG_ 2154774528 ObsDetFbSecDrLft "BLN";
BA_ "PacketOrder" SG_ 2154774528 ObsDetFbSecDrLft 6;
BA_ "SignalLongName" SG_ 2154774528 ObsDetFbSecDrLft "Secondary Door Left : Obstacle Detected _motor stall  Feedback";
BA_ "VNSigAllNodes" SG_ 2154774528 ObsDetFbSecDrLft 1;
BA_ "GenSigSendType" SG_ 2154774528 Ltch3OpnDrSecDrLft 10;
BA_ "GenSigSendOnInit" SG_ 2154774528 Ltch3OpnDrSecDrLft 1;
BA_ "SignalType" SG_ 2154774528 Ltch3OpnDrSecDrLft "BLN";
BA_ "PacketOrder" SG_ 2154774528 Ltch3OpnDrSecDrLft 2;
BA_ "SignalLongName" SG_ 2154774528 Ltch3OpnDrSecDrLft "Secondary Door Left : Latch 3 OPEN Status";
BA_ "VNSigAllNodes" SG_ 2154774528 Ltch3OpnDrSecDrLft 1;
BA_ "GenSigSendType" SG_ 2154774528 Ltch1OpbstsSecDrLft 10;
BA_ "GenSigSendOnInit" SG_ 2154774528 Ltch1OpbstsSecDrLft 1;
BA_ "SignalType" SG_ 2154774528 Ltch1OpbstsSecDrLft "BLN";
BA_ "SignalLongName" SG_ 2154774528 Ltch1OpbstsSecDrLft "Secondary Door Left : Latch 1 OPEN Status";
BA_ "VNSigAllNodes" SG_ 2154774528 Ltch1OpbstsSecDrLft 1;
BA_ "GenSigSendType" SG_ 2154774528 HldOpnRlsActFbSecDrLft 10;
BA_ "GenSigSendOnInit" SG_ 2154774528 HldOpnRlsActFbSecDrLft 1;
BA_ "SignalType" SG_ 2154774528 HldOpnRlsActFbSecDrLft "BLN";
BA_ "PacketOrder" SG_ 2154774528 HldOpnRlsActFbSecDrLft 5;
BA_ "SignalLongName" SG_ 2154774528 HldOpnRlsActFbSecDrLft "Secondary Door Left : Hold Open Release Active Feedback";
BA_ "VNSigAllNodes" SG_ 2154774528 HldOpnRlsActFbSecDrLft 1;
BA_ "GenSigSendType" SG_ 2154774528 DrClsPsnLtchRatSecDrLft 10;
BA_ "GenSigSendOnInit" SG_ 2154774528 DrClsPsnLtchRatSecDrLft 1;
BA_ "SignalType" SG_ 2154774528 DrClsPsnLtchRatSecDrLft "BLN";
BA_ "PacketOrder" SG_ 2154774528 DrClsPsnLtchRatSecDrLft 3;
BA_ "SignalLongName" SG_ 2154774528 DrClsPsnLtchRatSecDrLft "Secondary Door Left : Door Closed : Position & Latch Rationality ";
BA_ "VNSigAllNodes" SG_ 2154774528 DrClsPsnLtchRatSecDrLft 1;
BA_ "GenSigSendType" SG_ 2154774528 CinActFbSecDrLft 10;
BA_ "GenSigSendOnInit" SG_ 2154774528 CinActFbSecDrLft 1;
BA_ "SignalType" SG_ 2154774528 CinActFbSecDrLft "BLN";
BA_ "PacketOrder" SG_ 2154774528 CinActFbSecDrLft 4;
BA_ "SignalLongName" SG_ 2154774528 CinActFbSecDrLft "Secondary Door Left : Cinching Active Feedback";
BA_ "VNSigAllNodes" SG_ 2154774528 CinActFbSecDrLft 1;
BA_ "GenSigSendType" SG_ 2154774528 AntiPi1DetFbSecDrLft 10;
BA_ "GenSigSendOnInit" SG_ 2154774528 AntiPi1DetFbSecDrLft 1;
BA_ "SignalType" SG_ 2154774528 AntiPi1DetFbSecDrLft "BLN";
BA_ "PacketOrder" SG_ 2154774528 AntiPi1DetFbSecDrLft 7;
BA_ "SignalLongName" SG_ 2154774528 AntiPi1DetFbSecDrLft "Secondary Door Left : Anti-Pinch 1 Detected Feedback";
BA_ "VNSigAllNodes" SG_ 2154774528 AntiPi1DetFbSecDrLft 1;
BA_ "GenSigSendType" SG_ 2154749952 PosSenFltRt 10;
BA_ "GenSigSendOnInit" SG_ 2154749952 PosSenFltRt 1;
BA_ "SignalType" SG_ 2154749952 PosSenFltRt "BLN";
BA_ "SignalLongName" SG_ 2154749952 PosSenFltRt "Position Sensor Fault detected Right";
BA_ "VNSigAllNodes" SG_ 2154749952 PosSenFltRt 1;
BA_ "GenSigSendType" SG_ 2154749952 LtchMtr3FltdetRt 10;
BA_ "GenSigSendOnInit" SG_ 2154749952 LtchMtr3FltdetRt 1;
BA_ "SignalType" SG_ 2154749952 LtchMtr3FltdetRt "BLN";
BA_ "SignalLongName" SG_ 2154749952 LtchMtr3FltdetRt "Latch Motor 3 Fault detected Right";
BA_ "VNSigAllNodes" SG_ 2154749952 LtchMtr3FltdetRt 1;
BA_ "GenSigSendType" SG_ 2154749952 LtchMtr2FltdetRt 10;
BA_ "GenSigSendOnInit" SG_ 2154749952 LtchMtr2FltdetRt 1;
BA_ "SignalType" SG_ 2154749952 LtchMtr2FltdetRt "BLN";
BA_ "SignalLongName" SG_ 2154749952 LtchMtr2FltdetRt "Latch Motor 2 Fault detected Right";
BA_ "VNSigAllNodes" SG_ 2154749952 LtchMtr2FltdetRt 1;
BA_ "GenSigSendType" SG_ 2154749952 LtchMtr1FltdetRt 10;
BA_ "GenSigSendOnInit" SG_ 2154749952 LtchMtr1FltdetRt 1;
BA_ "SignalType" SG_ 2154749952 LtchMtr1FltdetRt "BLN";
BA_ "SignalLongName" SG_ 2154749952 LtchMtr1FltdetRt "Latch Motor 1 Fault detected Right";
BA_ "VNSigAllNodes" SG_ 2154749952 LtchMtr1FltdetRt 1;
BA_ "GenSigSendType" SG_ 2154749952 IntopenswtchactRt 10;
BA_ "GenSigSendOnInit" SG_ 2154749952 IntopenswtchactRt 1;
BA_ "SignalType" SG_ 2154749952 IntopenswtchactRt "BLN";
BA_ "SignalLongName" SG_ 2154749952 IntopenswtchactRt "Interior Open Switch Active Right";
BA_ "VNSigAllNodes" SG_ 2154749952 IntopenswtchactRt 1;
BA_ "GenSigSendType" SG_ 2154749952 ExtswtchactRt 10;
BA_ "GenSigSendOnInit" SG_ 2154749952 ExtswtchactRt 1;
BA_ "SignalType" SG_ 2154749952 ExtswtchactRt "BLN";
BA_ "SignalLongName" SG_ 2154749952 ExtswtchactRt "Exterior Switch Active Right";
BA_ "VNSigAllNodes" SG_ 2154749952 ExtswtchactRt 1;
BA_ "GenSigSendType" SG_ 2154749952 ContrlUnavbLft_Rt 10;
BA_ "GenSigSendOnInit" SG_ 2154749952 ContrlUnavbLft_Rt 1;
BA_ "SignalType" SG_ 2154749952 ContrlUnavbLft_Rt "BLN";
BA_ "SignalLongName" SG_ 2154749952 ContrlUnavbLft_Rt "Controller Unavailable Right (Broken) (Internal Fault)";
BA_ "VNSigAllNodes" SG_ 2154749952 ContrlUnavbLft_Rt 1;
BA_ "GenSigSendType" SG_ 2154749952 AntiPn1FltDetRt 10;
BA_ "GenSigSendOnInit" SG_ 2154749952 AntiPn1FltDetRt 1;
BA_ "SignalType" SG_ 2154749952 AntiPn1FltDetRt "BLN";
BA_ "SignalLongName" SG_ 2154749952 AntiPn1FltDetRt "Anti Pinch 1 fault detected Right";
BA_ "VNSigAllNodes" SG_ 2154749952 AntiPn1FltDetRt 1;
BA_ "GenSigSendType" SG_ 2154749952 ActMtrFltDetRt 10;
BA_ "GenSigSendOnInit" SG_ 2154749952 ActMtrFltDetRt 1;
BA_ "SignalType" SG_ 2154749952 ActMtrFltDetRt "BLN";
BA_ "SignalLongName" SG_ 2154749952 ActMtrFltDetRt "Actuator Motor Fault Detected Right";
BA_ "VNSigAllNodes" SG_ 2154749952 ActMtrFltDetRt 1;
BA_ "GenSigSendType" SG_ 2154749952 PosFedbkSecDrRT 10;
BA_ "GenSigSendOnInit" SG_ 2154749952 PosFedbkSecDrRT 1;
BA_ "SignalType" SG_ 2154749952 PosFedbkSecDrRT "UNM";
BA_ "SignalLongName" SG_ 2154749952 PosFedbkSecDrRT "Secondary Door Right : Position Feedback ";
BA_ "VNSigAllNodes" SG_ 2154749952 PosFedbkSecDrRT 1;
BA_ "GenSigSendType" SG_ 2154749952 ObsDetFbSecDrRt 10;
BA_ "GenSigSendOnInit" SG_ 2154749952 ObsDetFbSecDrRt 1;
BA_ "PacketOrder" SG_ 2154749952 ObsDetFbSecDrRt 6;
BA_ "SignalType" SG_ 2154749952 ObsDetFbSecDrRt "BLN";
BA_ "SignalLongName" SG_ 2154749952 ObsDetFbSecDrRt "Secondary Door Right : Obstacle Detected _motor stall  Feedback";
BA_ "VNSigAllNodes" SG_ 2154749952 ObsDetFbSecDrRt 1;
BA_ "GenSigSendType" SG_ 2154749952 Ltch3OpnDrSecDrRt 10;
BA_ "GenSigSendOnInit" SG_ 2154749952 Ltch3OpnDrSecDrRt 1;
BA_ "PacketOrder" SG_ 2154749952 Ltch3OpnDrSecDrRt 2;
BA_ "SignalType" SG_ 2154749952 Ltch3OpnDrSecDrRt "BLN";
BA_ "SignalLongName" SG_ 2154749952 Ltch3OpnDrSecDrRt "Secondary Door Right : Latch 3 OPEN Status";
BA_ "VNSigAllNodes" SG_ 2154749952 Ltch3OpnDrSecDrRt 1;
BA_ "GenSigSendType" SG_ 2154749952 Ltch2OpnDrSecDrRt 10;
BA_ "GenSigSendOnInit" SG_ 2154749952 Ltch2OpnDrSecDrRt 1;
BA_ "PacketOrder" SG_ 2154749952 Ltch2OpnDrSecDrRt 1;
BA_ "SignalType" SG_ 2154749952 Ltch2OpnDrSecDrRt "BLN";
BA_ "SignalLongName" SG_ 2154749952 Ltch2OpnDrSecDrRt "Secondary Door Right : Latch 2 OPEN Status";
BA_ "VNSigAllNodes" SG_ 2154749952 Ltch2OpnDrSecDrRt 1;
BA_ "GenSigSendType" SG_ 2154749952 Ltch1OpbstsSecDrRt 10;
BA_ "GenSigSendOnInit" SG_ 2154749952 Ltch1OpbstsSecDrRt 1;
BA_ "SignalType" SG_ 2154749952 Ltch1OpbstsSecDrRt "BLN";
BA_ "SignalLongName" SG_ 2154749952 Ltch1OpbstsSecDrRt "Secondary Door Right : Latch 1 OPEN Status";
BA_ "VNSigAllNodes" SG_ 2154749952 Ltch1OpbstsSecDrRt 1;
BA_ "GenSigSendType" SG_ 2154749952 HldOpnRlsActFbSecDrRt 10;
BA_ "GenSigSendOnInit" SG_ 2154749952 HldOpnRlsActFbSecDrRt 1;
BA_ "PacketOrder" SG_ 2154749952 HldOpnRlsActFbSecDrRt 5;
BA_ "SignalType" SG_ 2154749952 HldOpnRlsActFbSecDrRt "BLN";
BA_ "SignalLongName" SG_ 2154749952 HldOpnRlsActFbSecDrRt "Secondary Door Right : Hold Open Release Active Feedback";
BA_ "VNSigAllNodes" SG_ 2154749952 HldOpnRlsActFbSecDrRt 1;
BA_ "GenSigSendType" SG_ 2154749952 DrMotCmpltOpnSecDrRt 10;
BA_ "GenSigSendOnInit" SG_ 2154749952 DrMotCmpltOpnSecDrRt 1;
BA_ "SignalType" SG_ 2154749952 DrMotCmpltOpnSecDrRt "BLN";
BA_ "PacketOrder" SG_ 2154749952 DrMotCmpltOpnSecDrRt 1;
BA_ "SignalLongName" SG_ 2154749952 DrMotCmpltOpnSecDrRt "Secondary Door Right : Door Motion Complete OPEN";
BA_ "VNSigAllNodes" SG_ 2154749952 DrMotCmpltOpnSecDrRt 1;
BA_ "GenSigSendType" SG_ 2154749952 DrMotCmpltClsSecDrRt 10;
BA_ "GenSigSendOnInit" SG_ 2154749952 DrMotCmpltClsSecDrRt 1;
BA_ "SignalType" SG_ 2154749952 DrMotCmpltClsSecDrRt "BLN";
BA_ "SignalLongName" SG_ 2154749952 DrMotCmpltClsSecDrRt "Secondary Door Right : Door Motion Complete CLOSE";
BA_ "VNSigAllNodes" SG_ 2154749952 DrMotCmpltClsSecDrRt 1;
BA_ "GenSigSendType" SG_ 2154749952 DrInMotSecRt 10;
BA_ "GenSigSendOnInit" SG_ 2154749952 DrInMotSecRt 1;
BA_ "SignalType" SG_ 2154749952 DrInMotSecRt "BLN";
BA_ "SignalLongName" SG_ 2154749952 DrInMotSecRt "Secondary Door Right : Door In Motion";
BA_ "VNSigAllNodes" SG_ 2154749952 DrInMotSecRt 1;
BA_ "GenSigSendType" SG_ 2154749952 DrClsPsnLtchRatSecDrRt 10;
BA_ "GenSigSendOnInit" SG_ 2154749952 DrClsPsnLtchRatSecDrRt 1;
BA_ "PacketOrder" SG_ 2154749952 DrClsPsnLtchRatSecDrRt 3;
BA_ "SignalType" SG_ 2154749952 DrClsPsnLtchRatSecDrRt "BLN";
BA_ "SignalLongName" SG_ 2154749952 DrClsPsnLtchRatSecDrRt "Secondary Door Right : Door Closed : Position & Latch Rationality ";
BA_ "VNSigAllNodes" SG_ 2154749952 DrClsPsnLtchRatSecDrRt 1;
BA_ "GenSigSendType" SG_ 2154749952 CinActFbSecDrRt 10;
BA_ "GenSigSendOnInit" SG_ 2154749952 CinActFbSecDrRt 1;
BA_ "PacketOrder" SG_ 2154749952 CinActFbSecDrRt 4;
BA_ "SignalType" SG_ 2154749952 CinActFbSecDrRt "BLN";
BA_ "SignalLongName" SG_ 2154749952 CinActFbSecDrRt "Secondary Door Right : Cinching Active Feedback";
BA_ "VNSigAllNodes" SG_ 2154749952 CinActFbSecDrRt 1;
BA_ "GenSigSendType" SG_ 2154749952 AntiPi2DetFbSecDrRt 10;
BA_ "GenSigSendOnInit" SG_ 2154749952 AntiPi2DetFbSecDrRt 1;
BA_ "PacketOrder" SG_ 2154749952 AntiPi2DetFbSecDrRt 8;
BA_ "SignalType" SG_ 2154749952 AntiPi2DetFbSecDrRt "BLN";
BA_ "SignalLongName" SG_ 2154749952 AntiPi2DetFbSecDrRt "Secondary Door Right : Anti-Pinch 2 Detected Feedback";
BA_ "VNSigAllNodes" SG_ 2154749952 AntiPi2DetFbSecDrRt 1;
BA_ "GenSigSendType" SG_ 2154749952 AntiPi1DetFbSecDrRt 10;
BA_ "GenSigSendOnInit" SG_ 2154749952 AntiPi1DetFbSecDrRt 1;
BA_ "PacketOrder" SG_ 2154749952 AntiPi1DetFbSecDrRt 7;
BA_ "SignalType" SG_ 2154749952 AntiPi1DetFbSecDrRt "BLN";
BA_ "SignalLongName" SG_ 2154749952 AntiPi1DetFbSecDrRt "Secondary Door Right : Anti-Pinch 1 Detected Feedback";
BA_ "VNSigAllNodes" SG_ 2154749952 AntiPi1DetFbSecDrRt 1;
BA_ "GenSigSendType" SG_ 2154749952 IntclseswtchactRt 10;
BA_ "GenSigSendOnInit" SG_ 2154749952 IntclseswtchactRt 1;
BA_ "SignalType" SG_ 2154749952 IntclseswtchactRt "BLN";
BA_ "SignalLongName" SG_ 2154749952 IntclseswtchactRt "Interior Close Switch Active Right";
BA_ "VNSigAllNodes" SG_ 2154749952 IntclseswtchactRt 1;
BA_ "GenSigSendType" SG_ 2154749952 AntiPn2FltdetRt 10;
BA_ "GenSigSendOnInit" SG_ 2154749952 AntiPn2FltdetRt 1;
BA_ "SignalType" SG_ 2154749952 AntiPn2FltdetRt "BLN";
BA_ "SignalLongName" SG_ 2154749952 AntiPn2FltdetRt "Anti Pinch 2 Fault Detected Right";
BA_ "VNSigAllNodes" SG_ 2154749952 AntiPn2FltdetRt 1;
BA_ "SignalType" SG_ 2153996288 VehIncPitch "SNM";
BA_ "SignalLongName" SG_ 2153996288 VehIncPitch "Vehicle Inclination Pitch";
BA_ "VNSigAllNodes" SG_ 2153996288 VehIncPitch 1;
BA_ "SignalType" SG_ 2153996288 VehRoll "SNM";
BA_ "SignalLongName" SG_ 2153996288 VehRoll "Vehicle Roll";
BA_ "VNSigAllNodes" SG_ 2153996288 VehRoll 1;
BA_ "GenSigSendType" SG_ 2154741760 Alw_Cmnd_SecIndRtDrHldopn 10;
BA_ "GenSigSendOnInit" SG_ 2154741760 Alw_Cmnd_SecIndRtDrHldopn 1;
BA_ "SignalType" SG_ 2154741760 Alw_Cmnd_SecIndRtDrHldopn "ENM";
BA_ "SignalLongName" SG_ 2154741760 Alw_Cmnd_SecIndRtDrHldopn "Allow Secondary Right Door Hold Open ";
BA_ "VNSigAllNodes" SG_ 2154741760 Alw_Cmnd_SecIndRtDrHldopn 1;
BA_ "GenSigSendType" SG_ 2154741760 SAM_secRtDr_Alw 10;
BA_ "GenSigSendOnInit" SG_ 2154741760 SAM_secRtDr_Alw 1;
BA_ "SignalType" SG_ 2154741760 SAM_secRtDr_Alw "ENM";
BA_ "SignalLongName" SG_ 2154741760 SAM_secRtDr_Alw "SAM Secondary Right Door Allow";
BA_ "GenSigStartValue" SG_ 2154741760 SAM_secRtDr_Alw 7;
BA_ "VNSigAllNodes" SG_ 2154741760 SAM_secRtDr_Alw 1;
BA_ "GenSigSendType" SG_ 2154741760 Cmnd_SecIndRtDrHldopn 10;
BA_ "GenSigSendOnInit" SG_ 2154741760 Cmnd_SecIndRtDrHldopn 1;
BA_ "SignalType" SG_ 2154741760 Cmnd_SecIndRtDrHldopn "ENM";
BA_ "SignalLongName" SG_ 2154741760 Cmnd_SecIndRtDrHldopn "Command Secondary Right Door Hold Open";
BA_ "VNSigAllNodes" SG_ 2154741760 Cmnd_SecIndRtDrHldopn 1;
BA_ "GenSigSendType" SG_ 2154741760 SAM_SecIndRtDrCmnd 10;
BA_ "GenSigSendOnInit" SG_ 2154741760 SAM_SecIndRtDrCmnd 1;
BA_ "SignalType" SG_ 2154741760 SAM_SecIndRtDrCmnd "ENM";
BA_ "SignalLongName" SG_ 2154741760 SAM_SecIndRtDrCmnd "SAM Secondary Right Door Command";
BA_ "VNSigAllNodes" SG_ 2154741760 SAM_SecIndRtDrCmnd 1;
BA_ "SignalType" SG_ 2154766336 RedRFPwrDrCmnd "ENM";
BA_ "SignalLongName" SG_ 2154766336 RedRFPwrDrCmnd "Redundant Right Front Power Door Command";
BA_ "VNSigAllNodes" SG_ 2154766336 RedRFPwrDrCmnd 1;
BA_ "SignalType" SG_ 2154766336 RedRFPwrDrAlw "ENM";
BA_ "SignalLongName" SG_ 2154766336 RedRFPwrDrAlw "Redundant Right Front Power Door Allow";
BA_ "GenSigStartValue" SG_ 2154766336 RedRFPwrDrAlw 3;
BA_ "VNSigAllNodes" SG_ 2154766336 RedRFPwrDrAlw 1;
BA_ "SignalType" SG_ 2154766336 RedLFDPwrDrCmnd "ENM";
BA_ "SignalLongName" SG_ 2154766336 RedLFDPwrDrCmnd "Redundant Left Front Power Door Command";
BA_ "VNSigAllNodes" SG_ 2154766336 RedLFDPwrDrCmnd 1;
BA_ "SignalType" SG_ 2154766336 RedLFPwrDrAlw "ENM";
BA_ "SignalLongName" SG_ 2154766336 RedLFPwrDrAlw "Redundant Left Front Power Door Allow";
BA_ "GenSigStartValue" SG_ 2154766336 RedLFPwrDrAlw 3;
BA_ "VNSigAllNodes" SG_ 2154766336 RedLFPwrDrAlw 1;
BA_ "SignalType" SG_ 2154766336 RedLRPwrDrAlw "ENM";
BA_ "SignalLongName" SG_ 2154766336 RedLRPwrDrAlw "Redundant Left Rear Power Door Allow";
BA_ "GenSigStartValue" SG_ 2154766336 RedLRPwrDrAlw 3;
BA_ "VNSigAllNodes" SG_ 2154766336 RedLRPwrDrAlw 1;
BA_ "SignalType" SG_ 2154766336 RedRRPwrDrAlw "ENM";
BA_ "SignalLongName" SG_ 2154766336 RedRRPwrDrAlw "Redundant Right Rear Power Door Allow";
BA_ "GenSigStartValue" SG_ 2154766336 RedRRPwrDrAlw 3;
BA_ "VNSigAllNodes" SG_ 2154766336 RedRRPwrDrAlw 1;
BA_ "SignalType" SG_ 2154766336 RedRRPwrDrCmnd "ENM";
BA_ "SignalLongName" SG_ 2154766336 RedRRPwrDrCmnd "Redundant Right Rear Power Door Command";
BA_ "VNSigAllNodes" SG_ 2154766336 RedRRPwrDrCmnd 1;
BA_ "SignalType" SG_ 2154766336 RedLRDPwrDrCmnd "ENM";
BA_ "SignalLongName" SG_ 2154766336 RedLRDPwrDrCmnd "Redundant Left Rear Power Door Command";
BA_ "VNSigAllNodes" SG_ 2154766336 RedLRDPwrDrCmnd 1;
BA_ "SignalType" SG_ 584 DgnInf "UNM";
BA_ "SignalLongName" SG_ 584 DgnInf "Diagnostic Information";
BA_ "VNSigDiagnostic" SG_ 584 DgnInf 1;
BA_ "VNSigAllNodes" SG_ 584 DgnInf 1;
BA_ "SignalType" SG_ 1608 DgnInf "UNM";
BA_ "SignalLongName" SG_ 1608 DgnInf "Diagnostic Information";
BA_ "VNSigDiagnostic" SG_ 1608 DgnInf 1;
BA_ "VNSigAllNodes" SG_ 1608 DgnInf 1;
BA_ "VNSigPrimaryTriggering" SG_ 1576 VectraSpcNWMgtD 1;
BA_ "VNSigRemoteDiagnostics" SG_ 1576 VectraSpcNWMgtD 1;
BA_ "VNSigInfotainment" SG_ 1576 VectraSpcNWMgtD 1;
BA_ "VNSigParkedVehicle" SG_ 1576 VectraSpcNWMgtD 1;
BA_ "VNSigIntermediate" SG_ 1576 VectraSpcNWMgtD 1;
BA_ "VNSigUnused_4" SG_ 1576 VectraSpcNWMgtD 1;
BA_ "SignalType" SG_ 1576 VectraSpcNWMgtD "UNM";
BA_ "SignalLongName" SG_ 1576 VectraSpcNWMgtD "Vectra Specific Network Management Data";
BA_ "VNSigDiagnostic" SG_ 1576 VectraSpcNWMgtD 1;
BA_ "VNSigAllNodes" SG_ 1576 VectraSpcNWMgtD 1;
BA_ "SignalType" SG_ 1352 DgnInf_LS548 "UNM";
BA_ "SignalLongName" SG_ 1352 DgnInf_LS548 "Diagnostic Information LS548";
BA_ "VNSigDiagnostic" SG_ 1352 DgnInf_LS548 1;
BA_ "VNSigAllNodes" SG_ 1352 DgnInf_LS548 1;
BA_ "GenSigSendOnInit" SG_ 2163015680 TrcNumByt9_16 2;
BA_ "VNSigInfotainment" SG_ 2163015680 TrcNumByt9_16 1;
BA_ "SignalType" SG_ 2163015680 TrcNumByt9_16 "ASC";
BA_ "SignalLongName" SG_ 2163015680 TrcNumByt9_16 "Traceability Number Bytes 9-16";
BA_ "VNSigAllNodes" SG_ 2163015680 TrcNumByt9_16 1;
BA_ "GenSigSendType" SG_ 2154872832 MCTWiFiSt 10;
BA_ "SignalType" SG_ 2154872832 MCTWiFiSt "ENM";
BA_ "SignalLongName" SG_ 2154872832 MCTWiFiSt "Multiple Carrier Telematics Wifi Status";
BA_ "VNSigAllNodes" SG_ 2154872832 MCTWiFiSt 1;
BA_ "GenSigSendType" SG_ 2154872832 MCTStofHlthChcksm 12;
BA_ "SignalType" SG_ 2154872832 MCTStofHlthChcksm "UNM";
BA_ "SignalLongName" SG_ 2154872832 MCTStofHlthChcksm "Multiple Carrier Telematics State of Health Checksum";
BA_ "VNSigAllNodes" SG_ 2154872832 MCTStofHlthChcksm 1;
BA_ "GenSigSendType" SG_ 2154872832 MCTStofHlthARC 12;
BA_ "SignalType" SG_ 2154872832 MCTStofHlthARC "UNM";
BA_ "SignalLongName" SG_ 2154872832 MCTStofHlthARC "Multiple Carrier Telematics State of Health Alive Rolling Count";
BA_ "VNSigAllNodes" SG_ 2154872832 MCTStofHlthARC 1;
BA_ "GenSigSendType" SG_ 2154872832 MCTPrEthSt 10;
BA_ "SignalType" SG_ 2154872832 MCTPrEthSt "ENM";
BA_ "SignalLongName" SG_ 2154872832 MCTPrEthSt "Multiple Carrier Telematics Private Ethernet Status";
BA_ "VNSigAllNodes" SG_ 2154872832 MCTPrEthSt 1;
BA_ "GenSigSendType" SG_ 2154872832 MCTOfbSvcSt 10;
BA_ "SignalType" SG_ 2154872832 MCTOfbSvcSt "ENM";
BA_ "SignalLongName" SG_ 2154872832 MCTOfbSvcSt "Multiple Carrier Telematics Offboard Service Status";
BA_ "VNSigAllNodes" SG_ 2154872832 MCTOfbSvcSt 1;
BA_ "GenSigSendType" SG_ 2154872832 MCTNmbrTbltsComm 12;
BA_ "SignalType" SG_ 2154872832 MCTNmbrTbltsComm "UNM";
BA_ "SignalLongName" SG_ 2154872832 MCTNmbrTbltsComm "Multiple Carrier Telematics Number of Tablets Communicating";
BA_ "VNSigAllNodes" SG_ 2154872832 MCTNmbrTbltsComm 1;
BA_ "GenSigSendType" SG_ 2154872832 MCTNmbrPwrSplsOprtg 12;
BA_ "SignalType" SG_ 2154872832 MCTNmbrPwrSplsOprtg "UNM";
BA_ "SignalLongName" SG_ 2154872832 MCTNmbrPwrSplsOprtg "Multiple Carrier Telematics Number of Power Supplies Operating";
BA_ "VNSigAllNodes" SG_ 2154872832 MCTNmbrPwrSplsOprtg 1;
BA_ "GenSigSendType" SG_ 2154872832 MCTNmbrOnsBtnSetsOprtg 12;
BA_ "SignalType" SG_ 2154872832 MCTNmbrOnsBtnSetsOprtg "UNM";
BA_ "SignalLongName" SG_ 2154872832 MCTNmbrOnsBtnSetsOprtg "Multiple Carrier Telematics Number of OnStar Button Sets Operating";
BA_ "VNSigAllNodes" SG_ 2154872832 MCTNmbrOnsBtnSetsOprtg 1;
BA_ "GenSigSendType" SG_ 2154872832 MCTNmbrNADsOprtg 12;
BA_ "SignalType" SG_ 2154872832 MCTNmbrNADsOprtg "UNM";
BA_ "SignalLongName" SG_ 2154872832 MCTNmbrNADsOprtg "Multiple Carrier Telematics Number of Network Access Devices Operating";
BA_ "VNSigAllNodes" SG_ 2154872832 MCTNmbrNADsOprtg 1;
BA_ "GenSigSendType" SG_ 2154872832 MCTNmbrMicsOprtg 12;
BA_ "SignalType" SG_ 2154872832 MCTNmbrMicsOprtg "UNM";
BA_ "SignalLongName" SG_ 2154872832 MCTNmbrMicsOprtg "Multiple Carrier Telematics Number of Microphones Operating";
BA_ "VNSigAllNodes" SG_ 2154872832 MCTNmbrMicsOprtg 1;
BA_ "GenSigSendType" SG_ 2154872832 MCTNmbrEthPrtsOprtg 12;
BA_ "SignalType" SG_ 2154872832 MCTNmbrEthPrtsOprtg "UNM";
BA_ "SignalLongName" SG_ 2154872832 MCTNmbrEthPrtsOprtg "Multiple Carrier Telematics Number of Ethernet Ports Operating";
BA_ "VNSigAllNodes" SG_ 2154872832 MCTNmbrEthPrtsOprtg 1;
BA_ "GenSigSendType" SG_ 2154872832 MCTNmbrCamsOprtg 12;
BA_ "SignalType" SG_ 2154872832 MCTNmbrCamsOprtg "UNM";
BA_ "SignalLongName" SG_ 2154872832 MCTNmbrCamsOprtg "Multiple Carrier Telematics Number of Cameras Operating";
BA_ "VNSigAllNodes" SG_ 2154872832 MCTNmbrCamsOprtg 1;
BA_ "GenSigSendType" SG_ 2154872832 MCTNmbrAntOprtg 12;
BA_ "SignalType" SG_ 2154872832 MCTNmbrAntOprtg "UNM";
BA_ "SignalLongName" SG_ 2154872832 MCTNmbrAntOprtg "Multiple Carrier Telematics Number of Antennas Operating";
BA_ "VNSigAllNodes" SG_ 2154872832 MCTNmbrAntOprtg 1;
BA_ "GenSigSendType" SG_ 2154872832 MCTNmbrVPNsOprtg 12;
BA_ "SignalType" SG_ 2154872832 MCTNmbrVPNsOprtg "UNM";
BA_ "SignalLongName" SG_ 2154872832 MCTNmbrVPNsOprtg "Multiple Carrier Telematics Number of  Virtual Private Networks Operating";
BA_ "VNSigAllNodes" SG_ 2154872832 MCTNmbrVPNsOprtg 1;
BA_ "GenSigSendType" SG_ 2154872832 MCTLSLANSt 10;
BA_ "SignalType" SG_ 2154872832 MCTLSLANSt "ENM";
BA_ "SignalLongName" SG_ 2154872832 MCTLSLANSt "Multiple Carrier Telematics LSGMLAN Bus Status";
BA_ "VNSigAllNodes" SG_ 2154872832 MCTLSLANSt 1;
BA_ "GenSigSendType" SG_ 2154872832 MCTIPCSt 12;
BA_ "SignalType" SG_ 2154872832 MCTIPCSt "ENM";
BA_ "SignalLongName" SG_ 2154872832 MCTIPCSt "Multiple Carrier Telematics IPC Status";
BA_ "VNSigAllNodes" SG_ 2154872832 MCTIPCSt 1;
BA_ "GenSigSendType" SG_ 2154872832 MCTHSLANSt 10;
BA_ "SignalType" SG_ 2154872832 MCTHSLANSt "ENM";
BA_ "SignalLongName" SG_ 2154872832 MCTHSLANSt "Multiple Carrier Telematics HSGMLAN Bus Status";
BA_ "VNSigAllNodes" SG_ 2154872832 MCTHSLANSt 1;
BA_ "GenSigSendType" SG_ 2154872832 MCTHwSt 12;
BA_ "SignalType" SG_ 2154872832 MCTHwSt "ENM";
BA_ "SignalLongName" SG_ 2154872832 MCTHwSt "Multiple Carrier Telematics Hardware Status";
BA_ "VNSigAllNodes" SG_ 2154872832 MCTHwSt 1;
BA_ "GenSigSendType" SG_ 2154872832 MCTGPSSt 10;
BA_ "SignalType" SG_ 2154872832 MCTGPSSt "ENM";
BA_ "SignalLongName" SG_ 2154872832 MCTGPSSt "Multiple Carrier Telematics GPS Status";
BA_ "VNSigAllNodes" SG_ 2154872832 MCTGPSSt 1;
BA_ "GenSigSendType" SG_ 2154872832 MCTCGMSt 10;
BA_ "SignalType" SG_ 2154872832 MCTCGMSt "ENM";
BA_ "SignalLongName" SG_ 2154872832 MCTCGMSt "Multiple Carrier Telematics CGM Status";
BA_ "VNSigAllNodes" SG_ 2154872832 MCTCGMSt 1;
BA_ "GenSigSendType" SG_ 2154872832 MCTBCMSt 12;
BA_ "SignalType" SG_ 2154872832 MCTBCMSt "ENM";
BA_ "SignalLongName" SG_ 2154872832 MCTBCMSt "Multiple Carrier Telematics BCM Status";
BA_ "VNSigAllNodes" SG_ 2154872832 MCTBCMSt 1;
BA_ "GenSigSendType" SG_ 2154872832 MCTAudSt 10;
BA_ "SignalType" SG_ 2154872832 MCTAudSt "ENM";
BA_ "SignalLongName" SG_ 2154872832 MCTAudSt "Multiple Carrier Telematics Audio Status";
BA_ "VNSigAllNodes" SG_ 2154872832 MCTAudSt 1;
BA_ "GenSigSendType" SG_ 2154872832 MCTADSCCommSt 10;
BA_ "SignalType" SG_ 2154872832 MCTADSCCommSt "ENM";
BA_ "SignalLongName" SG_ 2154872832 MCTADSCCommSt "Multiple Carrier Telematics ADSC Communication Status";
BA_ "VNSigAllNodes" SG_ 2154872832 MCTADSCCommSt 1;
BA_ "GenSigSendType" SG_ 2154872832 MCTADIMCommSt 10;
BA_ "SignalType" SG_ 2154872832 MCTADIMCommSt "ENM";
BA_ "SignalLongName" SG_ 2154872832 MCTADIMCommSt "Multiple Carrier Telematics ADIM Communication Status";
BA_ "VNSigAllNodes" SG_ 2154872832 MCTADIMCommSt 1;
BA_ "SignalType" SG_ 1630 DgnInf "UNM";
BA_ "SignalLongName" SG_ 1630 DgnInf "Diagnostic Information";
BA_ "VNSigDiagnostic" SG_ 1630 DgnInf 1;
BA_ "VNSigAllNodes" SG_ 1630 DgnInf 1;
BA_ "SignalType" SG_ 1374 DgnInf_LS55E "UNM";
BA_ "SignalLongName" SG_ 1374 DgnInf_LS55E "Diagnostic Information LS55E";
BA_ "VNSigDiagnostic" SG_ 1374 DgnInf_LS55E 1;
BA_ "VNSigAllNodes" SG_ 1374 DgnInf_LS55E 1;
BA_ "SignalType" SG_ 606 DgnInf "UNM";
BA_ "SignalLongName" SG_ 606 DgnInf "Diagnostic Information";
BA_ "VNSigDiagnostic" SG_ 606 DgnInf 1;
BA_ "VNSigAllNodes" SG_ 606 DgnInf 1;
BA_ "SignalType" SG_ 1603 DgnInf "UNM";
BA_ "SignalLongName" SG_ 1603 DgnInf "Diagnostic Information";
BA_ "VNSigDiagnostic" SG_ 1603 DgnInf 1;
BA_ "VNSigAllNodes" SG_ 1603 DgnInf 1;
BA_ "SignalType" SG_ 2158952448 ODDMR_ReqType "ENM";
BA_ "PacketOrder" SG_ 2158952448 ODDMR_ReqType 1;
BA_ "SignalLongName" SG_ 2158952448 ODDMR_ReqType "Open Display Interface Dynamic Data Multi Request Rear Seat Display : Request Type";
BA_ "VNSigAllNodes" SG_ 2158952448 ODDMR_ReqType 1;
BA_ "SignalType" SG_ 2158952448 ODDMR_FUCID "UNM";
BA_ "PacketOrder" SG_ 2158952448 ODDMR_FUCID 6;
BA_ "SignalLongName" SG_ 2158952448 ODDMR_FUCID "Open Display Interface Dynamic Data Multi Request Rear Seat Display : Functional Unit Class ID";
BA_ "VNSigAllNodes" SG_ 2158952448 ODDMR_FUCID 1;
BA_ "SignalType" SG_ 2158952448 ODDMR_DispMID "ENM";
BA_ "PacketOrder" SG_ 2158952448 ODDMR_DispMID 7;
BA_ "SignalLongName" SG_ 2158952448 ODDMR_DispMID "Open Display Interface Dynamic Data Multi Request Rear Seat Display : Display Mask Id";
BA_ "VNSigAllNodes" SG_ 2158952448 ODDMR_DispMID 1;
BA_ "SignalType" SG_ 2158952448 ODDMR_DataID2Vld "BLN";
BA_ "PacketOrder" SG_ 2158952448 ODDMR_DataID2Vld 5;
BA_ "SignalLongName" SG_ 2158952448 ODDMR_DataID2Vld "Open Display Interface Dynamic Data Multi Request Rear Seat Display : Data ID Two Valid";
BA_ "VNSigAllNodes" SG_ 2158952448 ODDMR_DataID2Vld 1;
BA_ "SignalType" SG_ 2158952448 ODDMR_DataID2 "UNM";
BA_ "PacketOrder" SG_ 2158952448 ODDMR_DataID2 9;
BA_ "SignalLongName" SG_ 2158952448 ODDMR_DataID2 "Open Display Interface Dynamic Data Multi Request Rear Seat Display : Data ID Two";
BA_ "VNSigAllNodes" SG_ 2158952448 ODDMR_DataID2 1;
BA_ "SignalType" SG_ 2158952448 ODDMR_DataID3Vld "BLN";
BA_ "PacketOrder" SG_ 2158952448 ODDMR_DataID3Vld 4;
BA_ "SignalLongName" SG_ 2158952448 ODDMR_DataID3Vld "Open Display Interface Dynamic Data Multi Request Rear Seat Display : Data ID Three Valid";
BA_ "VNSigAllNodes" SG_ 2158952448 ODDMR_DataID3Vld 1;
BA_ "SignalType" SG_ 2158952448 ODDMR_DataID3 "UNM";
BA_ "PacketOrder" SG_ 2158952448 ODDMR_DataID3 10;
BA_ "SignalLongName" SG_ 2158952448 ODDMR_DataID3 "Open Display Interface Dynamic Data Multi Request Rear Seat Display : Data ID Three";
BA_ "VNSigAllNodes" SG_ 2158952448 ODDMR_DataID3 1;
BA_ "SignalType" SG_ 2158952448 ODDMR_DataID1 "UNM";
BA_ "PacketOrder" SG_ 2158952448 ODDMR_DataID1 8;
BA_ "SignalLongName" SG_ 2158952448 ODDMR_DataID1 "Open Display Interface Dynamic Data Multi Request Rear Seat Display : Data ID One";
BA_ "VNSigAllNodes" SG_ 2158952448 ODDMR_DataID1 1;
BA_ "SignalType" SG_ 2158952448 ODDMR_DataID4Vld "BLN";
BA_ "PacketOrder" SG_ 2158952448 ODDMR_DataID4Vld 3;
BA_ "SignalLongName" SG_ 2158952448 ODDMR_DataID4Vld "Open Display Interface Dynamic Data Multi Request Rear Seat Display : Data ID Four Valid";
BA_ "VNSigAllNodes" SG_ 2158952448 ODDMR_DataID4Vld 1;
BA_ "SignalType" SG_ 2158952448 ODDMR_DataID4 "UNM";
BA_ "PacketOrder" SG_ 2158952448 ODDMR_DataID4 11;
BA_ "SignalLongName" SG_ 2158952448 ODDMR_DataID4 "Open Display Interface Dynamic Data Multi Request Rear Seat Display : Data ID Four";
BA_ "VNSigAllNodes" SG_ 2158952448 ODDMR_DataID4 1;
BA_ "SignalType" SG_ 2158952448 ODDMR_DataID5Vld "BLN";
BA_ "PacketOrder" SG_ 2158952448 ODDMR_DataID5Vld 2;
BA_ "SignalLongName" SG_ 2158952448 ODDMR_DataID5Vld "Open Display Interface Dynamic Data Multi Request Rear Seat Display : Data ID Five Valid";
BA_ "VNSigAllNodes" SG_ 2158952448 ODDMR_DataID5Vld 1;
BA_ "SignalType" SG_ 2158952448 ODDMR_DataID5 "UNM";
BA_ "PacketOrder" SG_ 2158952448 ODDMR_DataID5 12;
BA_ "SignalLongName" SG_ 2158952448 ODDMR_DataID5 "Open Display Interface Dynamic Data Multi Request Rear Seat Display : Data ID Five";
BA_ "VNSigAllNodes" SG_ 2158952448 ODDMR_DataID5 1;
BA_REL_ "GenSigSuprvResp" BU_SG_REL_ SAM_PR_LS SG_ 2154831872 SrcodOpnCmdPrRight_Bkp 1;
BA_REL_ "GenSigSuprvResp" BU_SG_REL_ BCM_LS SG_ 2154831872 SrcodOpnCmdPrRight_Bkp 1;
BA_REL_ "GenSigSuprvResp" BU_SG_REL_ SAM_PR_LS SG_ 2154831872 SrcodClsCmdPrRightBkp 1;
BA_REL_ "GenSigSuprvResp" BU_SG_REL_ BCM_LS SG_ 2154831872 SrcodClsCmdPrRightBkp 1;
BA_REL_ "GenSigSuprvResp" BU_SG_REL_ SAM_PR_LS SG_ 2154831872 SideDrMtnNotAlwIntPreWrnPrRt_Bkp 1;
BA_REL_ "GenSigSuprvResp" BU_SG_REL_ BCM_LS SG_ 2154831872 SideDrMtnNotAlwIntPreWrnPrRt_Bkp 1;
BA_REL_ "GenSigSuprvResp" BU_SG_REL_ SAM_PR_LS SG_ 2154831872 SideDrMtnNtAlwExtPreWrnPrRt_Bkp 1;
BA_REL_ "GenSigSuprvResp" BU_SG_REL_ BCM_LS SG_ 2154831872 SideDrMtnNtAlwExtPreWrnPrRt_Bkp 1;
BA_REL_ "GenSigSuprvResp" BU_SG_REL_ SAM_PR_LS SG_ 2154831872 SAM_PriIndRtDrCmnd_Bkp 1;
BA_REL_ "GenSigSuprvResp" BU_SG_REL_ BCM_LS SG_ 2154831872 SAM_PriIndRtDrCmnd_Bkp 1;
BA_REL_ "GenSigSuprvResp" BU_SG_REL_ SAM_PR_LS SG_ 2154831872 SAMPriRtDrAlw_Bkp 1;
BA_REL_ "GenSigSuprvResp" BU_SG_REL_ BCM_LS SG_ 2154831872 SAMPriRtDrAlw_Bkp 1;
BA_REL_ "GenSigSuprvResp" BU_SG_REL_ BCM_LS SG_ 2154815488 SrcodOpnCmdPrLeft 1;
BA_REL_ "GenSigSuprvResp" BU_SG_REL_ SAM_PL_LS SG_ 2154815488 SrcodOpnCmdPrLeft 1;
BA_REL_ "GenSigSuprvResp" BU_SG_REL_ BCM_LS SG_ 2154815488 SrcodClsCmdPrLeft 1;
BA_REL_ "GenSigSuprvResp" BU_SG_REL_ SAM_PL_LS SG_ 2154815488 SrcodClsCmdPrLeft 1;
BA_REL_ "GenSigSuprvResp" BU_SG_REL_ BCM_LS SG_ 2154815488 SideDrMtnNotAlwIntPreWarnPrLeft 1;
BA_REL_ "GenSigSuprvResp" BU_SG_REL_ SAM_PL_LS SG_ 2154815488 SideDrMtnNotAlwIntPreWarnPrLeft 1;
BA_REL_ "GenSigSuprvResp" BU_SG_REL_ BCM_LS SG_ 2154815488 SideDrMtnNotAlwExtPreWarnPrLeft 1;
BA_REL_ "GenSigSuprvResp" BU_SG_REL_ SAM_PL_LS SG_ 2154815488 SideDrMtnNotAlwExtPreWarnPrLeft 1;
BA_REL_ "GenSigSuprvResp" BU_SG_REL_ BCM_LS SG_ 2154815488 SAM_PriIndRtDrCmnd 1;
BA_REL_ "GenSigSuprvResp" BU_SG_REL_ SAM_PL_LS SG_ 2154815488 SAM_PriIndRtDrCmnd 1;
BA_REL_ "GenSigSuprvResp" BU_SG_REL_ BCM_LS SG_ 2154815488 SAMPriRtDrAlw 1;
BA_REL_ "GenSigSuprvResp" BU_SG_REL_ SAM_PL_LS SG_ 2154815488 SAMPriRtDrAlw 1;
BA_REL_ "GenSigSuprvResp" BU_SG_REL_ ADIMa_LS SG_ 2154889216 AntiPi2DetFbPriDrLeft 1;
BA_REL_ "GenSigSuprvResp" BU_SG_REL_ ADIMb_LS SG_ 2154889216 AntiPi2DetFbPriDrLeft 1;
BA_REL_ "GenSigSuprvResp" BU_SG_REL_ BCM_LS SG_ 2154889216 AntiPi2DetFbPriDrLeft 1;
BA_REL_ "GenSigSuprvResp" BU_SG_REL_ ADIMa_LS SG_ 2154889216 PosFedbkPriDrLeft 1;
BA_REL_ "GenSigSuprvResp" BU_SG_REL_ ADIMb_LS SG_ 2154889216 PosFedbkPriDrLeft 1;
BA_REL_ "GenSigSuprvResp" BU_SG_REL_ BCM_LS SG_ 2154889216 PosFedbkPriDrLeft 1;
BA_REL_ "GenSigSuprvResp" BU_SG_REL_ ADIMa_LS SG_ 2154889216 ObsDetFbPriDrLeft 1;
BA_REL_ "GenSigSuprvResp" BU_SG_REL_ ADIMb_LS SG_ 2154889216 ObsDetFbPriDrLeft 1;
BA_REL_ "GenSigSuprvResp" BU_SG_REL_ BCM_LS SG_ 2154889216 ObsDetFbPriDrLeft 1;
BA_REL_ "GenSigSuprvResp" BU_SG_REL_ ADIMa_LS SG_ 2154889216 Ltch3OPnDrPriDrLeft 1;
BA_REL_ "GenSigSuprvResp" BU_SG_REL_ ADIMb_LS SG_ 2154889216 Ltch3OPnDrPriDrLeft 1;
BA_REL_ "GenSigSuprvResp" BU_SG_REL_ BCM_LS SG_ 2154889216 Ltch3OPnDrPriDrLeft 1;
BA_REL_ "GenSigSuprvResp" BU_SG_REL_ ADIMa_LS SG_ 2154889216 Ltch2OpnDrPriDrLeft 1;
BA_REL_ "GenSigSuprvResp" BU_SG_REL_ ADIMb_LS SG_ 2154889216 Ltch2OpnDrPriDrLeft 1;
BA_REL_ "GenSigSuprvResp" BU_SG_REL_ BCM_LS SG_ 2154889216 Ltch2OpnDrPriDrLeft 1;
BA_REL_ "GenSigSuprvResp" BU_SG_REL_ ADIMa_LS SG_ 2154889216 Ltch1OpbstsPriDrLeft 1;
BA_REL_ "GenSigSuprvResp" BU_SG_REL_ ADIMb_LS SG_ 2154889216 Ltch1OpbstsPriDrLeft 1;
BA_REL_ "GenSigSuprvResp" BU_SG_REL_ BCM_LS SG_ 2154889216 Ltch1OpbstsPriDrLeft 1;
BA_REL_ "GenSigSuprvResp" BU_SG_REL_ ADIMa_LS SG_ 2154889216 DrMotCmpltOpnPriDrLeft 1;
BA_REL_ "GenSigSuprvResp" BU_SG_REL_ ADIMb_LS SG_ 2154889216 DrMotCmpltOpnPriDrLeft 1;
BA_REL_ "GenSigSuprvResp" BU_SG_REL_ BCM_LS SG_ 2154889216 DrMotCmpltOpnPriDrLeft 1;
BA_REL_ "GenSigSuprvResp" BU_SG_REL_ ADIMa_LS SG_ 2154889216 DrMotCmpltClsSecDrLeft 1;
BA_REL_ "GenSigSuprvResp" BU_SG_REL_ ADIMb_LS SG_ 2154889216 DrMotCmpltClsSecDrLeft 1;
BA_REL_ "GenSigSuprvResp" BU_SG_REL_ BCM_LS SG_ 2154889216 DrMotCmpltClsSecDrLeft 1;
BA_REL_ "GenSigSuprvResp" BU_SG_REL_ ADIMa_LS SG_ 2154889216 DrInMotPriLeft 1;
BA_REL_ "GenSigSuprvResp" BU_SG_REL_ ADIMb_LS SG_ 2154889216 DrInMotPriLeft 1;
BA_REL_ "GenSigSuprvResp" BU_SG_REL_ BCM_LS SG_ 2154889216 DrInMotPriLeft 1;
BA_REL_ "GenSigSuprvResp" BU_SG_REL_ ADIMa_LS SG_ 2154889216 DrClsPsnLtchRatSdeOfVehLeft 1;
BA_REL_ "GenSigSuprvResp" BU_SG_REL_ ADIMb_LS SG_ 2154889216 DrClsPsnLtchRatSdeOfVehLeft 1;
BA_REL_ "GenSigSuprvResp" BU_SG_REL_ BCM_LS SG_ 2154889216 DrClsPsnLtchRatSdeOfVehLeft 1;
BA_REL_ "GenSigSuprvResp" BU_SG_REL_ ADIMa_LS SG_ 2154889216 DrClsPsnLtchRatPriDrLeft 1;
BA_REL_ "GenSigSuprvResp" BU_SG_REL_ ADIMb_LS SG_ 2154889216 DrClsPsnLtchRatPriDrLeft 1;
BA_REL_ "GenSigSuprvResp" BU_SG_REL_ BCM_LS SG_ 2154889216 DrClsPsnLtchRatPriDrLeft 1;
BA_REL_ "GenSigSuprvResp" BU_SG_REL_ ADIMa_LS SG_ 2154889216 AntiPi1DetFbPriDrLeft 1;
BA_REL_ "GenSigSuprvResp" BU_SG_REL_ ADIMb_LS SG_ 2154889216 AntiPi1DetFbPriDrLeft 1;
BA_REL_ "GenSigSuprvResp" BU_SG_REL_ BCM_LS SG_ 2154889216 AntiPi1DetFbPriDrLeft 1;
BA_REL_ "GenSigSuprvResp" BU_SG_REL_ ADIMa_LS SG_ 2154889216 IntOpenswtReqLftSide 1;
BA_REL_ "GenSigSuprvResp" BU_SG_REL_ ADIMb_LS SG_ 2154889216 IntOpenswtReqLftSide 1;
BA_REL_ "GenSigSuprvResp" BU_SG_REL_ BCM_LS SG_ 2154889216 IntOpenswtReqLftSide 1;
BA_REL_ "GenSigSuprvResp" BU_SG_REL_ ADIMa_LS SG_ 2154889216 IntClseswtReqLftSide 1;
BA_REL_ "GenSigSuprvResp" BU_SG_REL_ ADIMb_LS SG_ 2154889216 IntClseswtReqLftSide 1;
BA_REL_ "GenSigSuprvResp" BU_SG_REL_ BCM_LS SG_ 2154889216 IntClseswtReqLftSide 1;
BA_REL_ "GenSigSuprvResp" BU_SG_REL_ ADIMa_LS SG_ 2154889216 ExtOpnClsSwReqLftSde 1;
BA_REL_ "GenSigSuprvResp" BU_SG_REL_ ADIMb_LS SG_ 2154889216 ExtOpnClsSwReqLftSde 1;
BA_REL_ "GenSigSuprvResp" BU_SG_REL_ BCM_LS SG_ 2154889216 ExtOpnClsSwReqLftSde 1;
BA_REL_ "GenSigSuprvResp" BU_SG_REL_ ADIMa_LS SG_ 2154881024 PosFedbkPriDrRight 1;
BA_REL_ "GenSigSuprvResp" BU_SG_REL_ ADIMb_LS SG_ 2154881024 PosFedbkPriDrRight 1;
BA_REL_ "GenSigSuprvResp" BU_SG_REL_ BCM_LS SG_ 2154881024 PosFedbkPriDrRight 1;
BA_REL_ "GenSigSuprvResp" BU_SG_REL_ ADIMa_LS SG_ 2154881024 ObsDetFbPriDrRight 1;
BA_REL_ "GenSigSuprvResp" BU_SG_REL_ ADIMb_LS SG_ 2154881024 ObsDetFbPriDrRight 1;
BA_REL_ "GenSigSuprvResp" BU_SG_REL_ BCM_LS SG_ 2154881024 ObsDetFbPriDrRight 1;
BA_REL_ "GenSigSuprvResp" BU_SG_REL_ ADIMa_LS SG_ 2154881024 Ltch3OPnDrPriDrRight 1;
BA_REL_ "GenSigSuprvResp" BU_SG_REL_ ADIMb_LS SG_ 2154881024 Ltch3OPnDrPriDrRight 1;
BA_REL_ "GenSigSuprvResp" BU_SG_REL_ BCM_LS SG_ 2154881024 Ltch3OPnDrPriDrRight 1;
BA_REL_ "GenSigSuprvResp" BU_SG_REL_ ADIMa_LS SG_ 2154881024 Ltch2OpnDrPriDrRight 1;
BA_REL_ "GenSigSuprvResp" BU_SG_REL_ ADIMb_LS SG_ 2154881024 Ltch2OpnDrPriDrRight 1;
BA_REL_ "GenSigSuprvResp" BU_SG_REL_ BCM_LS SG_ 2154881024 Ltch2OpnDrPriDrRight 1;
BA_REL_ "GenSigSuprvResp" BU_SG_REL_ ADIMa_LS SG_ 2154881024 Ltch1OpbstsPriDrRight 1;
BA_REL_ "GenSigSuprvResp" BU_SG_REL_ ADIMb_LS SG_ 2154881024 Ltch1OpbstsPriDrRight 1;
BA_REL_ "GenSigSuprvResp" BU_SG_REL_ BCM_LS SG_ 2154881024 Ltch1OpbstsPriDrRight 1;
BA_REL_ "GenSigSuprvResp" BU_SG_REL_ ADIMa_LS SG_ 2154881024 DrMotCmpltOpnPriDrRight 1;
BA_REL_ "GenSigSuprvResp" BU_SG_REL_ ADIMb_LS SG_ 2154881024 DrMotCmpltOpnPriDrRight 1;
BA_REL_ "GenSigSuprvResp" BU_SG_REL_ BCM_LS SG_ 2154881024 DrMotCmpltOpnPriDrRight 1;
BA_REL_ "GenSigSuprvResp" BU_SG_REL_ ADIMa_LS SG_ 2154881024 DrMotCmpltClsSecDrRight 1;
BA_REL_ "GenSigSuprvResp" BU_SG_REL_ ADIMb_LS SG_ 2154881024 DrMotCmpltClsSecDrRight 1;
BA_REL_ "GenSigSuprvResp" BU_SG_REL_ BCM_LS SG_ 2154881024 DrMotCmpltClsSecDrRight 1;
BA_REL_ "GenSigSuprvResp" BU_SG_REL_ ADIMa_LS SG_ 2154881024 DrInMotPriRight 1;
BA_REL_ "GenSigSuprvResp" BU_SG_REL_ ADIMb_LS SG_ 2154881024 DrInMotPriRight 1;
BA_REL_ "GenSigSuprvResp" BU_SG_REL_ BCM_LS SG_ 2154881024 DrInMotPriRight 1;
BA_REL_ "GenSigSuprvResp" BU_SG_REL_ ADIMa_LS SG_ 2154881024 DrClsPsnLtchRatSdeOfVehRight 1;
BA_REL_ "GenSigSuprvResp" BU_SG_REL_ ADIMb_LS SG_ 2154881024 DrClsPsnLtchRatSdeOfVehRight 1;
BA_REL_ "GenSigSuprvResp" BU_SG_REL_ BCM_LS SG_ 2154881024 DrClsPsnLtchRatSdeOfVehRight 1;
BA_REL_ "GenSigSuprvResp" BU_SG_REL_ ADIMa_LS SG_ 2154881024 DrClsPsnLtchRatPriDrRight 1;
BA_REL_ "GenSigSuprvResp" BU_SG_REL_ ADIMb_LS SG_ 2154881024 DrClsPsnLtchRatPriDrRight 1;
BA_REL_ "GenSigSuprvResp" BU_SG_REL_ BCM_LS SG_ 2154881024 DrClsPsnLtchRatPriDrRight 1;
BA_REL_ "GenSigSuprvResp" BU_SG_REL_ ADIMa_LS SG_ 2154881024 AntiPi2DetFbPriDrRight 1;
BA_REL_ "GenSigSuprvResp" BU_SG_REL_ ADIMb_LS SG_ 2154881024 AntiPi2DetFbPriDrRight 1;
BA_REL_ "GenSigSuprvResp" BU_SG_REL_ BCM_LS SG_ 2154881024 AntiPi2DetFbPriDrRight 1;
BA_REL_ "GenSigSuprvResp" BU_SG_REL_ ADIMa_LS SG_ 2154881024 AntiPi1DetFbPriDrRight 1;
BA_REL_ "GenSigSuprvResp" BU_SG_REL_ ADIMb_LS SG_ 2154881024 AntiPi1DetFbPriDrRight 1;
BA_REL_ "GenSigSuprvResp" BU_SG_REL_ BCM_LS SG_ 2154881024 AntiPi1DetFbPriDrRight 1;
BA_REL_ "GenSigSuprvResp" BU_SG_REL_ ADIMa_LS SG_ 2154881024 IntOpenswtReqRtSide 1;
BA_REL_ "GenSigSuprvResp" BU_SG_REL_ ADIMb_LS SG_ 2154881024 IntOpenswtReqRtSide 1;
BA_REL_ "GenSigSuprvResp" BU_SG_REL_ BCM_LS SG_ 2154881024 IntOpenswtReqRtSide 1;
BA_REL_ "GenSigSuprvResp" BU_SG_REL_ ADIMa_LS SG_ 2154881024 ExtOpnClsSwReqRtSde 1;
BA_REL_ "GenSigSuprvResp" BU_SG_REL_ ADIMb_LS SG_ 2154881024 ExtOpnClsSwReqRtSde 1;
BA_REL_ "GenSigSuprvResp" BU_SG_REL_ BCM_LS SG_ 2154881024 ExtOpnClsSwReqRtSde 1;
BA_REL_ "GenSigSuprvResp" BU_SG_REL_ ADIMa_LS SG_ 2154881024 IntClseswtReqRtSide 1;
BA_REL_ "GenSigSuprvResp" BU_SG_REL_ ADIMb_LS SG_ 2154881024 IntClseswtReqRtSide 1;
BA_REL_ "GenSigSuprvResp" BU_SG_REL_ BCM_LS SG_ 2154881024 IntClseswtReqRtSide 1;
BA_REL_ "GenSigSuprvResp" BU_SG_REL_ SAM_SL_LS SG_ 2154799104 SAMSecLftDrAlw 1;
BA_REL_ "GenSigSuprvResp" BU_SG_REL_ SAM_SL_LS SG_ 2154799104 AlwSecLftDrHldOpen 1;
BA_REL_ "GenSigSuprvResp" BU_SG_REL_ SAM_SL_LS SG_ 2154799104 Cmnd_SecIndLftDrHldopn 1;
BA_REL_ "GenSigSuprvResp" BU_SG_REL_ SAM_SL_LS SG_ 2154799104 SAM_SecndLftDrCmnd 1;
BA_REL_ "GenSigSuprvResp" BU_SG_REL_ BCM_LS SG_ 2154782720 SrcodOpnCmdPrRight 1;
BA_REL_ "GenSigSuprvResp" BU_SG_REL_ SAM_PR_LS SG_ 2154782720 SrcodOpnCmdPrRight 1;
BA_REL_ "GenSigSuprvResp" BU_SG_REL_ BCM_LS SG_ 2154782720 SrcodClsCmdPrRight 1;
BA_REL_ "GenSigSuprvResp" BU_SG_REL_ SAM_PR_LS SG_ 2154782720 SrcodClsCmdPrRight 1;
BA_REL_ "GenSigSuprvResp" BU_SG_REL_ BCM_LS SG_ 2154782720 SAM_PriIndRtDrCmnd 1;
BA_REL_ "GenSigSuprvResp" BU_SG_REL_ SAM_PR_LS SG_ 2154782720 SAM_PriIndRtDrCmnd 1;
BA_REL_ "GenSigSuprvResp" BU_SG_REL_ BCM_LS SG_ 2154782720 SAMPriRtDrAlw 1;
BA_REL_ "GenSigSuprvResp" BU_SG_REL_ SAM_PR_LS SG_ 2154782720 SAMPriRtDrAlw 1;
BA_REL_ "GenSigSuprvResp" BU_SG_REL_ BCM_LS SG_ 2154782720 SideDrMtnNotAlwIntPreWarnPrRight 1;
BA_REL_ "GenSigSuprvResp" BU_SG_REL_ SAM_PR_LS SG_ 2154782720 SideDrMtnNotAlwIntPreWarnPrRight 1;
BA_REL_ "GenSigSuprvResp" BU_SG_REL_ BCM_LS SG_ 2154782720 SideDrMtnNotAlwExtPreWarnPrRight 1;
BA_REL_ "GenSigSuprvResp" BU_SG_REL_ SAM_PR_LS SG_ 2154782720 SideDrMtnNotAlwExtPreWarnPrRight 1;
BA_REL_ "GenSigSuprvResp" BU_SG_REL_ BCM_LS SG_ 2154774528 AntiPn2FltdetLft 1;
BA_REL_ "GenSigSuprvResp" BU_SG_REL_ ADIMa_LS SG_ 2154774528 AntiPn2FltdetLft 1;
BA_REL_ "GenSigSuprvResp" BU_SG_REL_ ADIMb_LS SG_ 2154774528 AntiPn2FltdetLft 1;
BA_REL_ "GenSigSuprvResp" BU_SG_REL_ BCM_LS SG_ 2154774528 PosSenFltLft 1;
BA_REL_ "GenSigSuprvResp" BU_SG_REL_ ADIMa_LS SG_ 2154774528 PosSenFltLft 1;
BA_REL_ "GenSigSuprvResp" BU_SG_REL_ ADIMb_LS SG_ 2154774528 PosSenFltLft 1;
BA_REL_ "GenSigSuprvResp" BU_SG_REL_ SAM_PL_LS SG_ 2154774528 PosSenFltLft 1;
BA_REL_ "GenSigSuprvResp" BU_SG_REL_ BCM_LS SG_ 2154774528 ActMtrFltDetLft 1;
BA_REL_ "GenSigSuprvResp" BU_SG_REL_ ADIMa_LS SG_ 2154774528 ActMtrFltDetLft 1;
BA_REL_ "GenSigSuprvResp" BU_SG_REL_ ADIMb_LS SG_ 2154774528 ActMtrFltDetLft 1;
BA_REL_ "GenSigSuprvResp" BU_SG_REL_ SAM_PL_LS SG_ 2154774528 ActMtrFltDetLft 1;
BA_REL_ "GenSigSuprvResp" BU_SG_REL_ BCM_LS SG_ 2154774528 LtchMtr3FltdetLft 1;
BA_REL_ "GenSigSuprvResp" BU_SG_REL_ ADIMa_LS SG_ 2154774528 LtchMtr3FltdetLft 1;
BA_REL_ "GenSigSuprvResp" BU_SG_REL_ ADIMb_LS SG_ 2154774528 LtchMtr3FltdetLft 1;
BA_REL_ "GenSigSuprvResp" BU_SG_REL_ SAM_PL_LS SG_ 2154774528 LtchMtr3FltdetLft 1;
BA_REL_ "GenSigSuprvResp" BU_SG_REL_ BCM_LS SG_ 2154774528 LtchMtr2FltdetLft 1;
BA_REL_ "GenSigSuprvResp" BU_SG_REL_ ADIMa_LS SG_ 2154774528 LtchMtr2FltdetLft 1;
BA_REL_ "GenSigSuprvResp" BU_SG_REL_ ADIMb_LS SG_ 2154774528 LtchMtr2FltdetLft 1;
BA_REL_ "GenSigSuprvResp" BU_SG_REL_ SAM_PL_LS SG_ 2154774528 LtchMtr2FltdetLft 1;
BA_REL_ "GenSigSuprvResp" BU_SG_REL_ BCM_LS SG_ 2154774528 LtchMtr1FltdetLft 1;
BA_REL_ "GenSigSuprvResp" BU_SG_REL_ SAM_PL_LS SG_ 2154774528 LtchMtr1FltdetLft 1;
BA_REL_ "GenSigSuprvResp" BU_SG_REL_ BCM_LS SG_ 2154774528 AntiPn1FltDetLft 1;
BA_REL_ "GenSigSuprvResp" BU_SG_REL_ ADIMa_LS SG_ 2154774528 AntiPn1FltDetLft 1;
BA_REL_ "GenSigSuprvResp" BU_SG_REL_ ADIMb_LS SG_ 2154774528 AntiPn1FltDetLft 1;
BA_REL_ "GenSigSuprvResp" BU_SG_REL_ SAM_PL_LS SG_ 2154774528 AntiPn1FltDetLft 1;
BA_REL_ "GenSigSuprvResp" BU_SG_REL_ BCM_LS SG_ 2154774528 ContrlUnavbLft 1;
BA_REL_ "GenSigSuprvResp" BU_SG_REL_ ADIMa_LS SG_ 2154774528 ContrlUnavbLft 1;
BA_REL_ "GenSigSuprvResp" BU_SG_REL_ ADIMb_LS SG_ 2154774528 ContrlUnavbLft 1;
BA_REL_ "GenSigSuprvResp" BU_SG_REL_ SAM_PL_LS SG_ 2154774528 ContrlUnavbLft 1;
BA_REL_ "GenSigSuprvResp" BU_SG_REL_ BCM_LS SG_ 2154774528 IntclseswtchactLft 1;
BA_REL_ "GenSigSuprvResp" BU_SG_REL_ ADIMa_LS SG_ 2154774528 IntclseswtchactLft 1;
BA_REL_ "GenSigSuprvResp" BU_SG_REL_ ADIMb_LS SG_ 2154774528 IntclseswtchactLft 1;
BA_REL_ "GenSigSuprvResp" BU_SG_REL_ SAM_PL_LS SG_ 2154774528 IntclseswtchactLft 1;
BA_REL_ "GenSigSuprvResp" BU_SG_REL_ ADIMa_LS SG_ 2154774528 IntopenswtchactLft 1;
BA_REL_ "GenSigSuprvResp" BU_SG_REL_ ADIMb_LS SG_ 2154774528 IntopenswtchactLft 1;
BA_REL_ "GenSigSuprvResp" BU_SG_REL_ BCM_LS SG_ 2154774528 IntopenswtchactLft 1;
BA_REL_ "GenSigSuprvResp" BU_SG_REL_ SAM_PL_LS SG_ 2154774528 IntopenswtchactLft 1;
BA_REL_ "GenSigSuprvResp" BU_SG_REL_ BCM_LS SG_ 2154774528 ExtswtchactLft 1;
BA_REL_ "GenSigSuprvResp" BU_SG_REL_ ADIMa_LS SG_ 2154774528 ExtswtchactLft 1;
BA_REL_ "GenSigSuprvResp" BU_SG_REL_ ADIMb_LS SG_ 2154774528 ExtswtchactLft 1;
BA_REL_ "GenSigSuprvResp" BU_SG_REL_ SAM_PL_LS SG_ 2154774528 ExtswtchactLft 1;
BA_REL_ "GenSigSuprvResp" BU_SG_REL_ BCM_LS SG_ 2154774528 DrMotCmpltOpnSecDrLft 1;
BA_REL_ "GenSigSuprvResp" BU_SG_REL_ ADIMa_LS SG_ 2154774528 DrMotCmpltOpnSecDrLft 1;
BA_REL_ "GenSigSuprvResp" BU_SG_REL_ ADIMb_LS SG_ 2154774528 DrMotCmpltOpnSecDrLft 1;
BA_REL_ "GenSigSuprvResp" BU_SG_REL_ SAM_PL_LS SG_ 2154774528 DrMotCmpltOpnSecDrLft 1;
BA_REL_ "GenSigSuprvResp" BU_SG_REL_ BCM_LS SG_ 2154774528 DrMotCmpltClsSecDrLft 1;
BA_REL_ "GenSigSuprvResp" BU_SG_REL_ ADIMa_LS SG_ 2154774528 DrMotCmpltClsSecDrLft 1;
BA_REL_ "GenSigSuprvResp" BU_SG_REL_ ADIMb_LS SG_ 2154774528 DrMotCmpltClsSecDrLft 1;
BA_REL_ "GenSigSuprvResp" BU_SG_REL_ SAM_PL_LS SG_ 2154774528 DrMotCmpltClsSecDrLft 1;
BA_REL_ "GenSigSuprvResp" BU_SG_REL_ BCM_LS SG_ 2154774528 DrInMotSecLft 1;
BA_REL_ "GenSigSuprvResp" BU_SG_REL_ ADIMa_LS SG_ 2154774528 DrInMotSecLft 1;
BA_REL_ "GenSigSuprvResp" BU_SG_REL_ ADIMb_LS SG_ 2154774528 DrInMotSecLft 1;
BA_REL_ "GenSigSuprvResp" BU_SG_REL_ SAM_PL_LS SG_ 2154774528 DrInMotSecLft 1;
BA_REL_ "GenSigSuprvResp" BU_SG_REL_ BCM_LS SG_ 2154774528 Ltch2OpnDrSecDrLft 1;
BA_REL_ "GenSigSuprvResp" BU_SG_REL_ ADIMa_LS SG_ 2154774528 Ltch2OpnDrSecDrLft 1;
BA_REL_ "GenSigSuprvResp" BU_SG_REL_ ADIMb_LS SG_ 2154774528 Ltch2OpnDrSecDrLft 1;
BA_REL_ "GenSigSuprvResp" BU_SG_REL_ SAM_PL_LS SG_ 2154774528 Ltch2OpnDrSecDrLft 1;
BA_REL_ "GenSigSuprvResp" BU_SG_REL_ BCM_LS SG_ 2154774528 PosFedbkSecDrLft 1;
BA_REL_ "GenSigSuprvResp" BU_SG_REL_ ADIMa_LS SG_ 2154774528 PosFedbkSecDrLft 1;
BA_REL_ "GenSigSuprvResp" BU_SG_REL_ ADIMb_LS SG_ 2154774528 PosFedbkSecDrLft 1;
BA_REL_ "GenSigSuprvResp" BU_SG_REL_ SAM_PL_LS SG_ 2154774528 PosFedbkSecDrLft 1;
BA_REL_ "GenSigSuprvResp" BU_SG_REL_ BCM_LS SG_ 2154774528 AntiPi2DetFbSecDrLft 1;
BA_REL_ "GenSigSuprvResp" BU_SG_REL_ ADIMa_LS SG_ 2154774528 AntiPi2DetFbSecDrLft 1;
BA_REL_ "GenSigSuprvResp" BU_SG_REL_ ADIMb_LS SG_ 2154774528 AntiPi2DetFbSecDrLft 1;
BA_REL_ "GenSigSuprvResp" BU_SG_REL_ SAM_PL_LS SG_ 2154774528 AntiPi2DetFbSecDrLft 1;
BA_REL_ "GenSigSuprvResp" BU_SG_REL_ BCM_LS SG_ 2154774528 ObsDetFbSecDrLft 1;
BA_REL_ "GenSigSuprvResp" BU_SG_REL_ ADIMa_LS SG_ 2154774528 ObsDetFbSecDrLft 1;
BA_REL_ "GenSigSuprvResp" BU_SG_REL_ ADIMb_LS SG_ 2154774528 ObsDetFbSecDrLft 1;
BA_REL_ "GenSigSuprvResp" BU_SG_REL_ SAM_PL_LS SG_ 2154774528 ObsDetFbSecDrLft 1;
BA_REL_ "GenSigSuprvResp" BU_SG_REL_ BCM_LS SG_ 2154774528 Ltch3OpnDrSecDrLft 1;
BA_REL_ "GenSigSuprvResp" BU_SG_REL_ ADIMa_LS SG_ 2154774528 Ltch3OpnDrSecDrLft 1;
BA_REL_ "GenSigSuprvResp" BU_SG_REL_ ADIMb_LS SG_ 2154774528 Ltch3OpnDrSecDrLft 1;
BA_REL_ "GenSigSuprvResp" BU_SG_REL_ SAM_PL_LS SG_ 2154774528 Ltch3OpnDrSecDrLft 1;
BA_REL_ "GenSigSuprvResp" BU_SG_REL_ BCM_LS SG_ 2154774528 Ltch1OpbstsSecDrLft 1;
BA_REL_ "GenSigSuprvResp" BU_SG_REL_ ADIMa_LS SG_ 2154774528 Ltch1OpbstsSecDrLft 1;
BA_REL_ "GenSigSuprvResp" BU_SG_REL_ ADIMb_LS SG_ 2154774528 Ltch1OpbstsSecDrLft 1;
BA_REL_ "GenSigSuprvResp" BU_SG_REL_ SAM_PL_LS SG_ 2154774528 Ltch1OpbstsSecDrLft 1;
BA_REL_ "GenSigSuprvResp" BU_SG_REL_ BCM_LS SG_ 2154774528 HldOpnRlsActFbSecDrLft 1;
BA_REL_ "GenSigSuprvResp" BU_SG_REL_ ADIMa_LS SG_ 2154774528 HldOpnRlsActFbSecDrLft 1;
BA_REL_ "GenSigSuprvResp" BU_SG_REL_ ADIMb_LS SG_ 2154774528 HldOpnRlsActFbSecDrLft 1;
BA_REL_ "GenSigSuprvResp" BU_SG_REL_ SAM_PL_LS SG_ 2154774528 HldOpnRlsActFbSecDrLft 1;
BA_REL_ "GenSigSuprvResp" BU_SG_REL_ BCM_LS SG_ 2154774528 DrClsPsnLtchRatSecDrLft 1;
BA_REL_ "GenSigSuprvResp" BU_SG_REL_ ADIMa_LS SG_ 2154774528 DrClsPsnLtchRatSecDrLft 1;
BA_REL_ "GenSigSuprvResp" BU_SG_REL_ ADIMb_LS SG_ 2154774528 DrClsPsnLtchRatSecDrLft 1;
BA_REL_ "GenSigSuprvResp" BU_SG_REL_ SAM_PL_LS SG_ 2154774528 DrClsPsnLtchRatSecDrLft 1;
BA_REL_ "GenSigSuprvResp" BU_SG_REL_ BCM_LS SG_ 2154774528 CinActFbSecDrLft 1;
BA_REL_ "GenSigSuprvResp" BU_SG_REL_ ADIMa_LS SG_ 2154774528 CinActFbSecDrLft 1;
BA_REL_ "GenSigSuprvResp" BU_SG_REL_ ADIMb_LS SG_ 2154774528 CinActFbSecDrLft 1;
BA_REL_ "GenSigSuprvResp" BU_SG_REL_ SAM_PL_LS SG_ 2154774528 CinActFbSecDrLft 1;
BA_REL_ "GenSigSuprvResp" BU_SG_REL_ BCM_LS SG_ 2154774528 AntiPi1DetFbSecDrLft 1;
BA_REL_ "GenSigSuprvResp" BU_SG_REL_ ADIMa_LS SG_ 2154774528 AntiPi1DetFbSecDrLft 1;
BA_REL_ "GenSigSuprvResp" BU_SG_REL_ ADIMb_LS SG_ 2154774528 AntiPi1DetFbSecDrLft 1;
BA_REL_ "GenSigSuprvResp" BU_SG_REL_ SAM_PL_LS SG_ 2154774528 AntiPi1DetFbSecDrLft 1;
BA_REL_ "GenSigSuprvResp" BU_SG_REL_ SAM_PR_LS SG_ 2154749952 PosSenFltRt 1;
BA_REL_ "GenSigSuprvResp" BU_SG_REL_ BCM_LS SG_ 2154749952 PosSenFltRt 1;
BA_REL_ "GenSigSuprvResp" BU_SG_REL_ ADIMa_LS SG_ 2154749952 PosSenFltRt 1;
BA_REL_ "GenSigSuprvResp" BU_SG_REL_ ADIMb_LS SG_ 2154749952 PosSenFltRt 1;
BA_REL_ "GenSigSuprvResp" BU_SG_REL_ SAM_PR_LS SG_ 2154749952 LtchMtr3FltdetRt 1;
BA_REL_ "GenSigSuprvResp" BU_SG_REL_ BCM_LS SG_ 2154749952 LtchMtr3FltdetRt 1;
BA_REL_ "GenSigSuprvResp" BU_SG_REL_ ADIMa_LS SG_ 2154749952 LtchMtr3FltdetRt 1;
BA_REL_ "GenSigSuprvResp" BU_SG_REL_ ADIMb_LS SG_ 2154749952 LtchMtr3FltdetRt 1;
BA_REL_ "GenSigSuprvResp" BU_SG_REL_ SAM_PR_LS SG_ 2154749952 LtchMtr2FltdetRt 1;
BA_REL_ "GenSigSuprvResp" BU_SG_REL_ BCM_LS SG_ 2154749952 LtchMtr2FltdetRt 1;
BA_REL_ "GenSigSuprvResp" BU_SG_REL_ ADIMa_LS SG_ 2154749952 LtchMtr2FltdetRt 1;
BA_REL_ "GenSigSuprvResp" BU_SG_REL_ ADIMb_LS SG_ 2154749952 LtchMtr2FltdetRt 1;
BA_REL_ "GenSigSuprvResp" BU_SG_REL_ SAM_PR_LS SG_ 2154749952 LtchMtr1FltdetRt 1;
BA_REL_ "GenSigSuprvResp" BU_SG_REL_ BCM_LS SG_ 2154749952 LtchMtr1FltdetRt 1;
BA_REL_ "GenSigSuprvResp" BU_SG_REL_ ADIMa_LS SG_ 2154749952 LtchMtr1FltdetRt 1;
BA_REL_ "GenSigSuprvResp" BU_SG_REL_ ADIMb_LS SG_ 2154749952 LtchMtr1FltdetRt 1;
BA_REL_ "GenSigSuprvResp" BU_SG_REL_ SAM_PR_LS SG_ 2154749952 IntopenswtchactRt 1;
BA_REL_ "GenSigSuprvResp" BU_SG_REL_ BCM_LS SG_ 2154749952 IntopenswtchactRt 1;
BA_REL_ "GenSigSuprvResp" BU_SG_REL_ ADIMa_LS SG_ 2154749952 IntopenswtchactRt 1;
BA_REL_ "GenSigSuprvResp" BU_SG_REL_ ADIMb_LS SG_ 2154749952 IntopenswtchactRt 1;
BA_REL_ "GenSigSuprvResp" BU_SG_REL_ SAM_PR_LS SG_ 2154749952 ExtswtchactRt 1;
BA_REL_ "GenSigSuprvResp" BU_SG_REL_ BCM_LS SG_ 2154749952 ExtswtchactRt 1;
BA_REL_ "GenSigSuprvResp" BU_SG_REL_ ADIMa_LS SG_ 2154749952 ExtswtchactRt 1;
BA_REL_ "GenSigSuprvResp" BU_SG_REL_ ADIMb_LS SG_ 2154749952 ExtswtchactRt 1;
BA_REL_ "GenSigSuprvResp" BU_SG_REL_ SAM_PR_LS SG_ 2154749952 ContrlUnavbLft_Rt 1;
BA_REL_ "GenSigSuprvResp" BU_SG_REL_ BCM_LS SG_ 2154749952 ContrlUnavbLft_Rt 1;
BA_REL_ "GenSigSuprvResp" BU_SG_REL_ ADIMa_LS SG_ 2154749952 ContrlUnavbLft_Rt 1;
BA_REL_ "GenSigSuprvResp" BU_SG_REL_ ADIMb_LS SG_ 2154749952 ContrlUnavbLft_Rt 1;
BA_REL_ "GenSigSuprvResp" BU_SG_REL_ SAM_PR_LS SG_ 2154749952 AntiPn1FltDetRt 1;
BA_REL_ "GenSigSuprvResp" BU_SG_REL_ BCM_LS SG_ 2154749952 AntiPn1FltDetRt 1;
BA_REL_ "GenSigSuprvResp" BU_SG_REL_ ADIMa_LS SG_ 2154749952 AntiPn1FltDetRt 1;
BA_REL_ "GenSigSuprvResp" BU_SG_REL_ ADIMb_LS SG_ 2154749952 AntiPn1FltDetRt 1;
BA_REL_ "GenSigSuprvResp" BU_SG_REL_ SAM_PR_LS SG_ 2154749952 ActMtrFltDetRt 1;
BA_REL_ "GenSigSuprvResp" BU_SG_REL_ BCM_LS SG_ 2154749952 ActMtrFltDetRt 1;
BA_REL_ "GenSigSuprvResp" BU_SG_REL_ ADIMa_LS SG_ 2154749952 ActMtrFltDetRt 1;
BA_REL_ "GenSigSuprvResp" BU_SG_REL_ ADIMb_LS SG_ 2154749952 ActMtrFltDetRt 1;
BA_REL_ "GenSigSuprvResp" BU_SG_REL_ SAM_PR_LS SG_ 2154749952 PosFedbkSecDrRT 1;
BA_REL_ "GenSigSuprvResp" BU_SG_REL_ BCM_LS SG_ 2154749952 PosFedbkSecDrRT 1;
BA_REL_ "GenSigSuprvResp" BU_SG_REL_ ADIMa_LS SG_ 2154749952 PosFedbkSecDrRT 1;
BA_REL_ "GenSigSuprvResp" BU_SG_REL_ ADIMb_LS SG_ 2154749952 PosFedbkSecDrRT 1;
BA_REL_ "GenSigSuprvResp" BU_SG_REL_ SAM_PR_LS SG_ 2154749952 ObsDetFbSecDrRt 1;
BA_REL_ "GenSigSuprvResp" BU_SG_REL_ BCM_LS SG_ 2154749952 ObsDetFbSecDrRt 1;
BA_REL_ "GenSigSuprvResp" BU_SG_REL_ ADIMa_LS SG_ 2154749952 ObsDetFbSecDrRt 1;
BA_REL_ "GenSigSuprvResp" BU_SG_REL_ ADIMb_LS SG_ 2154749952 ObsDetFbSecDrRt 1;
BA_REL_ "GenSigSuprvResp" BU_SG_REL_ SAM_PR_LS SG_ 2154749952 Ltch3OpnDrSecDrRt 1;
BA_REL_ "GenSigSuprvResp" BU_SG_REL_ BCM_LS SG_ 2154749952 Ltch3OpnDrSecDrRt 1;
BA_REL_ "GenSigSuprvResp" BU_SG_REL_ ADIMa_LS SG_ 2154749952 Ltch3OpnDrSecDrRt 1;
BA_REL_ "GenSigSuprvResp" BU_SG_REL_ ADIMb_LS SG_ 2154749952 Ltch3OpnDrSecDrRt 1;
BA_REL_ "GenSigSuprvResp" BU_SG_REL_ SAM_PR_LS SG_ 2154749952 Ltch2OpnDrSecDrRt 1;
BA_REL_ "GenSigSuprvResp" BU_SG_REL_ BCM_LS SG_ 2154749952 Ltch2OpnDrSecDrRt 1;
BA_REL_ "GenSigSuprvResp" BU_SG_REL_ ADIMa_LS SG_ 2154749952 Ltch2OpnDrSecDrRt 1;
BA_REL_ "GenSigSuprvResp" BU_SG_REL_ ADIMb_LS SG_ 2154749952 Ltch2OpnDrSecDrRt 1;
BA_REL_ "GenSigSuprvResp" BU_SG_REL_ SAM_PR_LS SG_ 2154749952 Ltch1OpbstsSecDrRt 1;
BA_REL_ "GenSigSuprvResp" BU_SG_REL_ BCM_LS SG_ 2154749952 Ltch1OpbstsSecDrRt 1;
BA_REL_ "GenSigSuprvResp" BU_SG_REL_ ADIMa_LS SG_ 2154749952 Ltch1OpbstsSecDrRt 1;
BA_REL_ "GenSigSuprvResp" BU_SG_REL_ ADIMb_LS SG_ 2154749952 Ltch1OpbstsSecDrRt 1;
BA_REL_ "GenSigSuprvResp" BU_SG_REL_ SAM_PR_LS SG_ 2154749952 HldOpnRlsActFbSecDrRt 1;
BA_REL_ "GenSigSuprvResp" BU_SG_REL_ BCM_LS SG_ 2154749952 HldOpnRlsActFbSecDrRt 1;
BA_REL_ "GenSigSuprvResp" BU_SG_REL_ ADIMa_LS SG_ 2154749952 HldOpnRlsActFbSecDrRt 1;
BA_REL_ "GenSigSuprvResp" BU_SG_REL_ ADIMb_LS SG_ 2154749952 HldOpnRlsActFbSecDrRt 1;
BA_REL_ "GenSigSuprvResp" BU_SG_REL_ SAM_PR_LS SG_ 2154749952 DrMotCmpltOpnSecDrRt 1;
BA_REL_ "GenSigSuprvResp" BU_SG_REL_ BCM_LS SG_ 2154749952 DrMotCmpltOpnSecDrRt 1;
BA_REL_ "GenSigSuprvResp" BU_SG_REL_ ADIMa_LS SG_ 2154749952 DrMotCmpltOpnSecDrRt 1;
BA_REL_ "GenSigSuprvResp" BU_SG_REL_ ADIMb_LS SG_ 2154749952 DrMotCmpltOpnSecDrRt 1;
BA_REL_ "GenSigSuprvResp" BU_SG_REL_ SAM_PR_LS SG_ 2154749952 DrMotCmpltClsSecDrRt 1;
BA_REL_ "GenSigSuprvResp" BU_SG_REL_ BCM_LS SG_ 2154749952 DrMotCmpltClsSecDrRt 1;
BA_REL_ "GenSigSuprvResp" BU_SG_REL_ ADIMa_LS SG_ 2154749952 DrMotCmpltClsSecDrRt 1;
BA_REL_ "GenSigSuprvResp" BU_SG_REL_ ADIMb_LS SG_ 2154749952 DrMotCmpltClsSecDrRt 1;
BA_REL_ "GenSigSuprvResp" BU_SG_REL_ SAM_PR_LS SG_ 2154749952 DrInMotSecRt 1;
BA_REL_ "GenSigSuprvResp" BU_SG_REL_ BCM_LS SG_ 2154749952 DrInMotSecRt 1;
BA_REL_ "GenSigSuprvResp" BU_SG_REL_ ADIMa_LS SG_ 2154749952 DrInMotSecRt 1;
BA_REL_ "GenSigSuprvResp" BU_SG_REL_ ADIMb_LS SG_ 2154749952 DrInMotSecRt 1;
BA_REL_ "GenSigSuprvResp" BU_SG_REL_ SAM_PR_LS SG_ 2154749952 DrClsPsnLtchRatSecDrRt 1;
BA_REL_ "GenSigSuprvResp" BU_SG_REL_ BCM_LS SG_ 2154749952 DrClsPsnLtchRatSecDrRt 1;
BA_REL_ "GenSigSuprvResp" BU_SG_REL_ ADIMa_LS SG_ 2154749952 DrClsPsnLtchRatSecDrRt 1;
BA_REL_ "GenSigSuprvResp" BU_SG_REL_ ADIMb_LS SG_ 2154749952 DrClsPsnLtchRatSecDrRt 1;
BA_REL_ "GenSigSuprvResp" BU_SG_REL_ SAM_PR_LS SG_ 2154749952 CinActFbSecDrRt 1;
BA_REL_ "GenSigSuprvResp" BU_SG_REL_ BCM_LS SG_ 2154749952 CinActFbSecDrRt 1;
BA_REL_ "GenSigSuprvResp" BU_SG_REL_ ADIMa_LS SG_ 2154749952 CinActFbSecDrRt 1;
BA_REL_ "GenSigSuprvResp" BU_SG_REL_ ADIMb_LS SG_ 2154749952 CinActFbSecDrRt 1;
BA_REL_ "GenSigSuprvResp" BU_SG_REL_ SAM_PR_LS SG_ 2154749952 AntiPi2DetFbSecDrRt 1;
BA_REL_ "GenSigSuprvResp" BU_SG_REL_ BCM_LS SG_ 2154749952 AntiPi2DetFbSecDrRt 1;
BA_REL_ "GenSigSuprvResp" BU_SG_REL_ ADIMa_LS SG_ 2154749952 AntiPi2DetFbSecDrRt 1;
BA_REL_ "GenSigSuprvResp" BU_SG_REL_ ADIMb_LS SG_ 2154749952 AntiPi2DetFbSecDrRt 1;
BA_REL_ "GenSigSuprvResp" BU_SG_REL_ SAM_PR_LS SG_ 2154749952 AntiPi1DetFbSecDrRt 1;
BA_REL_ "GenSigSuprvResp" BU_SG_REL_ BCM_LS SG_ 2154749952 AntiPi1DetFbSecDrRt 1;
BA_REL_ "GenSigSuprvResp" BU_SG_REL_ ADIMa_LS SG_ 2154749952 AntiPi1DetFbSecDrRt 1;
BA_REL_ "GenSigSuprvResp" BU_SG_REL_ ADIMb_LS SG_ 2154749952 AntiPi1DetFbSecDrRt 1;
BA_REL_ "GenSigSuprvResp" BU_SG_REL_ ADIMa_LS SG_ 2154749952 IntclseswtchactRt 1;
BA_REL_ "GenSigSuprvResp" BU_SG_REL_ ADIMb_LS SG_ 2154749952 IntclseswtchactRt 1;
BA_REL_ "GenSigSuprvResp" BU_SG_REL_ BCM_LS SG_ 2154749952 IntclseswtchactRt 1;
BA_REL_ "GenSigSuprvResp" BU_SG_REL_ SAM_PR_LS SG_ 2154749952 IntclseswtchactRt 1;
BA_REL_ "GenSigSuprvResp" BU_SG_REL_ BCM_LS SG_ 2154749952 AntiPn2FltdetRt 1;
BA_REL_ "GenSigSuprvResp" BU_SG_REL_ ADIMa_LS SG_ 2154749952 AntiPn2FltdetRt 1;
BA_REL_ "GenSigSuprvResp" BU_SG_REL_ ADIMb_LS SG_ 2154749952 AntiPn2FltdetRt 1;
BA_REL_ "GenSigSuprvResp" BU_SG_REL_ SAM_PR_LS SG_ 2154749952 AntiPn2FltdetRt 1;
BA_REL_ "GenSigSuprvResp" BU_SG_REL_ SAM_SR_LS SG_ 2154741760 Alw_Cmnd_SecIndRtDrHldopn 1;
BA_REL_ "GenSigSuprvResp" BU_SG_REL_ SAM_SR_LS SG_ 2154741760 SAM_secRtDr_Alw 1;
BA_REL_ "GenSigSuprvResp" BU_SG_REL_ SAM_SR_LS SG_ 2154741760 Cmnd_SecIndRtDrHldopn 1;
BA_REL_ "GenSigSuprvResp" BU_SG_REL_ SAM_SR_LS SG_ 2154741760 SAM_SecIndRtDrCmnd 1;
BA_REL_ "GenSigSuprvResp" BU_SG_REL_ ADIMb_LS SG_ 2154872832 MCTWiFiSt 1;
BA_REL_ "GenSigSuprvResp" BU_SG_REL_ ADIMb_LS SG_ 2154872832 MCTStofHlthChcksm 1;
BA_REL_ "GenSigSuprvResp" BU_SG_REL_ ADIMb_LS SG_ 2154872832 MCTStofHlthARC 1;
BA_REL_ "GenSigSuprvResp" BU_SG_REL_ ADIMb_LS SG_ 2154872832 MCTPrEthSt 1;
BA_REL_ "GenSigSuprvResp" BU_SG_REL_ ADIMb_LS SG_ 2154872832 MCTOfbSvcSt 1;
BA_REL_ "GenSigSuprvResp" BU_SG_REL_ ADIMb_LS SG_ 2154872832 MCTNmbrTbltsComm 1;
BA_REL_ "GenSigSuprvResp" BU_SG_REL_ ADIMb_LS SG_ 2154872832 MCTNmbrPwrSplsOprtg 1;
BA_REL_ "GenSigSuprvResp" BU_SG_REL_ ADIMb_LS SG_ 2154872832 MCTNmbrOnsBtnSetsOprtg 1;
BA_REL_ "GenSigSuprvResp" BU_SG_REL_ ADIMb_LS SG_ 2154872832 MCTNmbrNADsOprtg 1;
BA_REL_ "GenSigSuprvResp" BU_SG_REL_ ADIMb_LS SG_ 2154872832 MCTNmbrMicsOprtg 1;
BA_REL_ "GenSigSuprvResp" BU_SG_REL_ ADIMb_LS SG_ 2154872832 MCTNmbrEthPrtsOprtg 1;
BA_REL_ "GenSigSuprvResp" BU_SG_REL_ ADIMb_LS SG_ 2154872832 MCTNmbrCamsOprtg 1;
BA_REL_ "GenSigSuprvResp" BU_SG_REL_ ADIMb_LS SG_ 2154872832 MCTNmbrAntOprtg 1;
BA_REL_ "GenSigSuprvResp" BU_SG_REL_ ADIMb_LS SG_ 2154872832 MCTNmbrVPNsOprtg 1;
BA_REL_ "GenSigSuprvResp" BU_SG_REL_ ADIMb_LS SG_ 2154872832 MCTLSLANSt 1;
BA_REL_ "GenSigSuprvResp" BU_SG_REL_ ADIMb_LS SG_ 2154872832 MCTIPCSt 1;
BA_REL_ "GenSigSuprvResp" BU_SG_REL_ ADIMb_LS SG_ 2154872832 MCTHSLANSt 1;
BA_REL_ "GenSigSuprvResp" BU_SG_REL_ ADIMb_LS SG_ 2154872832 MCTHwSt 1;
BA_REL_ "GenSigSuprvResp" BU_SG_REL_ ADIMb_LS SG_ 2154872832 MCTGPSSt 1;
BA_REL_ "GenSigSuprvResp" BU_SG_REL_ ADIMb_LS SG_ 2154872832 MCTCGMSt 1;
BA_REL_ "GenSigSuprvResp" BU_SG_REL_ ADIMb_LS SG_ 2154872832 MCTBCMSt 1;
BA_REL_ "GenSigSuprvResp" BU_SG_REL_ ADIMb_LS SG_ 2154872832 MCTAudSt 1;
BA_REL_ "GenSigSuprvResp" BU_SG_REL_ ADIMb_LS SG_ 2154872832 MCTADSCCommSt 1;
BA_REL_ "GenSigSuprvResp" BU_SG_REL_ ADIMb_LS SG_ 2154872832 MCTADIMCommSt 1;
BA_REL_ "GenSigSuprvResp" BU_SG_REL_ ECC_LS SG_ 2158952448 ODDMR_ReqType 1;
BA_REL_ "GenSigSuprvResp" BU_SG_REL_ ECC_LS SG_ 2158952448 ODDMR_FUCID 1;
BA_REL_ "GenSigSuprvResp" BU_SG_REL_ ECC_LS SG_ 2158952448 ODDMR_DispMID 1;
BA_REL_ "GenSigSuprvResp" BU_SG_REL_ ECC_LS SG_ 2158952448 ODDMR_DataID2Vld 1;
BA_REL_ "GenSigSuprvResp" BU_SG_REL_ ECC_LS SG_ 2158952448 ODDMR_DataID2 1;
BA_REL_ "GenSigSuprvResp" BU_SG_REL_ ECC_LS SG_ 2158952448 ODDMR_DataID3Vld 1;
BA_REL_ "GenSigSuprvResp" BU_SG_REL_ ECC_LS SG_ 2158952448 ODDMR_DataID3 1;
BA_REL_ "GenSigSuprvResp" BU_SG_REL_ ECC_LS SG_ 2158952448 ODDMR_DataID1 1;
BA_REL_ "GenSigSuprvResp" BU_SG_REL_ ECC_LS SG_ 2158952448 ODDMR_DataID4Vld 1;
BA_REL_ "GenSigSuprvResp" BU_SG_REL_ ECC_LS SG_ 2158952448 ODDMR_DataID4 1;
BA_REL_ "GenSigSuprvResp" BU_SG_REL_ ECC_LS SG_ 2158952448 ODDMR_DataID5Vld 1;
BA_REL_ "GenSigSuprvResp" BU_SG_REL_ ECC_LS SG_ 2158952448 ODDMR_DataID5 1;
VAL_ 2154831872 SrcodOpnCmdPrRight_Bkp 7 "FOB" 6 "AV Ride Handeling" 5 "Tablet" 4 "Back Office" 3 "BLE-VKM/KeyPAss" 2 "Interior Switch" 1 "Exterior Switch" 0 "Unknown" ;
VAL_ 2154831872 SrcodClsCmdPrRightBkp 7 "FOB" 6 "AV Ride Handeling" 5 "Tablet" 4 "Back Office" 3 "BLE-VKM/KeyPAss" 2 "Interior Switch" 1 "Exterior Switch" 0 "Unknown" ;
VAL_ 2154831872 SideDrMtnNotAlwIntPreWrnPrRt_Bkp 1 "true" 0 "false" ;
VAL_ 2154831872 SideDrMtnNtAlwExtPreWrnPrRt_Bkp 1 "true" 0 "false" ;
VAL_ 2154831872 SAM_PriIndRtDrCmnd_Bkp 4 "Primary Door Stop" 3 "Primary Door Unlatch" 2 "Primary Door Open" 1 "Primary Door Close" 0 " No Action" ;
VAL_ 2154831872 SAMPriRtDrAlw_Bkp 7 " No Action" 6 " Primary Door Close" 5 " Primary Door Open" 4 " Primary Door Unlatch" 3 " Primary Door Stop" ;
VAL_ 2151759872 RrClsRelRq 0 "No Activation" 1 "Release" ;
VAL_ 2151759872 CLRAF_UnandRsv3 1 "true" 0 "false" ;
VAL_ 2151759872 CLRAF_UnandRsv2 1 "true" 0 "false" ;
VAL_ 2151759872 CLRAF_UnandRsv1 1 "true" 0 "false" ;
VAL_ 2151759872 CLRAF_Unl_Lk 4 "Un-double Lock" 3 "Double Lock" 2 "Lock" 1 "Unlock" 0 "No Command" ;
VAL_ 2151759872 CLRAF_RRD 1 "true" 0 "false" ;
VAL_ 2151759872 CLRAF_RLD 1 "true" 0 "false" ;
VAL_ 2151759872 CLRAF_RrCls 1 "true" 0 "false" ;
VAL_ 2151759872 CLRAF_PD 1 "true" 0 "false" ;
VAL_ 2151759872 CLRAF_Hd 1 "true" 0 "false" ;
VAL_ 2151759872 CLRAF_FuelD 1 "true" 0 "false" ;
VAL_ 2151759872 CLRAF_DD 1 "true" 0 "false" ;
VAL_ 2151759872 CLRAF_ActFunc 11 "Exterior Lock Switch" 10 "Lockout Prevention" 9 "Re-locking" 8 "Delayed Locking" 7 "Enhanced Services/Telematics" 6 "Passive Remote Keyfob" 5 "Active Remote Keyfob" 4 "Emergency" 3 "Rr Closure Key Cylinder/Release Sw" 2 "Driver Door Key Cylinder" 1 "Power Door Lock Switch" 0 "Auto Door Lock" ;
VAL_ 2154815488 SrcodOpnCmdPrLeft 7 "FOB" 6 "AV Ride Handeling" 5 "Tablet" 4 "Back Office" 3 "BLE-VKM/KeyPAss" 2 "Interior Switch" 1 "Exterior Switch" 0 "Unknown" ;
VAL_ 2154815488 SrcodClsCmdPrLeft 7 "FOB" 6 "AV Ride Handeling" 5 "Tablet" 4 "Back Office" 3 "BLE-VKM/KeyPAss" 2 "Interior Switch" 1 "Exterior Switch" 0 "Unknown" ;
VAL_ 2154815488 SideDrMtnNotAlwIntPreWarnPrLeft 1 "true" 0 "false" ;
VAL_ 2154815488 SideDrMtnNotAlwExtPreWarnPrLeft 1 "true" 0 "false" ;
VAL_ 2154815488 SAM_PriIndRtDrCmnd 4 "Primary Door Stop" 3 "Primary Door Unlatch" 2 "Primary Door Open" 1 "Primary Door Close" 0 " No Action" ;
VAL_ 2154815488 SAMPriRtDrAlw 7 " No Action" 6 " Primary Door Close" 5 " Primary Door Open" 4 " Primary Door Unlatch" 3 " Primary Door Stop" ;
VAL_ 2154889216 AntiPi2DetFbPriDrLeft 1 "true" 0 "false" ;
VAL_ 2154889216 ObsDetFbPriDrLeft 1 "true" 0 "false" ;
VAL_ 2154889216 Ltch3OPnDrPriDrLeft 1 "true" 0 "false" ;
VAL_ 2154889216 Ltch2OpnDrPriDrLeft 1 "true" 0 "false" ;
VAL_ 2154889216 Ltch1OpbstsPriDrLeft 1 "true" 0 "false" ;
VAL_ 2154889216 DrMotCmpltOpnPriDrLeft 1 "true" 0 "false" ;
VAL_ 2154889216 DrMotCmpltClsSecDrLeft 1 "true" 0 "false" ;
VAL_ 2154889216 DrInMotPriLeft 1 "true" 0 "false" ;
VAL_ 2154889216 DrClsPsnLtchRatSdeOfVehLeft 1 "true" 0 "false" ;
VAL_ 2154889216 DrClsPsnLtchRatPriDrLeft 1 "true" 0 "false" ;
VAL_ 2154889216 AntiPi1DetFbPriDrLeft 1 "true" 0 "false" ;
VAL_ 2154889216 IntOpenswtReqLftSide 1 "true" 0 "false" ;
VAL_ 2154889216 IntClseswtReqLftSide 1 "true" 0 "false" ;
VAL_ 2154889216 ExtOpnClsSwReqLftSde 1 "true" 0 "false" ;
VAL_ 2154881024 ObsDetFbPriDrRight 1 "true" 0 "false" ;
VAL_ 2154881024 Ltch3OPnDrPriDrRight 1 "true" 0 "false" ;
VAL_ 2154881024 Ltch2OpnDrPriDrRight 1 "true" 0 "false" ;
VAL_ 2154881024 Ltch1OpbstsPriDrRight 1 "true" 0 "false" ;
VAL_ 2154881024 DrMotCmpltOpnPriDrRight 1 "true" 0 "false" ;
VAL_ 2154881024 DrMotCmpltClsSecDrRight 1 "true" 0 "false" ;
VAL_ 2154881024 DrInMotPriRight 1 "true" 0 "false" ;
VAL_ 2154881024 DrClsPsnLtchRatSdeOfVehRight 1 "true" 0 "false" ;
VAL_ 2154881024 DrClsPsnLtchRatPriDrRight 1 "true" 0 "false" ;
VAL_ 2154881024 AntiPi2DetFbPriDrRight 1 "true" 0 "false" ;
VAL_ 2154881024 AntiPi1DetFbPriDrRight 1 "true" 0 "false" ;
VAL_ 2154881024 IntOpenswtReqRtSide 1 "true" 0 "false" ;
VAL_ 2154881024 ExtOpnClsSwReqRtSde 1 "true" 0 "false" ;
VAL_ 2154881024 IntClseswtReqRtSide 1 "true" 0 "false" ;
VAL_ 2154799104 SAMSecLftDrAlw 7 " No Action" 6 "Secondary Door Close" 5 "Secondary Door Open" 4 "Secondary Door Unlatch" 3 "Secondary Door Stop" ;
VAL_ 2154799104 AlwSecLftDrHldOpen 1 "Disable" 0 "Enable" ;
VAL_ 2154799104 Cmnd_SecIndLftDrHldopn 1 "Enable" 0 "Disable" ;
VAL_ 2154799104 SAM_SecndLftDrCmnd 4 "Secondary Door Stop" 3 "Secondary Door Unlatch" 2 "Secondary Door Open" 1 "Secondary Door Close" 0 " No Action" ;
VAL_ 2154782720 SrcodOpnCmdPrRight 7 "FOB" 6 "AV Ride Handeling" 5 "Tablet" 4 "Back Office" 3 "BLE-VKM/KeyPAss" 2 "Interior Switch" 1 "Exterior Switch" 0 "Unknown" ;
VAL_ 2154782720 SrcodClsCmdPrRight 7 "FOB" 6 "AV Ride Handeling" 5 "Tablet" 4 "Back Office" 3 "BLE-VKM/KeyPAss" 2 "Interior Switch" 1 "Exterior Switch" 0 "Unknown" ;
VAL_ 2154782720 SAM_PriIndRtDrCmnd 4 "Primary Door Stop" 3 "Primary Door Unlatch" 2 "Primary Door Open" 1 "Primary Door Close" 0 " No Action" ;
VAL_ 2154782720 SAMPriRtDrAlw 7 " No Action" 6 " Primary Door Close" 5 " Primary Door Open" 4 " Primary Door Unlatch" 3 " Primary Door Stop" ;
VAL_ 2154782720 SideDrMtnNotAlwIntPreWarnPrRight 1 "true" 0 "false" ;
VAL_ 2154782720 SideDrMtnNotAlwExtPreWarnPrRight 1 "true" 0 "false" ;
VAL_ 2154774528 AntiPn2FltdetLft 1 "true" 0 "false" ;
VAL_ 2154774528 PosSenFltLft 1 "true" 0 "false" ;
VAL_ 2154774528 ActMtrFltDetLft 1 "true" 0 "false" ;
VAL_ 2154774528 LtchMtr3FltdetLft 1 "true" 0 "false" ;
VAL_ 2154774528 LtchMtr2FltdetLft 1 "true" 0 "false" ;
VAL_ 2154774528 LtchMtr1FltdetLft 1 "true" 0 "false" ;
VAL_ 2154774528 AntiPn1FltDetLft 1 "true" 0 "false" ;
VAL_ 2154774528 ContrlUnavbLft 1 "true" 0 "false" ;
VAL_ 2154774528 IntclseswtchactLft 1 "true" 0 "false" ;
VAL_ 2154774528 IntopenswtchactLft 1 "true" 0 "false" ;
VAL_ 2154774528 ExtswtchactLft 1 "true" 0 "false" ;
VAL_ 2154774528 DrMotCmpltOpnSecDrLft 1 "true" 0 "false" ;
VAL_ 2154774528 DrMotCmpltClsSecDrLft 1 "true" 0 "false" ;
VAL_ 2154774528 DrInMotSecLft 1 "true" 0 "false" ;
VAL_ 2154774528 Ltch2OpnDrSecDrLft 1 "true" 0 "false" ;
VAL_ 2154774528 AntiPi2DetFbSecDrLft 1 "true" 0 "false" ;
VAL_ 2154774528 ObsDetFbSecDrLft 1 "true" 0 "false" ;
VAL_ 2154774528 Ltch3OpnDrSecDrLft 1 "true" 0 "false" ;
VAL_ 2154774528 Ltch1OpbstsSecDrLft 1 "true" 0 "false" ;
VAL_ 2154774528 HldOpnRlsActFbSecDrLft 1 "true" 0 "false" ;
VAL_ 2154774528 DrClsPsnLtchRatSecDrLft 1 "true" 0 "false" ;
VAL_ 2154774528 CinActFbSecDrLft 1 "true" 0 "false" ;
VAL_ 2154774528 AntiPi1DetFbSecDrLft 1 "true" 0 "false" ;
VAL_ 2154749952 PosSenFltRt 1 "true" 0 "false" ;
VAL_ 2154749952 LtchMtr3FltdetRt 1 "true" 0 "false" ;
VAL_ 2154749952 LtchMtr2FltdetRt 1 "true" 0 "false" ;
VAL_ 2154749952 LtchMtr1FltdetRt 1 "true" 0 "false" ;
VAL_ 2154749952 IntopenswtchactRt 1 "true" 0 "false" ;
VAL_ 2154749952 ExtswtchactRt 1 "true" 0 "false" ;
VAL_ 2154749952 ContrlUnavbLft_Rt 1 "true" 0 "false" ;
VAL_ 2154749952 AntiPn1FltDetRt 1 "true" 0 "false" ;
VAL_ 2154749952 ActMtrFltDetRt 1 "true" 0 "false" ;
VAL_ 2154749952 ObsDetFbSecDrRt 1 "true" 0 "false" ;
VAL_ 2154749952 Ltch3OpnDrSecDrRt 1 "true" 0 "false" ;
VAL_ 2154749952 Ltch2OpnDrSecDrRt 1 "true" 0 "false" ;
VAL_ 2154749952 Ltch1OpbstsSecDrRt 1 "true" 0 "false" ;
VAL_ 2154749952 HldOpnRlsActFbSecDrRt 1 "true" 0 "false" ;
VAL_ 2154749952 DrMotCmpltOpnSecDrRt 1 "true" 0 "false" ;
VAL_ 2154749952 DrMotCmpltClsSecDrRt 1 "true" 0 "false" ;
VAL_ 2154749952 DrInMotSecRt 1 "true" 0 "false" ;
VAL_ 2154749952 DrClsPsnLtchRatSecDrRt 1 "true" 0 "false" ;
VAL_ 2154749952 CinActFbSecDrRt 1 "true" 0 "false" ;
VAL_ 2154749952 AntiPi2DetFbSecDrRt 1 "true" 0 "false" ;
VAL_ 2154749952 AntiPi1DetFbSecDrRt 1 "true" 0 "false" ;
VAL_ 2154749952 IntclseswtchactRt 1 "true" 0 "false" ;
VAL_ 2154749952 AntiPn2FltdetRt 1 "true" 0 "false" ;
VAL_ 2154741760 Alw_Cmnd_SecIndRtDrHldopn 1 "Disable" 0 "Enable" ;
VAL_ 2154741760 SAM_secRtDr_Alw 7 " No Action" 6 "Secondary Door Close" 5 "Secondary Door Open" 4 "Secondary Door Unlatch" 3 "Secondary Door Stop" ;
VAL_ 2154741760 Cmnd_SecIndRtDrHldopn 1 "Enable" 0 "Disable" ;
VAL_ 2154741760 SAM_SecIndRtDrCmnd 4 "Secondary Door Stop" 3 "Secondary Door Unlatch" 2 "Secondary Door Open" 1 "Secondary Door Close" 0 " No Action" ;
VAL_ 2154766336 RedRFPwrDrCmnd 3 "Open" 2 "Abort" 1 "Close" 0 "No Action" ;
VAL_ 2154766336 RedRFPwrDrAlw 3 "No Action" 2 "Close" 1 "Abort" 0 "Open" ;
VAL_ 2154766336 RedLFDPwrDrCmnd 3 "Open" 2 "Abort" 1 "Close" 0 "No Action" ;
VAL_ 2154766336 RedLFPwrDrAlw 3 "No Action" 2 "Close" 1 "Abort" 0 "Open" ;
VAL_ 2154766336 RedLRPwrDrAlw 3 "No Action" 2 "Close" 1 "Abort" 0 "Open" ;
VAL_ 2154766336 RedRRPwrDrAlw 3 "No Action" 2 "Close" 1 "Abort" 0 "Open" ;
VAL_ 2154766336 RedRRPwrDrCmnd 3 "Open" 2 "Abort" 1 "Close" 0 "No Action" ;
VAL_ 2154766336 RedLRDPwrDrCmnd 3 "Open" 2 "Abort" 1 "Close" 0 "No Action" ;
VAL_ 2154872832 MCTWiFiSt 0 "Unknown" 1 "Normal Operating Mode" 2 "Faulted" ;
VAL_ 2154872832 MCTPrEthSt 0 "Unknown" 1 "Normal Operating Mode" 2 "Faulted" ;
VAL_ 2154872832 MCTOfbSvcSt 6 "Reserved" 5 "Reserved" 4 "Reserved" 3 "Reserved" 7 "Reserved" 0 "Unknown" 1 "Normal Operating Mode" 2 "Faulted" ;
VAL_ 2154872832 MCTLSLANSt 0 "Unknown" 1 "Normal Operating Mode" 2 "Faulted" ;
VAL_ 2154872832 MCTIPCSt 0 "Unknown" 1 "Normal Operating Mode" 2 "Faulted" ;
VAL_ 2154872832 MCTHSLANSt 0 "Unknown" 1 "Normal Operating Mode" 2 "Faulted" ;
VAL_ 2154872832 MCTHwSt 0 "Unknown" 1 "Normal Operating Mode" 2 "Faulted" ;
VAL_ 2154872832 MCTGPSSt 0 "Unknown" 1 "Normal Operating Mode" 2 "Faulted" ;
VAL_ 2154872832 MCTCGMSt 0 "Unknown" 1 "Normal Operating Mode" 2 "Faulted" ;
VAL_ 2154872832 MCTBCMSt 0 "Unknown" 1 "Normal Operating Mode" 2 "Faulted" ;
VAL_ 2154872832 MCTAudSt 0 "Unknown" 1 "Normal Operating Mode" 2 "Faulted" ;
VAL_ 2154872832 MCTADSCCommSt 4 "Both Faulted" 3 "A Norm operating mode,B Faulted" 0 "Unknown" 1 "Both normal operating mode" 2 "A Faulted, B Normal operating " ;
VAL_ 2154872832 MCTADIMCommSt 4 "Both Faulted" 3 "A Norm operating mode,B Faulted" 0 "Unknown" 1 "Both normal operating mode" 2 "A Faulted, B Normal operating " ;
VAL_ 2158952448 ODDMR_ReqType 0 "Subscribe: FU sends DynData back and then on change) " 1 "Unsubscribe: cancel previous Subscribe" ;
VAL_ 2158952448 ODDMR_DispMID 128 "Reserved" 64 "Reserved" 32 "OTIM" 16 "RearDisplayTwo" 8 "RearDisplayOne" 4 "AuxIP" 2 "CenterStack" 1 "IPC" ;
VAL_ 2158952448 ODDMR_DataID2Vld 1 "true" 0 "false" ;
VAL_ 2158952448 ODDMR_DataID3Vld 1 "true" 0 "false" ;
VAL_ 2158952448 ODDMR_DataID4Vld 1 "true" 0 "false" ;
VAL_ 2158952448 ODDMR_DataID5Vld 1 "true" 0 "false" ;
SIG_GROUP_ 2151759872 CntrlLckRqwExtActFun 1 : CLRAF_UnandRsv3 CLRAF_UnandRsv2 CLRAF_UnandRsv1 CLRAF_Unl_Lk CLRAF_RRD CLRAF_RLD CLRAF_RrCls CLRAF_PD CLRAF_Hd CLRAF_FuelD CLRAF_DD CLRAF_ActFunc;
SIG_GROUP_ 2154889216 PriDrleft 1 : AntiPi2DetFbPriDrLeft PosFedbkPriDrLeft ObsDetFbPriDrLeft Ltch3OPnDrPriDrLeft Ltch2OpnDrPriDrLeft Ltch1OpbstsPriDrLeft DrMotCmpltOpnPriDrLeft DrMotCmpltClsSecDrLeft DrInMotPriLeft DrClsPsnLtchRatSdeOfVehLeft DrClsPsnLtchRatPriDrLeft AntiPi1DetFbPriDrLeft;
SIG_GROUP_ 2154889216 ReqlftSide 1 : IntOpenswtReqLftSide IntClseswtReqLftSide ExtOpnClsSwReqLftSde;
SIG_GROUP_ 2154881024 PriDrRight 1 : PosFedbkPriDrRight ObsDetFbPriDrRight Ltch3OPnDrPriDrRight Ltch2OpnDrPriDrRight Ltch1OpbstsPriDrRight DrMotCmpltOpnPriDrRight DrMotCmpltClsSecDrRight DrInMotPriRight DrClsPsnLtchRatSdeOfVehRight DrClsPsnLtchRatPriDrRight AntiPi2DetFbPriDrRight AntiPi1DetFbPriDrRight;
SIG_GROUP_ 2154881024 ReQRtSide 1 : IntOpenswtReqRtSide ExtOpnClsSwReqRtSde IntClseswtReqRtSide;
SIG_GROUP_ 2154774528 SecDrlft 1 : DrMotCmpltOpnSecDrLft DrMotCmpltClsSecDrLft DrInMotSecLft Ltch2OpnDrSecDrLft PosFedbkSecDrLft AntiPi2DetFbSecDrLft ObsDetFbSecDrLft Ltch3OpnDrSecDrLft Ltch1OpbstsSecDrLft HldOpnRlsActFbSecDrLft DrClsPsnLtchRatSecDrLft CinActFbSecDrLft AntiPi1DetFbSecDrLft;
SIG_GROUP_ 2154749952 SecDrRt 1 : PosFedbkSecDrRT ObsDetFbSecDrRt Ltch3OpnDrSecDrRt Ltch2OpnDrSecDrRt Ltch1OpbstsSecDrRt HldOpnRlsActFbSecDrRt DrMotCmpltOpnSecDrRt DrMotCmpltClsSecDrRt DrInMotSecRt DrClsPsnLtchRatSecDrRt CinActFbSecDrRt AntiPi2DetFbSecDrRt AntiPi1DetFbSecDrRt;
SIG_GROUP_ 2158952448 ODIDynDataMltRq_RSD 1 : ODDMR_ReqType ODDMR_FUCID ODDMR_DispMID ODDMR_DataID2Vld ODDMR_DataID2 ODDMR_DataID3Vld ODDMR_DataID3 ODDMR_DataID1 ODDMR_DataID4Vld ODDMR_DataID4 ODDMR_DataID5Vld ODDMR_DataID5;
